VERSION ""

NS_ :

BS_:
BU_: AerodynamicControl AuxiliaryHeater1 AuxiliaryHeater2 AuxiliaryValveControl AxleDrive1 AxleDrive2 AxleSteering BodyController BrakesDriveAxle1 BrakesDriveAxle2 BrakesSteerAxle BrakesSystemController CabController1 CabController2 CabDisplay1 ChassisController1 ChassisController2 ClimateControl1 ClimateControl2 ClutchUnit CommunicationUnitCellular CommunicationUnitRadio CommunicationUnitSatellite CruiseControl ElectricalChargingSystem ElectricalSystem EnduranceBrakingSystem Engine1 Engine2 EngineValveControl ExhaustEmissionController FanDriveController FileServer FuelSystem HeadwayController HitchControl HydraulicPumpController IgnitionController1 IgnitionController2 InformationSystem1 InstrumentCluster LightingOperatorControl ManagementComputer Node_0 Node_1 Node_10 Node_11 Node_12 Node_129 Node_13 Node_130 Node_133 Node_14 Node_15 Node_16 Node_17 Node_18 Node_19 Node_2 Node_20 Node_21 Node_22 Node_23 Node_24 Node_248 Node_249 Node_25 Node_250 Node_251 Node_26 Node_27 Node_28 Node_29 Node_3 Node_30 Node_31 Node_32 Node_33 Node_34 Node_35 Node_36 Node_37 Node_38 Node_39 Node_4 Node_40 Node_41 Node_42 Node_43 Node_44 Node_45 Node_46 Node_47 Node_48 Node_49 Node_5 Node_50 Node_51 Node_52 Node_53 Node_54 Node_55 Node_56 Node_57 Node_58 Node_59 Node_6 Node_60 Node_61 Node_62 Node_63 Node_64 Node_65 Node_66 Node_67 Node_68 Node_69 Node_7 Node_70 Node_71 Node_72 Node_73 Node_74 Node_75 Node_76 Node_77 Node_78 Node_79 Node_8 Node_80 Node_9 OffBoardDiagnosticTool1 OffBoardDiagnosticTool2 OffVehicleGateway OilSensor OnBoardDataLogger OnBoardDiagnosticUnit ParkingBrakeController PneumaticSystemController PowerTakeOff PowerTakeOffFront PropulsionBatteryCharger RampControl RearAxleSteeringController RetarderDriveline RetarderEngine RetarderExhaustEngine1 RetarderExhaustEngine2 SeatControl2 SeatController1 ShiftConsolePrimary ShiftConsoleSecondary StarterSystem SteeringColumnUnit SteeringController SuspensionDriveAxle1 SuspensionDriveAxle2 SuspensionSteerAxle SuspensionSystemController1 SuspensionSystemController2 TirePressureController TractorTrailerBridge1 Transmission1 Transmission2 TransmissionDisplay1 TransmissionDisplay2 TripRecorder Turbocharger VehicleDynamicStability VehicleNavigation VehicleSecurity VirtualTerminal WaterPumpController
BO_ 2147483648 VECTOR__INDEPENDENT_SIG_MSG: 0 Vector__XXX
   SG_ TrailerWeight : 0|16@1+ (2,0) [0|128510] "kg" Vector__XXX
   SG_ ReferenceTirePressSetting : 0|8@1+ (8,0) [0|2000] "kPa" Vector__XXX
   SG_ ReferenceTirePress : 0|8@1+ (8,0) [0|2000] "kPa" Vector__XXX
   SG_ TirePressThresholdDetection : 0|3@1+ (1,0) [0|7] "" Vector__XXX
   SG_ TireAirLeakageRate : 0|16@1+ (0.1,0) [0|6425.5] "Pa/s" Vector__XXX
   SG_ CTIWheelEndElectricalFault : 0|2@1+ (1,0) [0|3] "" Vector__XXX
   SG_ CTITireStatus : 0|2@1+ (1,0) [0|3] "" Vector__XXX
   SG_ CTIWheelSensorStatus : 0|2@1+ (1,0) [0|3] "" Vector__XXX
   SG_ TireTemp : 0|16@1+ (0.03125,-273) [-273|1734.97] "deg C" Vector__XXX
   SG_ TirePress : 0|8@1+ (4,0) [0|1000] "kPa" Vector__XXX

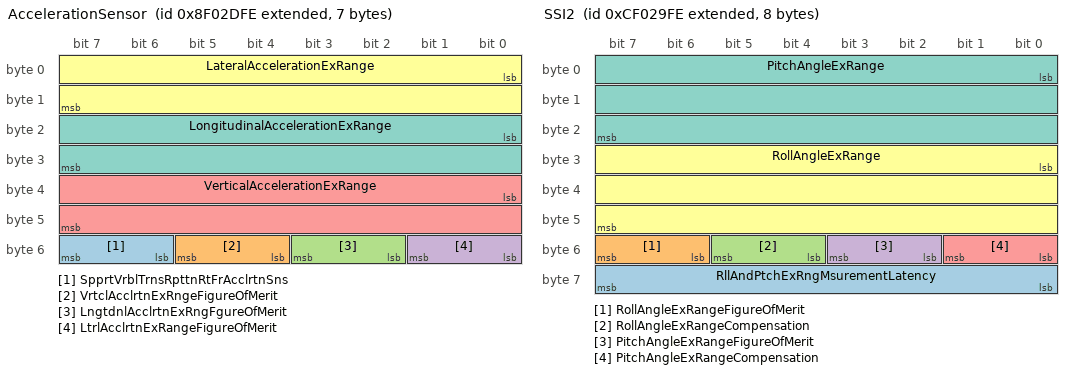
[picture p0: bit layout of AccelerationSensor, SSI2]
BO_ 2297441790 AccelerationSensor: 7 Vector__XXX
   SG_ SpprtVrblTrnsRpttnRtFrAcclrtnSns : 54|2@1+ (1,0) [0|3] "" Vector__XXX
   SG_ VrtclAcclrtnExRngeFigureOfMerit : 52|2@1+ (1,0) [0|3] "" Vector__XXX
   SG_ LngtdnlAcclrtnExRngFgureOfMerit : 50|2@1+ (1,0) [0|3] "" Vector__XXX
   SG_ LtrlAcclrtnExRangeFigureOfMerit : 48|2@1+ (1,0) [0|3] "" Vector__XXX
   SG_ VerticalAccelerationExRange : 32|16@1+ (0.01,-320) [-320|322.55] "m/s/s" Vector__XXX
   SG_ LateralAccelerationExRange : 0|16@1+ (0.01,-320) [-320|322.55] "m/s/s" Vector__XXX
   SG_ LongitudinalAccelerationExRange : 16|16@1+ (0.01,-320) [-320|322.55] "m/s/s" Vector__XXX

BO_ 2566712062 VEP4: 8 Vector__XXX
   SG_ HybrdBatteryPackRemainingCharge : 0|16@1+ (0.0025,0) [0|160.637] "%" Vector__XXX

BO_ 2364549630 SSI2: 8 Vector__XXX
   SG_ RllAndPtchExRngMsurementLatency : 56|8@1+ (0.5,0) [0|125] "ms" Vector__XXX
   SG_ RollAngleExRangeFigureOfMerit : 54|2@1+ (1,0) [0|3] "" Vector__XXX
   SG_ RollAngleExRangeCompensation : 52|2@1+ (1,0) [0|3] "" Vector__XXX
   SG_ PitchAngleExRangeFigureOfMerit : 50|2@1+ (1,0) [0|3] "" Vector__XXX
   SG_ PitchAngleExRangeCompensation : 48|2@1+ (1,0) [0|3] "" Vector__XXX
   SG_ RollAngleExRange : 24|24@1+ (3.05176e-05,-250) [-250|251] "deg" Vector__XXX
   SG_ PitchAngleExRange : 0|24@1+ (3.05176e-05,-250) [-250|251] "deg" Vector__XXX

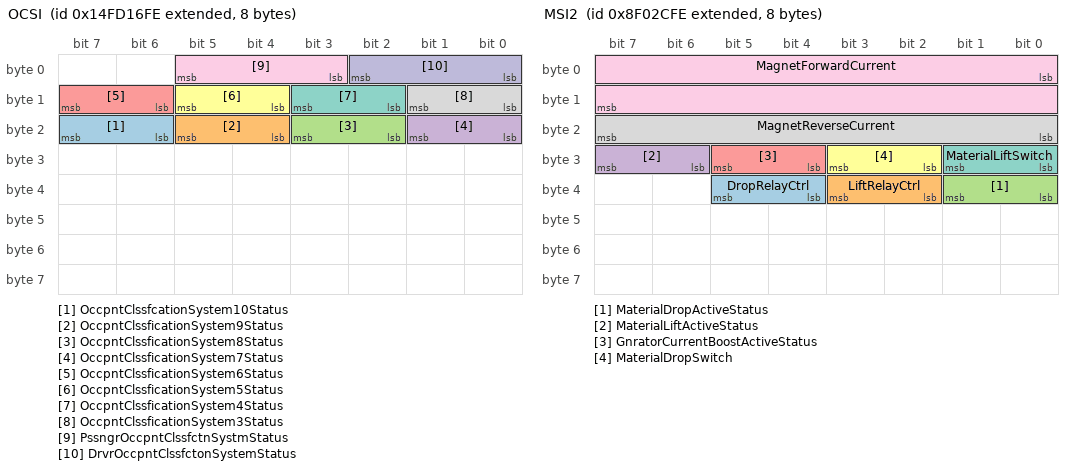
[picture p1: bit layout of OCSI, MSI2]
BO_ 2499614462 OCSI: 8 Vector__XXX
   SG_ OccpntClssfcationSystem10Status : 22|2@1+ (1,0) [0|3] "" Vector__XXX
   SG_ OccpntClssficationSystem9Status : 20|2@1+ (1,0) [0|3] "" Vector__XXX
   SG_ OccpntClssficationSystem8Status : 18|2@1+ (1,0) [0|3] "" Vector__XXX
   SG_ OccpntClssficationSystem7Status : 16|2@1+ (1,0) [0|3] "" Vector__XXX
   SG_ OccpntClssficationSystem6Status : 14|2@1+ (1,0) [0|3] "" Vector__XXX
   SG_ OccpntClssficationSystem5Status : 12|2@1+ (1,0) [0|3] "" Vector__XXX
   SG_ OccpntClssficationSystem4Status : 10|2@1+ (1,0) [0|3] "" Vector__XXX
   SG_ OccpntClssficationSystem3Status : 8|2@1+ (1,0) [0|3] "" Vector__XXX
   SG_ PssngrOccpntClssfctnSystmStatus : 3|3@1+ (1,0) [0|7] "" Vector__XXX
   SG_ DrvrOccpntClssfctonSystemStatus : 0|3@1+ (1,0) [0|7] "" Vector__XXX

BO_ 2560098046 NCS: 8 Vector__XXX
   SG_ CabNoiseCtrlTuningStatus : 2|4@1+ (1,0) [0|15] "" Vector__XXX
   SG_ CabNoiseCtrlStatus : 0|2@1+ (1,0) [0|3] "" Vector__XXX

BO_ 2560163582 NC1: 8 Vector__XXX
   SG_ CabNoiseCtrlTuningState : 2|3@1+ (1,0) [0|7] "" Vector__XXX
   SG_ CabNoiseCtrlState : 0|2@1+ (1,0) [0|3] "" Vector__XXX

BO_ 2297441534 MSI2: 8 Vector__XXX
   SG_ DropRelayCtrl : 36|2@1+ (1,0) [0|3] "" Vector__XXX
   SG_ LiftRelayCtrl : 34|2@1+ (1,0) [0|3] "" Vector__XXX
   SG_ MaterialDropActiveStatus : 32|2@1+ (1,0) [0|3] "" Vector__XXX
   SG_ MaterialLiftActiveStatus : 30|2@1+ (1,0) [0|3] "" Vector__XXX
   SG_ GnratorCurrentBoostActiveStatus : 28|2@1+ (1,0) [0|3] "" Vector__XXX
   SG_ MaterialDropSwitch : 26|2@1+ (1,0) [0|3] "" Vector__XXX
   SG_ MaterialLiftSwitch : 24|2@1+ (1,0) [0|3] "" Vector__XXX
   SG_ MagnetReverseCurrent : 16|8@1+ (1,0) [0|250] "A" Vector__XXX
   SG_ MagnetForwardCurrent : 0|16@1+ (1,0) [0|64255] "Amps" Vector__XXX

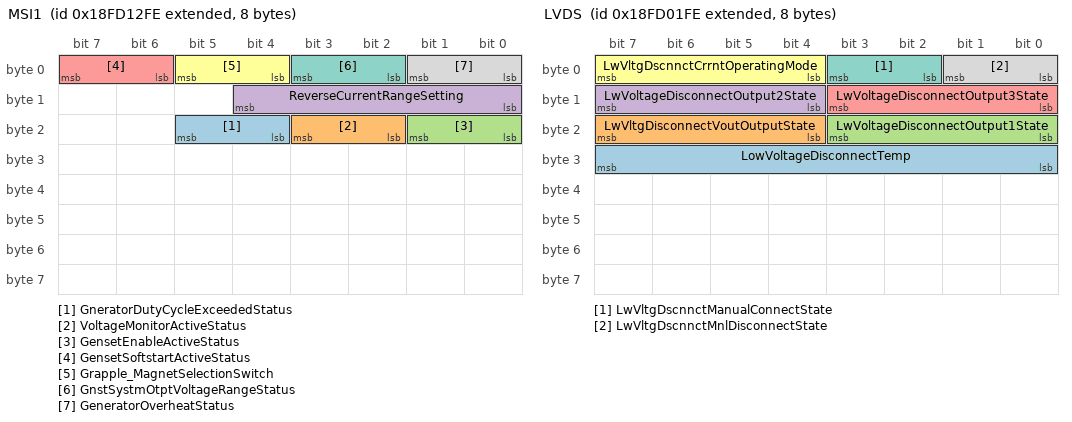
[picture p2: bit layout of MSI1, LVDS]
BO_ 2566722302 MSI1: 8 Vector__XXX
   SG_ GneratorDutyCycleExceededStatus : 20|2@1+ (1,0) [0|3] "" Vector__XXX
   SG_ VoltageMonitorActiveStatus : 18|2@1+ (1,0) [0|3] "" Vector__XXX
   SG_ GensetEnableActiveStatus : 16|2@1+ (1,0) [0|3] "" Vector__XXX
   SG_ ReverseCurrentRangeSetting : 8|5@1+ (1,0) [0|31] "" Vector__XXX
   SG_ GensetSoftstartActiveStatus : 6|2@1+ (1,0) [0|3] "" Vector__XXX
   SG_ Grapple_MagnetSelectionSwitch : 4|2@1+ (1,0) [0|3] "" Vector__XXX
   SG_ GnstSystmOtptVoltageRangeStatus : 2|2@1+ (1,0) [0|3] "" Vector__XXX
   SG_ GeneratorOverheatStatus : 0|2@1+ (1,0) [0|3] "" Vector__XXX

BO_ 2566722558 MSCI: 8 Vector__XXX
   SG_ MagnetRatedPower : 8|16@1+ (0.5,0) [0|32127.5] "kW" Vector__XXX
   SG_ MagnetBoostTime : 0|8@1+ (0.25,0) [0|62.5] "s" Vector__XXX

BO_ 2560032510 LVDSOM: 8 Vector__XXX
   SG_ LwVltgDscnnctDsredOperatingMode : 0|4@1+ (1,0) [0|15] "" Vector__XXX

BO_ 2566717950 LVDS: 8 Vector__XXX
   SG_ LowVoltageDisconnectTemp : 24|8@1+ (1,-40) [-40|210] "deg C" Vector__XXX
   SG_ LwVltgDisconnectVoutOutputState : 20|4@1+ (1,0) [0|15] "" Vector__XXX
   SG_ LwVoltageDisconnectOutput1State : 16|4@1+ (1,0) [0|15] "" Vector__XXX
   SG_ LwVoltageDisconnectOutput2State : 12|4@1+ (1,0) [0|15] "" Vector__XXX
   SG_ LwVoltageDisconnectOutput3State : 8|4@1+ (1,0) [0|15] "" Vector__XXX
   SG_ LwVltgDscnnctCrrntOperatingMode : 4|4@1+ (1,0) [0|15] "" Vector__XXX
   SG_ LwVltgDscnnctManualConnectState : 2|2@1+ (1,0) [0|3] "" Vector__XXX
   SG_ LwVltgDscnnctMnlDisconnectState : 0|2@1+ (1,0) [0|3] "" Vector__XXX

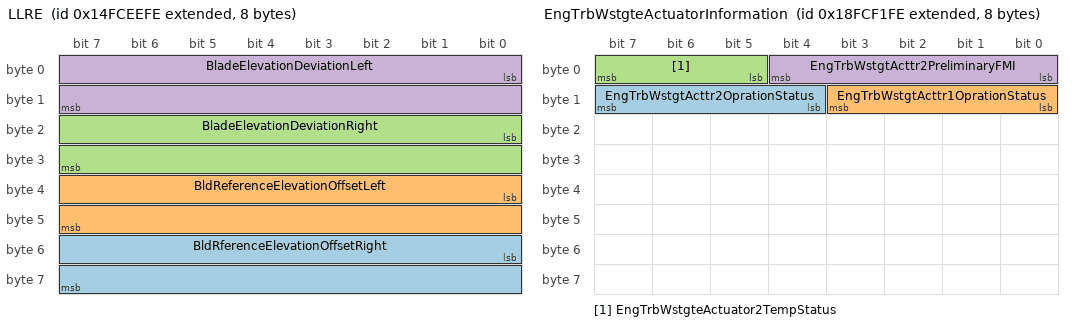
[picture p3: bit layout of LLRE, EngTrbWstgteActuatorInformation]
BO_ 2499604222 LLRE: 8 Vector__XXX
   SG_ BldRferenceElevationOffsetRight : 48|16@1+ (1,-32000) [-32000|32255] "mm" Vector__XXX
   SG_ BldReferenceElevationOffsetLeft : 32|16@1+ (1,-32000) [-32000|32255] "mm" Vector__XXX
   SG_ BladeElevationDeviationRight : 16|16@1+ (1,-32000) [-32000|32255] "mm" Vector__XXX
   SG_ BladeElevationDeviationLeft : 0|16@1+ (1,-32000) [-32000|32255] "mm" Vector__XXX

BO_ 2358902526 JLCM: 8 Vector__XXX
   SG_ Joystick3Lamp10Cmd : 58|2@1+ (1,0) [0|3] "" Vector__XXX
   SG_ Joystick3Lamp9Cmd : 56|2@1+ (1,0) [0|3] "" Vector__XXX
   SG_ Joystick3Lamp8Cmd : 54|2@1+ (1,0) [0|3] "" Vector__XXX
   SG_ Joystick3Lamp7Cmd : 52|2@1+ (1,0) [0|3] "" Vector__XXX
   SG_ Joystick3Lamp6Cmd : 50|2@1+ (1,0) [0|3] "" Vector__XXX
   SG_ Joystick3Lamp5Cmd : 48|2@1+ (1,0) [0|3] "" Vector__XXX
   SG_ Joystick3Lamp4Cmd : 46|2@1+ (1,0) [0|3] "" Vector__XXX
   SG_ Joystick3Lamp3Cmd : 44|2@1+ (1,0) [0|3] "" Vector__XXX
   SG_ Joystick3Lamp2Cmd : 42|2@1+ (1,0) [0|3] "" Vector__XXX
   SG_ Joystick3Lamp1Cmd : 40|2@1+ (1,0) [0|3] "" Vector__XXX
   SG_ Joystick2Lamp10Cmd : 38|2@1+ (1,0) [0|3] "" Vector__XXX
   SG_ Joystick2Lamp9Cmd : 36|2@1+ (1,0) [0|3] "" Vector__XXX
   SG_ Joystick2Lamp8Cmd : 34|2@1+ (1,0) [0|3] "" Vector__XXX
   SG_ Joystick2Lamp7Cmd : 32|2@1+ (1,0) [0|3] "" Vector__XXX
   SG_ Joystick2Lamp6Cmd : 30|2@1+ (1,0) [0|3] "" Vector__XXX
   SG_ Joystick2Lamp5Cmd : 28|2@1+ (1,0) [0|3] "" Vector__XXX
   SG_ Joystick2Lamp4Cmd : 26|2@1+ (1,0) [0|3] "" Vector__XXX
   SG_ Joystick2Lamp3Cmd : 24|2@1+ (1,0) [0|3] "" Vector__XXX
   SG_ Joystick2Lamp2Cmd : 22|2@1+ (1,0) [0|3] "" Vector__XXX
   SG_ Joystick2Lamp1Cmd : 20|2@1+ (1,0) [0|3] "" Vector__XXX
   SG_ Joystick1Lamp10Cmd : 18|2@1+ (1,0) [0|3] "" Vector__XXX
   SG_ Joystick1Lamp9Cmd : 16|2@1+ (1,0) [0|3] "" Vector__XXX
   SG_ Joystick1Lamp8Cmd : 14|2@1+ (1,0) [0|3] "" Vector__XXX
   SG_ Joystick1Lamp7Cmd : 12|2@1+ (1,0) [0|3] "" Vector__XXX
   SG_ Joystick1Lamp6Cmd : 10|2@1+ (1,0) [0|3] "" Vector__XXX
   SG_ Joystick1Lamp5Cmd : 8|2@1+ (1,0) [0|3] "" Vector__XXX
   SG_ Joystick1Lamp4Cmd : 6|2@1+ (1,0) [0|3] "" Vector__XXX
   SG_ Joystick1Lamp3Cmd : 4|2@1+ (1,0) [0|3] "" Vector__XXX
   SG_ Joystick1Lamp2Cmd : 2|2@1+ (1,0) [0|3] "" Vector__XXX
   SG_ Joystick1Lamp1Cmd : 0|2@1+ (1,0) [0|3] "" Vector__XXX

BO_ 2566711550 IVAC: 8 Vector__XXX
   SG_ IntkVlvActtnSystmOlPrss2SlndCtrl : 2|2@1+ (1,0) [0|3] "" Vector__XXX
   SG_ IntkVlvActtnSystmOlPrss1SlndCtrl : 0|2@1+ (1,0) [0|3] "" Vector__XXX

BO_ 2633832958 ILI: 200 Vector__XXX
   SG_ SpecialIgnitorLoop90Resistance : 1584|16@1+ (0.1,0) [0|6425.5] "ohm" Vector__XXX
   SG_ SpecialIgnitorLoop89Resistance : 1568|16@1+ (0.1,0) [0|6425.5] "ohm" Vector__XXX
   SG_ SpecialIgnitorLoop88Resistance : 1552|16@1+ (0.1,0) [0|6425.5] "ohm" Vector__XXX
   SG_ SpecialIgnitorLoop87Resistance : 1536|16@1+ (0.1,0) [0|6425.5] "ohm" Vector__XXX
   SG_ SpecialIgnitorLoop86Resistance : 1520|16@1+ (0.1,0) [0|6425.5] "ohm" Vector__XXX
   SG_ SpecialIgnitorLoop85Resistance : 1504|16@1+ (0.1,0) [0|6425.5] "ohm" Vector__XXX
   SG_ SpecialIgnitorLoop84Resistance : 1488|16@1+ (0.1,0) [0|6425.5] "ohm" Vector__XXX
   SG_ SpecialIgnitorLoop83Resistance : 1472|16@1+ (0.1,0) [0|6425.5] "ohm" Vector__XXX
   SG_ SpecialIgnitorLoop82Resistance : 1456|16@1+ (0.1,0) [0|6425.5] "ohm" Vector__XXX
   SG_ SpecialIgnitorLoop81Resistance : 1440|16@1+ (0.1,0) [0|6425.5] "ohm" Vector__XXX
   SG_ SpecialIgnitorLoop80Resistance : 1424|16@1+ (0.1,0) [0|6425.5] "ohm" Vector__XXX
   SG_ SpecialIgnitorLoop79Resistance : 1408|16@1+ (0.1,0) [0|6425.5] "ohm" Vector__XXX
   SG_ SpecialIgnitorLoop78Resistance : 1392|16@1+ (0.1,0) [0|6425.5] "ohm" Vector__XXX
   SG_ SpecialIgnitorLoop77Resistance : 1376|16@1+ (0.1,0) [0|6425.5] "ohm" Vector__XXX
   SG_ SpecialIgnitorLoop76Resistance : 1360|16@1+ (0.1,0) [0|6425.5] "ohm" Vector__XXX
   SG_ SpecialIgnitorLoop75Resistance : 1344|16@1+ (0.1,0) [0|6425.5] "ohm" Vector__XXX
   SG_ SpecialIgnitorLoop74Resistance : 1328|16@1+ (0.1,0) [0|6425.5] "ohm" Vector__XXX
   SG_ SpecialIgnitorLoop73Resistance : 1312|16@1+ (0.1,0) [0|6425.5] "ohm" Vector__XXX
   SG_ SpecialIgnitorLoop72Resistance : 1296|16@1+ (0.1,0) [0|6425.5] "ohm" Vector__XXX
   SG_ SpecialIgnitorLoop71Resistance : 1280|16@1+ (0.1,0) [0|6425.5] "ohm" Vector__XXX
   SG_ SpecialIgnitorLoop70Resistance : 1264|16@1+ (0.1,0) [0|6425.5] "ohm" Vector__XXX
   SG_ SpecialIgnitorLoop69Resistance : 1248|16@1+ (0.1,0) [0|6425.5] "ohm" Vector__XXX
   SG_ SpecialIgnitorLoop68Resistance : 1232|16@1+ (0.1,0) [0|6425.5] "ohm" Vector__XXX
   SG_ SpecialIgnitorLoop67Resistance : 1216|16@1+ (0.1,0) [0|6425.5] "ohm" Vector__XXX
   SG_ SpecialIgnitorLoop66Resistance : 1200|16@1+ (0.1,0) [0|6425.5] "ohm" Vector__XXX
   SG_ SpecialIgnitorLoop65Resistance : 1184|16@1+ (0.1,0) [0|6425.5] "ohm" Vector__XXX
   SG_ SpecialIgnitorLoop64Resistance : 1168|16@1+ (0.1,0) [0|6425.5] "ohm" Vector__XXX
   SG_ SpecialIgnitorLoop63Resistance : 1152|16@1+ (0.1,0) [0|6425.5] "ohm" Vector__XXX
   SG_ SpecialIgnitorLoop61Resistance : 1120|16@1+ (0.1,0) [0|6425.5] "ohm" Vector__XXX
   SG_ SpecialIgnitorLoop60Resistance : 1104|16@1+ (0.1,0) [0|6425.5] "ohm" Vector__XXX
   SG_ SpecialIgnitorLoop59Resistance : 1088|16@1+ (0.1,0) [0|6425.5] "ohm" Vector__XXX
   SG_ SpecialIgnitorLoop58Resistance : 1072|16@1+ (0.1,0) [0|6425.5] "ohm" Vector__XXX
   SG_ SpecialIgnitorLoop57Resistance : 1056|16@1+ (0.1,0) [0|6425.5] "ohm" Vector__XXX
   SG_ SpecialIgnitorLoop56Resistance : 1040|16@1+ (0.1,0) [0|6425.5] "ohm" Vector__XXX
   SG_ SpecialIgnitorLoop55Resistance : 1024|16@1+ (0.1,0) [0|6425.5] "ohm" Vector__XXX
   SG_ SpecialIgnitorLoop54Resistance : 1008|16@1+ (0.1,0) [0|6425.5] "ohm" Vector__XXX
   SG_ SpecialIgnitorLoop53Resistance : 992|16@1+ (0.1,0) [0|6425.5] "ohm" Vector__XXX
   SG_ SpecialIgnitorLoop52Resistance : 976|16@1+ (0.1,0) [0|6425.5] "ohm" Vector__XXX
   SG_ SpecialIgnitorLoop51Resistance : 960|16@1+ (0.1,0) [0|6425.5] "ohm" Vector__XXX
   SG_ SpecialIgnitorLoop50Resistance : 944|16@1+ (0.1,0) [0|6425.5] "ohm" Vector__XXX
   SG_ SpecialIgnitorLoop49Resistance : 928|16@1+ (0.1,0) [0|6425.5] "ohm" Vector__XXX
   SG_ SpecialIgnitorLoop48Resistance : 912|16@1+ (0.1,0) [0|6425.5] "ohm" Vector__XXX
   SG_ SpecialIgnitorLoop47Resistance : 896|16@1+ (0.1,0) [0|6425.5] "ohm" Vector__XXX
   SG_ SpecialIgnitorLoop46Resistance : 880|16@1+ (0.1,0) [0|6425.5] "ohm" Vector__XXX
   SG_ SpecialIgnitorLoop45Resistance : 864|16@1+ (0.1,0) [0|6425.5] "ohm" Vector__XXX
   SG_ SpecialIgnitorLoop44Resistance : 848|16@1+ (0.1,0) [0|6425.5] "ohm" Vector__XXX
   SG_ SpecialIgnitorLoop43Resistance : 832|16@1+ (0.1,0) [0|6425.5] "ohm" Vector__XXX
   SG_ SpecialIgnitorLoop42Resistance : 816|16@1+ (0.1,0) [0|6425.5] "ohm" Vector__XXX
   SG_ SpecialIgnitorLoop41Resistance : 800|16@1+ (0.1,0) [0|6425.5] "ohm" Vector__XXX
   SG_ SpecialIgnitorLoop40Resistance : 784|16@1+ (0.1,0) [0|6425.5] "ohm" Vector__XXX
   SG_ SpecialIgnitorLoop39Resistance : 768|16@1+ (0.1,0) [0|6425.5] "ohm" Vector__XXX
   SG_ SpecialIgnitorLoop38Resistance : 752|16@1+ (0.1,0) [0|6425.5] "ohm" Vector__XXX
   SG_ SpecialIgnitorLoop37Resistance : 736|16@1+ (0.1,0) [0|6425.5] "ohm" Vector__XXX
   SG_ SpecialIgnitorLoop36Resistance : 720|16@1+ (0.1,0) [0|6425.5] "ohm" Vector__XXX
   SG_ SpecialIgnitorLoop35Resistance : 704|16@1+ (0.1,0) [0|6425.5] "ohm" Vector__XXX
   SG_ SpecialIgnitorLoop34Resistance : 688|16@1+ (0.1,0) [0|6425.5] "ohm" Vector__XXX
   SG_ SpecialIgnitorLoop33Resistance : 672|16@1+ (0.1,0) [0|6425.5] "ohm" Vector__XXX
   SG_ SpecialIgnitorLoop32Resistance : 656|16@1+ (0.1,0) [0|6425.5] "ohm" Vector__XXX
   SG_ SpecialIgnitorLoop31Resistance : 640|16@1+ (0.1,0) [0|6425.5] "ohm" Vector__XXX
   SG_ SpecialIgnitorLoop30Resistance : 624|16@1+ (0.1,0) [0|6425.5] "ohm" Vector__XXX
   SG_ SpecialIgnitorLoop29Resistance : 608|16@1+ (0.1,0) [0|6425.5] "ohm" Vector__XXX
   SG_ SpecialIgnitorLoop28Resistance : 592|16@1+ (0.1,0) [0|6425.5] "ohm" Vector__XXX
   SG_ SpecialIgnitorLoop27Resistance : 576|16@1+ (0.1,0) [0|6425.5] "ohm" Vector__XXX
   SG_ SpecialIgnitorLoop26Resistance : 560|16@1+ (0.1,0) [0|6425.5] "ohm" Vector__XXX
   SG_ SpecialIgnitorLoop25Resistance : 544|16@1+ (0.1,0) [0|6425.5] "ohm" Vector__XXX
   SG_ SpecialIgnitorLoop24Resistance : 528|16@1+ (0.1,0) [0|6425.5] "ohm" Vector__XXX
   SG_ SpecialIgnitorLoop23Resistance : 512|16@1+ (0.1,0) [0|6425.5] "ohm" Vector__XXX
   SG_ SpecialIgnitorLoop22Resistance : 496|16@1+ (0.1,0) [0|6425.5] "ohm" Vector__XXX
   SG_ SpecialIgnitorLoop21Resistance : 480|16@1+ (0.1,0) [0|6425.5] "ohm" Vector__XXX
   SG_ SpecialIgnitorLoop20Resistance : 464|16@1+ (0.1,0) [0|6425.5] "ohm" Vector__XXX
   SG_ SpecialIgnitorLoop19Resistance : 448|16@1+ (0.1,0) [0|6425.5] "ohm" Vector__XXX
   SG_ SpecialIgnitorLoop18Resistance : 432|16@1+ (0.1,0) [0|6425.5] "ohm" Vector__XXX
   SG_ SpecialIgnitorLoop17Resistance : 416|16@1+ (0.1,0) [0|6425.5] "ohm" Vector__XXX
   SG_ SpecialIgnitorLoop16Resistance : 400|16@1+ (0.1,0) [0|6425.5] "ohm" Vector__XXX
   SG_ SpecialIgnitorLoop15Resistance : 384|16@1+ (0.1,0) [0|6425.5] "ohm" Vector__XXX
   SG_ SpecialIgnitorLoop14Resistance : 368|16@1+ (0.1,0) [0|6425.5] "ohm" Vector__XXX
   SG_ SpecialIgnitorLoop13Resistance : 352|16@1+ (0.1,0) [0|6425.5] "ohm" Vector__XXX
   SG_ SpecialIgnitorLoop12Resistance : 336|16@1+ (0.1,0) [0|6425.5] "ohm" Vector__XXX
   SG_ SpecialIgnitorLoop11Resistance : 320|16@1+ (0.1,0) [0|6425.5] "ohm" Vector__XXX
   SG_ SpecialIgnitorLoop10Resistance : 304|16@1+ (0.1,0) [0|6425.5] "ohm" Vector__XXX
   SG_ SpecialIgnitorLoop9Resistance : 288|16@1+ (0.1,0) [0|6425.5] "ohm" Vector__XXX
   SG_ SpecialIgnitorLoop8Resistance : 272|16@1+ (0.1,0) [0|6425.5] "ohm" Vector__XXX
   SG_ SpecialIgnitorLoop7Resistance : 256|16@1+ (0.1,0) [0|6425.5] "ohm" Vector__XXX
   SG_ SpecialIgnitorLoop6Resistance : 240|16@1+ (0.1,0) [0|6425.5] "ohm" Vector__XXX
   SG_ SpecialIgnitorLoop5Resistance : 224|16@1+ (0.1,0) [0|6425.5] "ohm" Vector__XXX
   SG_ SpecialIgnitorLoop4Resistance : 208|16@1+ (0.1,0) [0|6425.5] "ohm" Vector__XXX
   SG_ SpecialIgnitorLoop3Resistance : 192|16@1+ (0.1,0) [0|6425.5] "ohm" Vector__XXX
   SG_ SpecialIgnitorLoop2Resistance : 176|16@1+ (0.1,0) [0|6425.5] "ohm" Vector__XXX
   SG_ SpecialIgnitorLoop1Resistance : 160|16@1+ (0.1,0) [0|6425.5] "ohm" Vector__XXX
   SG_ SdBgIgnitorLoop2RightResistance : 144|16@1+ (0.1,0) [0|6425.5] "ohm" Vector__XXX
   SG_ SdBgIgnitorLoop1RightResistance : 128|16@1+ (0.1,0) [0|6425.5] "ohm" Vector__XXX
   SG_ SdBagIgnitorLoop2LeftResistance : 112|16@1+ (0.1,0) [0|6425.5] "ohm" Vector__XXX
   SG_ SdBagIgnitorLoop1LeftResistance : 96|16@1+ (0.1,0) [0|6425.5] "ohm" Vector__XXX
   SG_ PssngrBltTnsnrIgntrLpResistance : 80|16@1+ (0.1,0) [0|6425.5] "ohm" Vector__XXX
   SG_ DrvrBltTnsnrIgntrLoopResistance : 64|16@1+ (0.1,0) [0|6425.5] "ohm" Vector__XXX
   SG_ PssngrArbgIgntrLp2ndStgRsstance : 48|16@1+ (0.1,0) [0|6425.5] "ohm" Vector__XXX
   SG_ DrvrArbgIgntrLp2ndStgResistance : 32|16@1+ (0.1,0) [0|6425.5] "ohm" Vector__XXX
   SG_ PssngrArbgIgntrLp1stStgRsstance : 16|16@1+ (0.1,0) [0|6425.5] "ohm" Vector__XXX
   SG_ DrvrArbgIgntrLp1stStgResistance : 0|16@1+ (0.1,0) [0|6425.5] "ohm" Vector__XXX

BO_ 2566719998 HRLFC: 8 Vector__XXX
   SG_ HighResolutionEngTotalFuelUsed : 32|32@1+ (0.001,0) [0|4.21108e+06] "L" Vector__XXX
   SG_ HighResolutionEngTripFuel : 0|32@1+ (0.001,0) [0|4.21108e+06] "L" Vector__XXX

BO_ 2565877502 EngTrboWastegateActuatorCtrlCmd: 8 Vector__XXX
   SG_ EngTurboWastegateActuator2Cmd : 16|16@1+ (0.0025,0) [0|160.637] "%" Vector__XXX
   SG_ EngTurboWastegateActuator1Cmd : 0|16@1+ (0.0025,0) [0|160.637] "%" Vector__XXX

BO_ 2566713854 EngTrbWstgteActuatorInformation: 8 Vector__XXX
   SG_ EngTrbWstgtActtr2OprationStatus : 12|4@1+ (1,0) [0|15] "" Vector__XXX
   SG_ EngTrbWstgtActtr1OprationStatus : 8|4@1+ (1,0) [0|15] "" Vector__XXX
   SG_ EngTrbWstgteActuator2TempStatus : 5|3@1+ (1,0) [0|7] "" Vector__XXX
   SG_ EngTrbWstgtActtr2PreliminaryFMI : 0|5@1+ (1,0) [0|31] "" Vector__XXX

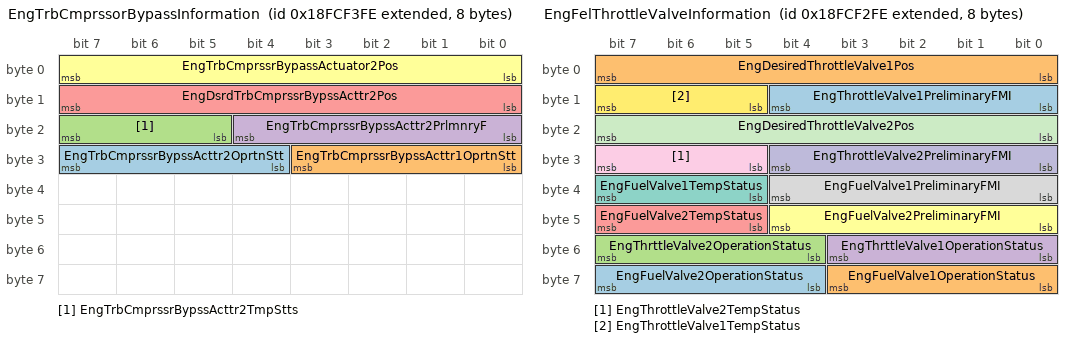
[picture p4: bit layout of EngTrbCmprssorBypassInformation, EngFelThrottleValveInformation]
BO_ 2566714366 EngTrbCmprssorBypassInformation: 8 Vector__XXX
   SG_ EngTrbCmprssrBypssActtr2OprtnStt : 28|4@1+ (1,0) [0|15] "" Vector__XXX
   SG_ EngTrbCmprssrBypssActtr1OprtnStt : 24|4@1+ (1,0) [0|15] "" Vector__XXX
   SG_ EngTrbCmprssrBypssActtr2TmpStts : 21|3@1+ (1,0) [0|7] "" Vector__XXX
   SG_ EngTrbCmprssrBypssActtr2PrlmnryF : 16|5@1+ (1,0) [0|31] "" Vector__XXX
   SG_ EngDsrdTrbCmprssrBypssActtr2Pos : 8|8@1+ (0.4,0) [0|100] "%" Vector__XXX
   SG_ EngTrbCmprssrBypassActuator2Pos : 0|8@1+ (0.4,0) [0|100] "%" Vector__XXX

BO_ 2566714110 EngFelThrottleValveInformation: 8 Vector__XXX
   SG_ EngFuelValve2OperationStatus : 60|4@1+ (1,0) [0|15] "" Vector__XXX
   SG_ EngFuelValve1OperationStatus : 56|4@1+ (1,0) [0|15] "" Vector__XXX
   SG_ EngThrttleValve2OperationStatus : 52|4@1+ (1,0) [0|15] "" Vector__XXX
   SG_ EngThrttleValve1OperationStatus : 48|4@1+ (1,0) [0|15] "" Vector__XXX
   SG_ EngFuelValve2TempStatus : 45|3@1+ (1,0) [0|7] "" Vector__XXX
   SG_ EngFuelValve2PreliminaryFMI : 40|5@1+ (1,0) [0|31] "" Vector__XXX
   SG_ EngFuelValve1TempStatus : 37|3@1+ (1,0) [0|7] "" Vector__XXX
   SG_ EngFuelValve1PreliminaryFMI : 32|5@1+ (1,0) [0|31] "" Vector__XXX
   SG_ EngThrottleValve2TempStatus : 29|3@1+ (1,0) [0|7] "" Vector__XXX
   SG_ EngThrottleValve2PreliminaryFMI : 24|5@1+ (1,0) [0|31] "" Vector__XXX
   SG_ EngDesiredThrottleValve2Pos : 16|8@1+ (0.4,0) [0|100] "%" Vector__XXX
   SG_ EngThrottleValve1TempStatus : 13|3@1+ (1,0) [0|7] "" Vector__XXX
   SG_ EngThrottleValve1PreliminaryFMI : 8|5@1+ (1,0) [0|31] "" Vector__XXX
   SG_ EngDesiredThrottleValve1Pos : 0|8@1+ (0.4,0) [0|100] "%" Vector__XXX

BO_ 2566717438 ET5: 8 Vector__XXX
   SG_ EngExhstGsRcrcltn2MxrIntakeTemp : 16|16@1+ (0.03125,-273) [-273|1734.97] "deg C" Vector__XXX
   SG_ EngExhaustGasRecirculation2Temp : 0|16@1+ (0.03125,-273) [-273|1734.97] "deg C" Vector__XXX

BO_ 2633828606 EOM: 8 Vector__XXX
   SG_ EngOilRelativeDielectricity : 32|16@1+ (0.00012207,0) [0|7.844] "" Vector__XXX
   SG_ EngOilDensity : 16|16@1+ (3.052e-05,0) [0|1.961] "g/cc" Vector__XXX
   SG_ EngOilViscosity : 0|16@1+ (0.015625,0) [0|1003.98] "Cp" Vector__XXX

BO_ 2499607550 EMAP: 8 Vector__XXX
   SG_ EngExhstMnfldBnk2FlwBlncVlvActtr : 16|16@1+ (0.0025,0) [0|160.637] "%" Vector__XXX
   SG_ EngExhstMnfldBnk1FlwBlncVlvActtr : 0|16@1+ (0.0025,0) [0|160.637] "%" Vector__XXX

BO_ 2633825534 EMAC: 8 Vector__XXX
   SG_ EngExhstMnfldBnk2FlwBlncVlv_0000 : 16|16@1+ (0.0025,0) [0|160.637] "%" Vector__XXX
   SG_ EngExhstMnfldBnk1FlwBlncVlv_0000 : 0|16@1+ (0.0025,0) [0|160.637] "%" Vector__XXX

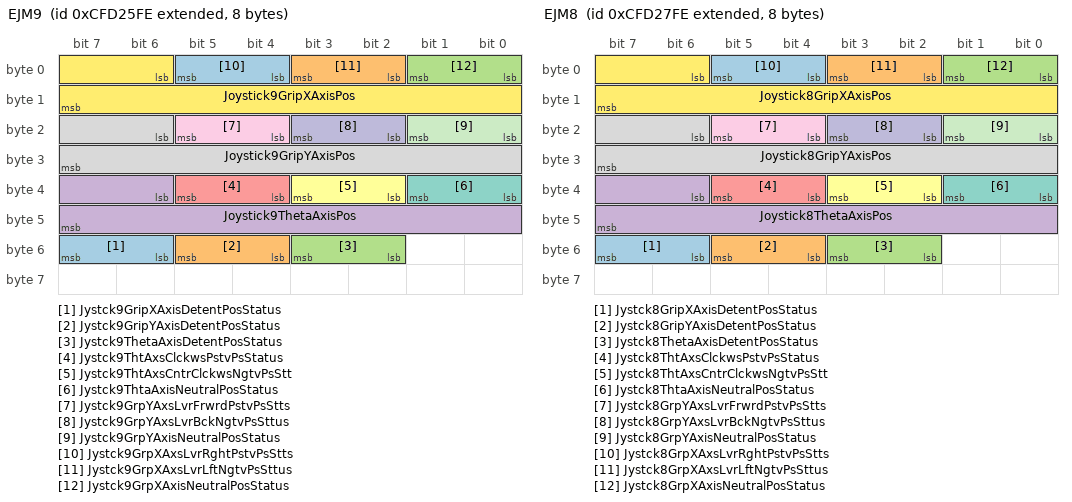
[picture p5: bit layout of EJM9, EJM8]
BO_ 2365400574 EJM9: 8 Vector__XXX
   SG_ Jystck9GripXAxisDetentPosStatus : 54|2@1+ (1,0) [0|3] "" Vector__XXX
   SG_ Jystck9GripYAxisDetentPosStatus : 52|2@1+ (1,0) [0|3] "" Vector__XXX
   SG_ Jystck9ThetaAxisDetentPosStatus : 50|2@1+ (1,0) [0|3] "" Vector__XXX
   SG_ Joystick9ThetaAxisPos : 38|10@1+ (0.1,0) [0|102] "%" Vector__XXX
   SG_ Jystck9ThtAxsClckwsPstvPsStatus : 36|2@1+ (1,0) [0|3] "" Vector__XXX
   SG_ Jystck9ThtAxsCntrClckwsNgtvPsStt : 34|2@1+ (1,0) [0|3] "" Vector__XXX
   SG_ Jystck9ThtaAxisNeutralPosStatus : 32|2@1+ (1,0) [0|3] "" Vector__XXX
   SG_ Joystick9GripYAxisPos : 22|10@1+ (0.1,0) [0|102] "%" Vector__XXX
   SG_ Jystck9GrpYAxsLvrFrwrdPstvPsStts : 20|2@1+ (1,0) [0|3] "" Vector__XXX
   SG_ Jystck9GrpYAxsLvrBckNgtvPsSttus : 18|2@1+ (1,0) [0|3] "" Vector__XXX
   SG_ Jystck9GrpYAxisNeutralPosStatus : 16|2@1+ (1,0) [0|3] "" Vector__XXX
   SG_ Joystick9GripXAxisPos : 6|10@1+ (0.1,0) [0|102] "%" Vector__XXX
   SG_ Jystck9GrpXAxsLvrRghtPstvPsStts : 4|2@1+ (1,0) [0|3] "" Vector__XXX
   SG_ Jystck9GrpXAxsLvrLftNgtvPsSttus : 2|2@1+ (1,0) [0|3] "" Vector__XXX
   SG_ Jystck9GrpXAxisNeutralPosStatus : 0|2@1+ (1,0) [0|3] "" Vector__XXX

BO_ 2365401086 EJM8: 8 Vector__XXX
   SG_ Jystck8GripXAxisDetentPosStatus : 54|2@1+ (1,0) [0|3] "" Vector__XXX
   SG_ Jystck8GripYAxisDetentPosStatus : 52|2@1+ (1,0) [0|3] "" Vector__XXX
   SG_ Jystck8ThetaAxisDetentPosStatus : 50|2@1+ (1,0) [0|3] "" Vector__XXX
   SG_ Joystick8ThetaAxisPos : 38|10@1+ (0.1,0) [0|102] "%" Vector__XXX
   SG_ Jystck8ThtAxsClckwsPstvPsStatus : 36|2@1+ (1,0) [0|3] "" Vector__XXX
   SG_ Jystck8ThtAxsCntrClckwsNgtvPsStt : 34|2@1+ (1,0) [0|3] "" Vector__XXX
   SG_ Jystck8ThtaAxisNeutralPosStatus : 32|2@1+ (1,0) [0|3] "" Vector__XXX
   SG_ Joystick8GripYAxisPos : 22|10@1+ (0.1,0) [0|102] "%" Vector__XXX
   SG_ Jystck8GrpYAxsLvrFrwrdPstvPsStts : 20|2@1+ (1,0) [0|3] "" Vector__XXX
   SG_ Jystck8GrpYAxsLvrBckNgtvPsSttus : 18|2@1+ (1,0) [0|3] "" Vector__XXX
   SG_ Jystck8GrpYAxisNeutralPosStatus : 16|2@1+ (1,0) [0|3] "" Vector__XXX
   SG_ Joystick8GripXAxisPos : 6|10@1+ (0.1,0) [0|102] "%" Vector__XXX
   SG_ Jystck8GrpXAxsLvrRghtPstvPsStts : 4|2@1+ (1,0) [0|3] "" Vector__XXX
   SG_ Jystck8GrpXAxsLvrLftNgtvPsSttus : 2|2@1+ (1,0) [0|3] "" Vector__XXX
   SG_ Jystck8GrpXAxisNeutralPosStatus : 0|2@1+ (1,0) [0|3] "" Vector__XXX

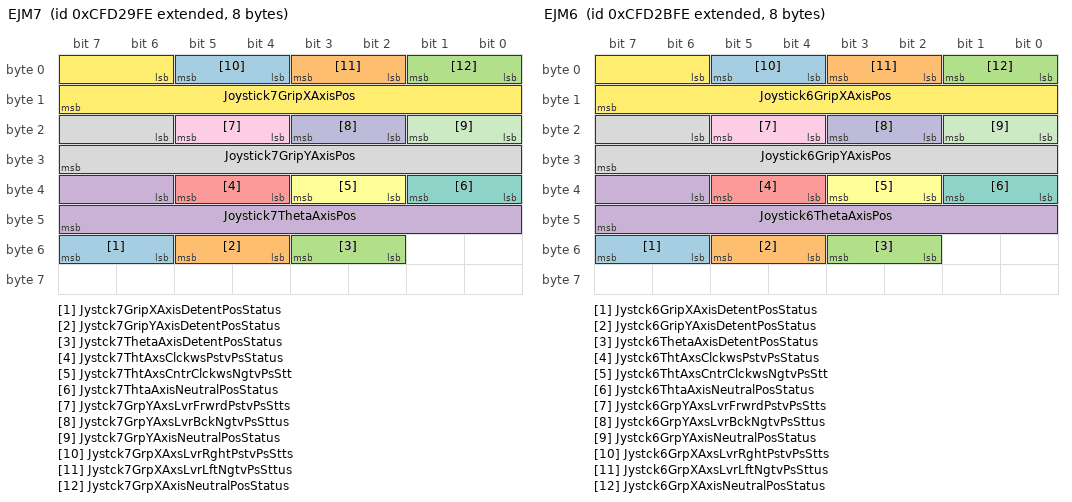
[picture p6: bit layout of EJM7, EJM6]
BO_ 2365401598 EJM7: 8 Vector__XXX
   SG_ Jystck7GripXAxisDetentPosStatus : 54|2@1+ (1,0) [0|3] "" Vector__XXX
   SG_ Jystck7GripYAxisDetentPosStatus : 52|2@1+ (1,0) [0|3] "" Vector__XXX
   SG_ Jystck7ThetaAxisDetentPosStatus : 50|2@1+ (1,0) [0|3] "" Vector__XXX
   SG_ Joystick7ThetaAxisPos : 38|10@1+ (0.1,0) [0|102] "%" Vector__XXX
   SG_ Jystck7ThtAxsClckwsPstvPsStatus : 36|2@1+ (1,0) [0|3] "" Vector__XXX
   SG_ Jystck7ThtAxsCntrClckwsNgtvPsStt : 34|2@1+ (1,0) [0|3] "" Vector__XXX
   SG_ Jystck7ThtaAxisNeutralPosStatus : 32|2@1+ (1,0) [0|3] "" Vector__XXX
   SG_ Joystick7GripYAxisPos : 22|10@1+ (0.1,0) [0|102] "%" Vector__XXX
   SG_ Jystck7GrpYAxsLvrFrwrdPstvPsStts : 20|2@1+ (1,0) [0|3] "" Vector__XXX
   SG_ Jystck7GrpYAxsLvrBckNgtvPsSttus : 18|2@1+ (1,0) [0|3] "" Vector__XXX
   SG_ Jystck7GrpYAxisNeutralPosStatus : 16|2@1+ (1,0) [0|3] "" Vector__XXX
   SG_ Joystick7GripXAxisPos : 6|10@1+ (0.1,0) [0|102] "%" Vector__XXX
   SG_ Jystck7GrpXAxsLvrRghtPstvPsStts : 4|2@1+ (1,0) [0|3] "" Vector__XXX
   SG_ Jystck7GrpXAxsLvrLftNgtvPsSttus : 2|2@1+ (1,0) [0|3] "" Vector__XXX
   SG_ Jystck7GrpXAxisNeutralPosStatus : 0|2@1+ (1,0) [0|3] "" Vector__XXX

BO_ 2365402110 EJM6: 8 Vector__XXX
   SG_ Jystck6GripXAxisDetentPosStatus : 54|2@1+ (1,0) [0|3] "" Vector__XXX
   SG_ Jystck6GripYAxisDetentPosStatus : 52|2@1+ (1,0) [0|3] "" Vector__XXX
   SG_ Jystck6ThetaAxisDetentPosStatus : 50|2@1+ (1,0) [0|3] "" Vector__XXX
   SG_ Joystick6ThetaAxisPos : 38|10@1+ (0.1,0) [0|102] "%" Vector__XXX
   SG_ Jystck6ThtAxsClckwsPstvPsStatus : 36|2@1+ (1,0) [0|3] "" Vector__XXX
   SG_ Jystck6ThtAxsCntrClckwsNgtvPsStt : 34|2@1+ (1,0) [0|3] "" Vector__XXX
   SG_ Jystck6ThtaAxisNeutralPosStatus : 32|2@1+ (1,0) [0|3] "" Vector__XXX
   SG_ Joystick6GripYAxisPos : 22|10@1+ (0.1,0) [0|102] "%" Vector__XXX
   SG_ Jystck6GrpYAxsLvrFrwrdPstvPsStts : 20|2@1+ (1,0) [0|3] "" Vector__XXX
   SG_ Jystck6GrpYAxsLvrBckNgtvPsSttus : 18|2@1+ (1,0) [0|3] "" Vector__XXX
   SG_ Jystck6GrpYAxisNeutralPosStatus : 16|2@1+ (1,0) [0|3] "" Vector__XXX
   SG_ Joystick6GripXAxisPos : 6|10@1+ (0.1,0) [0|102] "%" Vector__XXX
   SG_ Jystck6GrpXAxsLvrRghtPstvPsStts : 4|2@1+ (1,0) [0|3] "" Vector__XXX
   SG_ Jystck6GrpXAxsLvrLftNgtvPsSttus : 2|2@1+ (1,0) [0|3] "" Vector__XXX
   SG_ Jystck6GrpXAxisNeutralPosStatus : 0|2@1+ (1,0) [0|3] "" Vector__XXX

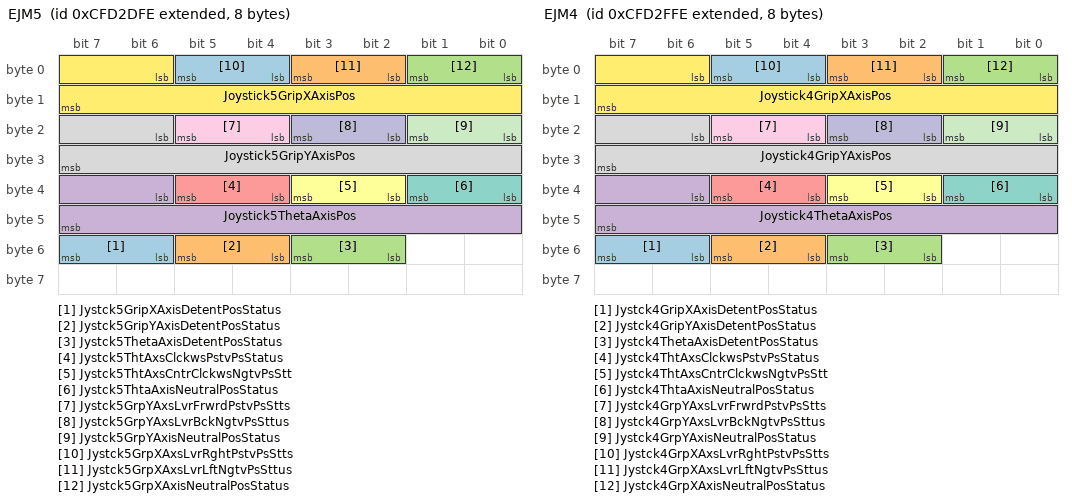
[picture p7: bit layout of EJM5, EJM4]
BO_ 2365402622 EJM5: 8 Vector__XXX
   SG_ Jystck5GripXAxisDetentPosStatus : 54|2@1+ (1,0) [0|3] "" Vector__XXX
   SG_ Jystck5GripYAxisDetentPosStatus : 52|2@1+ (1,0) [0|3] "" Vector__XXX
   SG_ Jystck5ThetaAxisDetentPosStatus : 50|2@1+ (1,0) [0|3] "" Vector__XXX
   SG_ Joystick5ThetaAxisPos : 38|10@1+ (0.1,0) [0|102] "%" Vector__XXX
   SG_ Jystck5ThtAxsClckwsPstvPsStatus : 36|2@1+ (1,0) [0|3] "" Vector__XXX
   SG_ Jystck5ThtAxsCntrClckwsNgtvPsStt : 34|2@1+ (1,0) [0|3] "" Vector__XXX
   SG_ Jystck5ThtaAxisNeutralPosStatus : 32|2@1+ (1,0) [0|3] "" Vector__XXX
   SG_ Joystick5GripYAxisPos : 22|10@1+ (0.1,0) [0|102] "%" Vector__XXX
   SG_ Jystck5GrpYAxsLvrFrwrdPstvPsStts : 20|2@1+ (1,0) [0|3] "" Vector__XXX
   SG_ Jystck5GrpYAxsLvrBckNgtvPsSttus : 18|2@1+ (1,0) [0|3] "" Vector__XXX
   SG_ Jystck5GrpYAxisNeutralPosStatus : 16|2@1+ (1,0) [0|3] "" Vector__XXX
   SG_ Joystick5GripXAxisPos : 6|10@1+ (0.1,0) [0|102] "%" Vector__XXX
   SG_ Jystck5GrpXAxsLvrRghtPstvPsStts : 4|2@1+ (1,0) [0|3] "" Vector__XXX
   SG_ Jystck5GrpXAxsLvrLftNgtvPsSttus : 2|2@1+ (1,0) [0|3] "" Vector__XXX
   SG_ Jystck5GrpXAxisNeutralPosStatus : 0|2@1+ (1,0) [0|3] "" Vector__XXX

BO_ 2365403134 EJM4: 8 Vector__XXX
   SG_ Jystck4GripXAxisDetentPosStatus : 54|2@1+ (1,0) [0|3] "" Vector__XXX
   SG_ Jystck4GripYAxisDetentPosStatus : 52|2@1+ (1,0) [0|3] "" Vector__XXX
   SG_ Jystck4ThetaAxisDetentPosStatus : 50|2@1+ (1,0) [0|3] "" Vector__XXX
   SG_ Joystick4ThetaAxisPos : 38|10@1+ (0.1,0) [0|102] "%" Vector__XXX
   SG_ Jystck4ThtAxsClckwsPstvPsStatus : 36|2@1+ (1,0) [0|3] "" Vector__XXX
   SG_ Jystck4ThtAxsCntrClckwsNgtvPsStt : 34|2@1+ (1,0) [0|3] "" Vector__XXX
   SG_ Jystck4ThtaAxisNeutralPosStatus : 32|2@1+ (1,0) [0|3] "" Vector__XXX
   SG_ Joystick4GripYAxisPos : 22|10@1+ (0.1,0) [0|102] "%" Vector__XXX
   SG_ Jystck4GrpYAxsLvrFrwrdPstvPsStts : 20|2@1+ (1,0) [0|3] "" Vector__XXX
   SG_ Jystck4GrpYAxsLvrBckNgtvPsSttus : 18|2@1+ (1,0) [0|3] "" Vector__XXX
   SG_ Jystck4GrpYAxisNeutralPosStatus : 16|2@1+ (1,0) [0|3] "" Vector__XXX
   SG_ Joystick4GripXAxisPos : 6|10@1+ (0.1,0) [0|102] "%" Vector__XXX
   SG_ Jystck4GrpXAxsLvrRghtPstvPsStts : 4|2@1+ (1,0) [0|3] "" Vector__XXX
   SG_ Jystck4GrpXAxsLvrLftNgtvPsSttus : 2|2@1+ (1,0) [0|3] "" Vector__XXX
   SG_ Jystck4GrpXAxisNeutralPosStatus : 0|2@1+ (1,0) [0|3] "" Vector__XXX

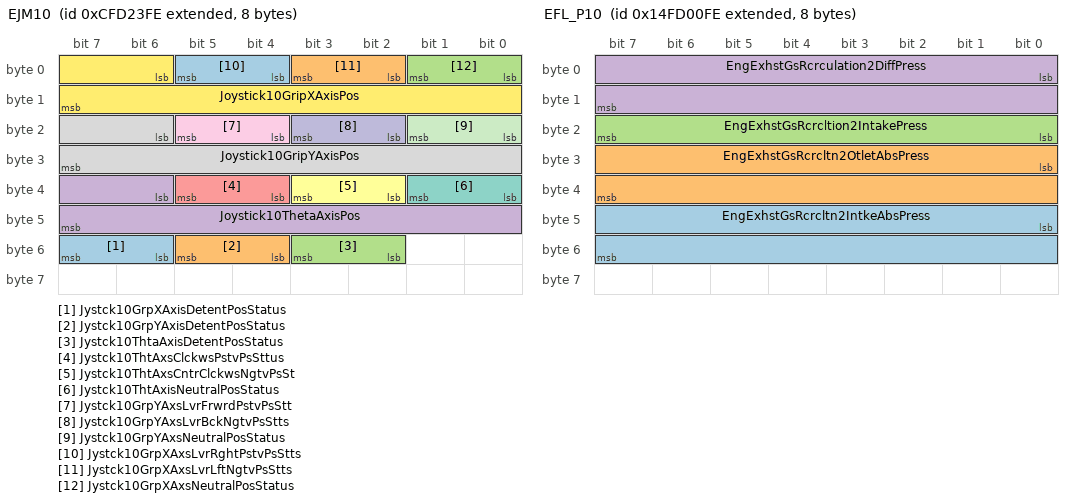
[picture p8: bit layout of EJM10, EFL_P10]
BO_ 2365400062 EJM10: 8 Vector__XXX
   SG_ Jystck10GrpXAxisDetentPosStatus : 54|2@1+ (1,0) [0|3] "" Vector__XXX
   SG_ Jystck10GrpYAxisDetentPosStatus : 52|2@1+ (1,0) [0|3] "" Vector__XXX
   SG_ Jystck10ThtaAxisDetentPosStatus : 50|2@1+ (1,0) [0|3] "" Vector__XXX
   SG_ Joystick10ThetaAxisPos : 38|10@1+ (0.1,0) [0|102] "%" Vector__XXX
   SG_ Jystck10ThtAxsClckwsPstvPsSttus : 36|2@1+ (1,0) [0|3] "" Vector__XXX
   SG_ Jystck10ThtAxsCntrClckwsNgtvPsSt : 34|2@1+ (1,0) [0|3] "" Vector__XXX
   SG_ Jystck10ThtAxisNeutralPosStatus : 32|2@1+ (1,0) [0|3] "" Vector__XXX
   SG_ Joystick10GripYAxisPos : 22|10@1+ (0.1,0) [0|102] "%" Vector__XXX
   SG_ Jystck10GrpYAxsLvrFrwrdPstvPsStt : 20|2@1+ (1,0) [0|3] "" Vector__XXX
   SG_ Jystck10GrpYAxsLvrBckNgtvPsStts : 18|2@1+ (1,0) [0|3] "" Vector__XXX
   SG_ Jystck10GrpYAxsNeutralPosStatus : 16|2@1+ (1,0) [0|3] "" Vector__XXX
   SG_ Joystick10GripXAxisPos : 6|10@1+ (0.1,0) [0|102] "%" Vector__XXX
   SG_ Jystck10GrpXAxsLvrRghtPstvPsStts : 4|2@1+ (1,0) [0|3] "" Vector__XXX
   SG_ Jystck10GrpXAxsLvrLftNgtvPsStts : 2|2@1+ (1,0) [0|3] "" Vector__XXX
   SG_ Jystck10GrpXAxsNeutralPosStatus : 0|2@1+ (1,0) [0|3] "" Vector__XXX

BO_ 2566713598 EFS2: 8 Vector__XXX
   SG_ EngFuelFilterIntakeAbsPress : 0|8@1+ (2,0) [0|500] "kPa" Vector__XXX

BO_ 2499604478 EFL_P11: 8 Vector__XXX
   SG_ EngExhstGsRcrcltn1IntkeAbsPress : 0|16@1+ (0.1,0) [0|6425.5] "kPa" Vector__XXX

BO_ 2499608830 EFL_P10: 8 Vector__XXX
   SG_ EngExhstGsRcrcltn2IntkeAbsPress : 40|16@1+ (0.1,0) [0|6425.5] "kPa" Vector__XXX
   SG_ EngExhstGsRcrcltn2OtletAbsPress : 24|16@1+ (0.1,0) [0|6425.5] "kPa" Vector__XXX
   SG_ EngExhstGsRcrcltion2IntakePress : 16|8@1+ (2,0) [0|500] "kPa" Vector__XXX
   SG_ EngExhstGsRcrculation2DiffPress : 0|16@1+ (0.0078125,-250) [-250|251.99] "kPa" Vector__XXX

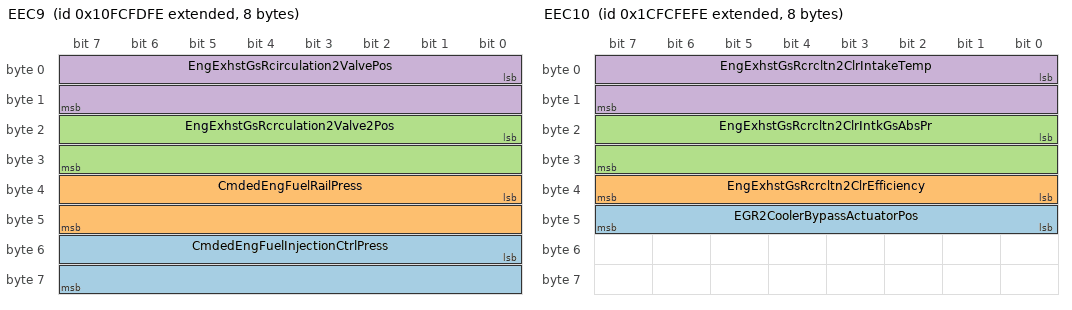
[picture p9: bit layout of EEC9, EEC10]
BO_ 2432499198 EEC9: 8 Vector__XXX
   SG_ CmdedEngFuelInjectionCtrlPress : 48|16@1+ (0.00390625,0) [0|251] "MPa" Vector__XXX
   SG_ CmdedEngFuelRailPress : 32|16@1+ (0.00390625,0) [0|251] "MPa" Vector__XXX
   SG_ EngExhstGsRcrculation2Valve2Pos : 16|16@1+ (0.0025,0) [0|160.637] "%" Vector__XXX
   SG_ EngExhstGsRcirculation2ValvePos : 0|16@1+ (0.0025,0) [0|160.637] "%" Vector__XXX

BO_ 2633825022 EEC11: 8 Vector__XXX
   SG_ EngExhstGsRcrclation2Valve2Ctrl : 16|16@1+ (0.0025,0) [0|160.637] "%" Vector__XXX
   SG_ EngExhstGsRcrculation2ValveCtrl : 0|16@1+ (0.0025,0) [0|160.637] "%" Vector__XXX

BO_ 2633826046 EEC10: 8 Vector__XXX
   SG_ EGR2CoolerBypassActuatorPos : 40|8@1+ (0.4,0) [0|100] "%" Vector__XXX
   SG_ EngExhstGsRcrcltn2ClrEfficiency : 32|8@1+ (0.4,0) [0|100] "%" Vector__XXX
   SG_ EngExhstGsRcrcltn2ClrIntkGsAbsPr : 16|16@1+ (0.5,0) [0|32127.5] "kPa" Vector__XXX
   SG_ EngExhstGsRcrcltn2ClrIntakeTemp : 0|16@1+ (0.03125,-273) [-273|1734.97] "deg C" Vector__XXX

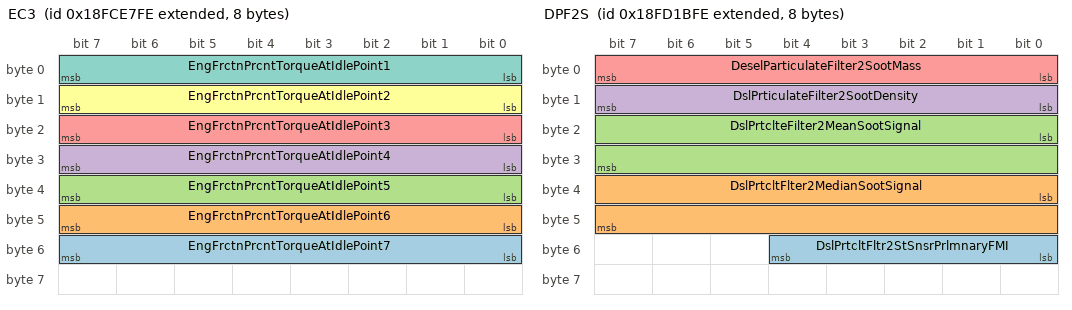
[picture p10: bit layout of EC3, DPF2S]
BO_ 2566711294 EC3: 8 Vector__XXX
   SG_ EngFrctnPrcntTorqueAtIdlePoint7 : 48|8@1+ (1,-125) [-125|125] "%" Vector__XXX
   SG_ EngFrctnPrcntTorqueAtIdlePoint6 : 40|8@1+ (1,-125) [-125|125] "%" Vector__XXX
   SG_ EngFrctnPrcntTorqueAtIdlePoint5 : 32|8@1+ (1,-125) [-125|125] "%" Vector__XXX
   SG_ EngFrctnPrcntTorqueAtIdlePoint4 : 24|8@1+ (1,-125) [-125|125] "%" Vector__XXX
   SG_ EngFrctnPrcntTorqueAtIdlePoint3 : 16|8@1+ (1,-125) [-125|125] "%" Vector__XXX
   SG_ EngFrctnPrcntTorqueAtIdlePoint2 : 8|8@1+ (1,-125) [-125|125] "%" Vector__XXX
   SG_ EngFrctnPrcntTorqueAtIdlePoint1 : 0|8@1+ (1,-125) [-125|125] "%" Vector__XXX

BO_ 2566749438 DPFC1: 8 Vector__XXX
   SG_ DslPrtcltFltrActvRgnrtnFrcdStts : 53|3@1+ (1,0) [0|7] "" Vector__XXX
   SG_ ExhaustSystemHighTempLampCmd : 50|3@1+ (1,0) [0|7] "" Vector__XXX
   SG_ DslPrtcltFltrAtmtcActvRgnrtnIntt : 48|2@1+ (1,0) [0|3] "" Vector__XXX
   SG_ DslPrtcltFltrActvRgnrtnInhbtdDTV : 46|2@1+ (1,0) [0|3] "" Vector__XXX
   SG_ DslPrtcltFltrActvRgnrtnInhbtdDTE : 44|2@1+ (1,0) [0|3] "" Vector__XXX
   SG_ DslPrtcltFltrActvRgnrtnInhbtdDTP : 42|2@1+ (1,0) [0|3] "" Vector__XXX
   SG_ DslPrtcltFltrActvRgnrtnInhbtdDTT : 40|2@1+ (1,0) [0|3] "" Vector__XXX
   SG_ DslPrtcltFltrActvRgnrtnInhbtdDTS : 38|2@1+ (1,0) [0|3] "" Vector__XXX
   SG_ DslPrtcltFltrActvRgnrtnInhb_0000 : 36|2@1+ (1,0) [0|3] "" Vector__XXX
   SG_ DslPrtcltFltrActvRgnrtnInhbtdDTL : 34|2@1+ (1,0) [0|3] "" Vector__XXX
   SG_ DslPrtcltFltrActvRgnrtnInhb_0001 : 32|2@1+ (1,0) [0|3] "" Vector__XXX
   SG_ DslPrtcltFltrActvRgnrtnInhb_0002 : 30|2@1+ (1,0) [0|3] "" Vector__XXX
   SG_ DslPrtcltFltrActvRgnrtnInhbtdDTO : 28|2@1+ (1,0) [0|3] "" Vector__XXX
   SG_ DslPrtcltFltrActvRgnrtnInhbtdDTA : 26|2@1+ (1,0) [0|3] "" Vector__XXX
   SG_ DslPrtcltFltrActvRgnrtnInhb_0003 : 24|2@1+ (1,0) [0|3] "" Vector__XXX
   SG_ DslPrtcltFltrActvRgnrtnInhb_0004 : 22|2@1+ (1,0) [0|3] "" Vector__XXX
   SG_ DslPrtcltFltrActvRgnrtnInhbtdDTC : 20|2@1+ (1,0) [0|3] "" Vector__XXX
   SG_ DslPrtcltFltrActvRgnrtnInhbtdDTI : 18|2@1+ (1,0) [0|3] "" Vector__XXX
   SG_ DslPrtcltFltrActvRgnrtnInhbtdStt : 16|2@1+ (1,0) [0|3] "" Vector__XXX
   SG_ DieselParticulateFilterStatus : 12|3@1+ (1,0) [0|7] "" Vector__XXX
   SG_ DslPrtcltFltrActvRgnrtionStatus : 10|2@1+ (1,0) [0|3] "" Vector__XXX
   SG_ DslPrtcltFltrPssvRgnrtionStatus : 8|2@1+ (1,0) [0|3] "" Vector__XXX
   SG_ DieselParticulateFilterLampCmd : 0|3@1+ (1,0) [0|7] "" Vector__XXX

BO_ 2566715646 DPF2S2: 8 Vector__XXX
   SG_ DslPrtclateFilter2SootSignalMin : 32|16@1+ (0.0025,0) [0|160.637] "%" Vector__XXX
   SG_ DslPrtclateFilter2SootSignalMax : 16|16@1+ (0.0025,0) [0|160.637] "%" Vector__XXX
   SG_ DslPrtcltFltr2StSgnlStndrdDvton : 0|16@1+ (0.0025,0) [0|160.637] "%" Vector__XXX

BO_ 2566724606 DPF2S: 8 Vector__XXX
   SG_ DslPrtcltFltr2StSnsrPrlmnaryFMI : 48|5@1+ (1,0) [0|31] "" Vector__XXX
   SG_ DslPrtcltFlter2MedianSootSignal : 32|16@1+ (0.0025,0) [0|160.637] "%" Vector__XXX
   SG_ DslPrtclteFilter2MeanSootSignal : 16|16@1+ (0.0025,0) [0|160.637] "%" Vector__XXX
   SG_ DslPrticulateFilter2SootDensity : 8|8@1+ (0.08,0) [0|20] "g/L" Vector__XXX
   SG_ DeselParticulateFilter2SootMass : 0|8@1+ (4,0) [0|1000] "g" Vector__XXX

BO_ 2566715902 DPF1S2: 8 Vector__XXX
   SG_ DslPrtclateFilter1SootSignalMin : 32|16@1+ (0.0025,0) [0|160.637] "%" Vector__XXX
   SG_ DslPrtclateFilter1SootSignalMax : 16|16@1+ (0.0025,0) [0|160.637] "%" Vector__XXX
   SG_ DslPrtcltFltr1StSgnlStndrdDvton : 0|16@1+ (0.0025,0) [0|160.637] "%" Vector__XXX

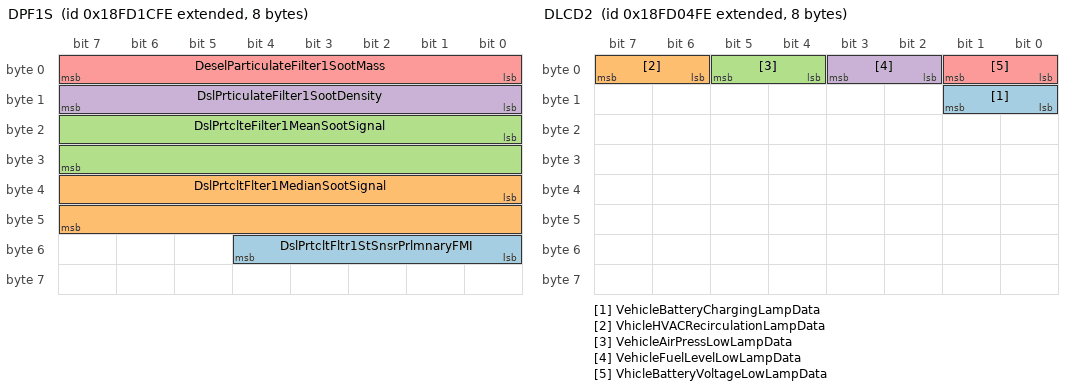
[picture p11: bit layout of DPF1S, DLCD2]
BO_ 2566724862 DPF1S: 8 Vector__XXX
   SG_ DslPrtcltFltr1StSnsrPrlmnaryFMI : 48|5@1+ (1,0) [0|31] "" Vector__XXX
   SG_ DslPrtcltFlter1MedianSootSignal : 32|16@1+ (0.0025,0) [0|160.637] "%" Vector__XXX
   SG_ DslPrtclteFilter1MeanSootSignal : 16|16@1+ (0.0025,0) [0|160.637] "%" Vector__XXX
   SG_ DslPrticulateFilter1SootDensity : 8|8@1+ (0.08,0) [0|20] "g/L" Vector__XXX
   SG_ DeselParticulateFilter1SootMass : 0|8@1+ (4,0) [0|1000] "g" Vector__XXX

BO_ 2566718718 DLCD2: 8 Vector__XXX
   SG_ VehicleBatteryChargingLampData : 8|2@1+ (1,0) [0|3] "" Vector__XXX
   SG_ VhicleHVACRecirculationLampData : 6|2@1+ (1,0) [0|3] "" Vector__XXX
   SG_ VehicleAirPressLowLampData : 4|2@1+ (1,0) [0|3] "" Vector__XXX
   SG_ VehicleFuelLevelLowLampData : 2|2@1+ (1,0) [0|3] "" Vector__XXX
   SG_ VhicleBatteryVoltageLowLampData : 0|2@1+ (1,0) [0|3] "" Vector__XXX

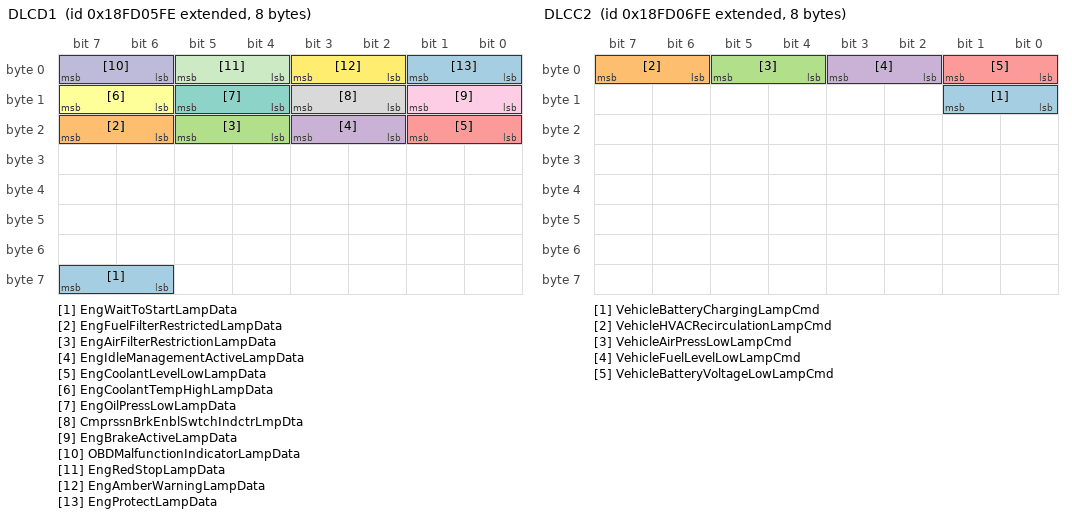
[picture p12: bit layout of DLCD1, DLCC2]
BO_ 2566718974 DLCD1: 8 Vector__XXX
   SG_ EngWaitToStartLampData : 62|2@1+ (1,0) [0|3] "" Vector__XXX
   SG_ EngFuelFilterRestrictedLampData : 22|2@1+ (1,0) [0|3] "" Vector__XXX
   SG_ EngAirFilterRestrictionLampData : 20|2@1+ (1,0) [0|3] "" Vector__XXX
   SG_ EngIdleManagementActiveLampData : 18|2@1+ (1,0) [0|3] "" Vector__XXX
   SG_ EngCoolantLevelLowLampData : 16|2@1+ (1,0) [0|3] "" Vector__XXX
   SG_ EngCoolantTempHighLampData : 14|2@1+ (1,0) [0|3] "" Vector__XXX
   SG_ EngOilPressLowLampData : 12|2@1+ (1,0) [0|3] "" Vector__XXX
   SG_ CmprssnBrkEnblSwtchIndctrLmpDta : 10|2@1+ (1,0) [0|3] "" Vector__XXX
   SG_ EngBrakeActiveLampData : 8|2@1+ (1,0) [0|3] "" Vector__XXX
   SG_ OBDMalfunctionIndicatorLampData : 6|2@1+ (1,0) [0|3] "" Vector__XXX
   SG_ EngRedStopLampData : 4|2@1+ (1,0) [0|3] "" Vector__XXX
   SG_ EngAmberWarningLampData : 2|2@1+ (1,0) [0|3] "" Vector__XXX
   SG_ EngProtectLampData : 0|2@1+ (1,0) [0|3] "" Vector__XXX

BO_ 2566719230 DLCC2: 8 Vector__XXX
   SG_ VehicleBatteryChargingLampCmd : 8|2@1+ (1,0) [0|3] "" Vector__XXX
   SG_ VehicleHVACRecirculationLampCmd : 6|2@1+ (1,0) [0|3] "" Vector__XXX
   SG_ VehicleAirPressLowLampCmd : 4|2@1+ (1,0) [0|3] "" Vector__XXX
   SG_ VehicleFuelLevelLowLampCmd : 2|2@1+ (1,0) [0|3] "" Vector__XXX
   SG_ VehicleBatteryVoltageLowLampCmd : 0|2@1+ (1,0) [0|3] "" Vector__XXX

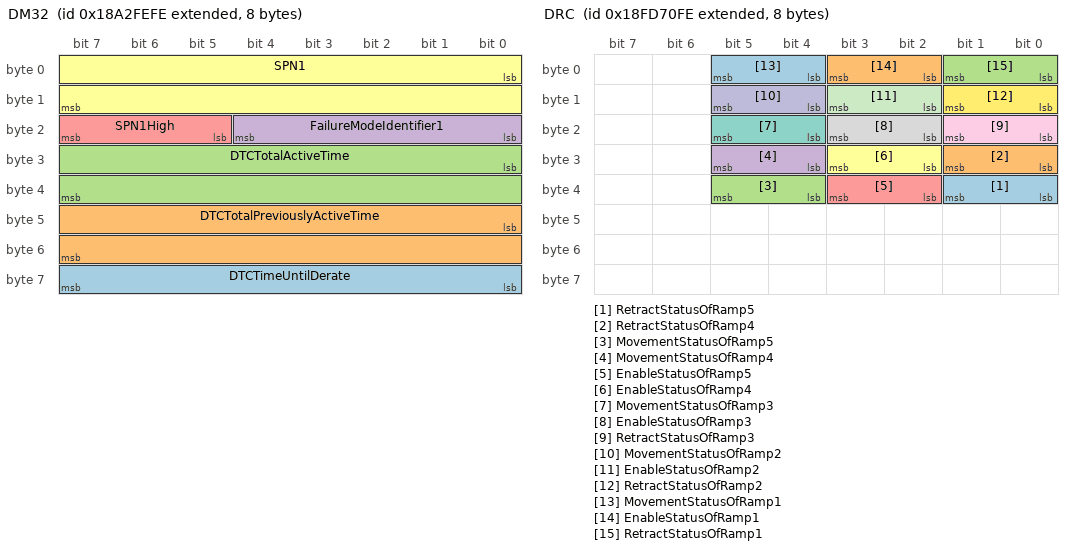
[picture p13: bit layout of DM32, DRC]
BO_ 2560818942 DM32: 8 Vector__XXX
   SG_ DTCTimeUntilDerate : 56|8@1+ (0.25,0) [0|62.5] "hr" Vector__XXX
   SG_ DTCTotalPreviouslyActiveTime : 40|16@1+ (0.2,0) [0|12851] "hr" Vector__XXX
   SG_ DTCTotalActiveTime : 24|16@1+ (0.2,0) [0|12851] "hr" Vector__XXX
   SG_ FailureModeIdentifier1 : 16|5@1+ (1,0) [0|0] "" Vector__XXX
   SG_ SPN1High : 21|3@1+ (1,0) [0|7] "" Vector__XXX
   SG_ SPN1 : 0|16@1+ (1,0) [0|65536] "" Vector__XXX

BO_ 2561212158 DISP1: 8 Vector__XXX
   SG_ TextDisplayIndex : 16|8@1+ (1,0) [0|250] "" Vector__XXX
   SG_ TextDisplayInstructions : 0|4@1+ (1,0) [0|15] "" Vector__XXX

BO_ 2566746366 DRC: 8 Vector__XXX
   SG_ RetractStatusOfRamp5 : 32|2@1+ (1,0) [0|3] "" Vector__XXX
   SG_ RetractStatusOfRamp4 : 24|2@1+ (1,0) [0|3] "" Vector__XXX
   SG_ MovementStatusOfRamp5 : 36|2@1+ (1,0) [0|3] "" Vector__XXX
   SG_ MovementStatusOfRamp4 : 28|2@1+ (1,0) [0|3] "" Vector__XXX
   SG_ EnableStatusOfRamp5 : 34|2@1+ (1,0) [0|3] "" Vector__XXX
   SG_ EnableStatusOfRamp4 : 26|2@1+ (1,0) [0|3] "" Vector__XXX
   SG_ MovementStatusOfRamp3 : 20|2@1+ (1,0) [0|3] "" Vector__XXX
   SG_ EnableStatusOfRamp3 : 18|2@1+ (1,0) [0|3] "" Vector__XXX
   SG_ RetractStatusOfRamp3 : 16|2@1+ (1,0) [0|3] "" Vector__XXX
   SG_ MovementStatusOfRamp2 : 12|2@1+ (1,0) [0|3] "" Vector__XXX
   SG_ EnableStatusOfRamp2 : 10|2@1+ (1,0) [0|3] "" Vector__XXX
   SG_ RetractStatusOfRamp2 : 8|2@1+ (1,0) [0|3] "" Vector__XXX
   SG_ MovementStatusOfRamp1 : 4|2@1+ (1,0) [0|3] "" Vector__XXX
   SG_ EnableStatusOfRamp1 : 2|2@1+ (1,0) [0|3] "" Vector__XXX
   SG_ RetractStatusOfRamp1 : 0|2@1+ (1,0) [0|3] "" Vector__XXX

BO_ 2566750206 EC2: 8 Vector__XXX
   SG_ MaxCrankAttemptsPerStartAttempt : 0|8@1+ (1,0) [0|250] "" Vector__XXX

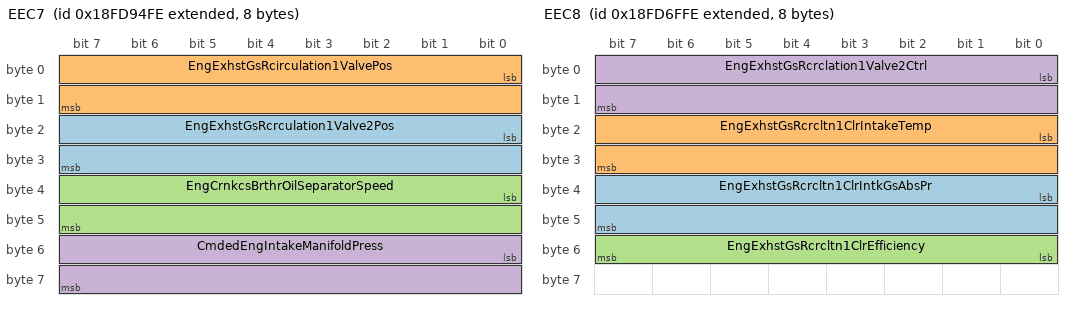
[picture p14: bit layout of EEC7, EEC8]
BO_ 2566755582 EEC7: 8 Vector__XXX
   SG_ EngExhstGsRcrculation1Valve2Pos : 16|16@1+ (0.0025,0) [0|160.637] "%" Vector__XXX
   SG_ EngExhstGsRcirculation1ValvePos : 0|16@1+ (0.0025,0) [0|160.637] "%" Vector__XXX
   SG_ EngCrnkcsBrthrOilSeparatorSpeed : 32|16@1+ (1,0) [0|64255] "rpm" Vector__XXX
   SG_ CmdedEngIntakeManifoldPress : 48|16@1+ (0.125,0) [0|8031.88] "kPa" Vector__XXX

BO_ 2566746110 EEC8: 8 Vector__XXX
   SG_ EngExhstGsRcrcltn1ClrIntkGsAbsPr : 32|16@1+ (0.5,0) [0|32127.5] "kPa" Vector__XXX
   SG_ EngExhstGsRcrcltn1ClrIntakeTemp : 16|16@1+ (0.03125,-273) [-273|1734.97] "deg C" Vector__XXX
   SG_ EngExhstGsRcrcltn1ClrEfficiency : 48|8@1+ (0.4,0) [0|100] "%" Vector__XXX
   SG_ EngExhstGsRcrclation1Valve2Ctrl : 0|16@1+ (0.0025,0) [0|160.637] "%" Vector__XXX

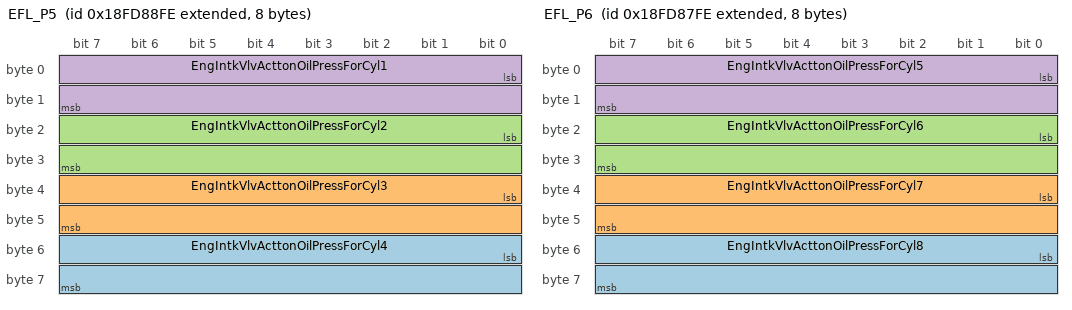
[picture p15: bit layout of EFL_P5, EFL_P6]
BO_ 2566752510 EFL_P5: 8 Vector__XXX
   SG_ EngIntkVlvActtonOilPressForCyl4 : 48|16@1+ (0.1,0) [0|6425.5] "kPa" Vector__XXX
   SG_ EngIntkVlvActtonOilPressForCyl3 : 32|16@1+ (0.1,0) [0|6425.5] "kPa" Vector__XXX
   SG_ EngIntkVlvActtonOilPressForCyl2 : 16|16@1+ (0.1,0) [0|6425.5] "kPa" Vector__XXX
   SG_ EngIntkVlvActtonOilPressForCyl1 : 0|16@1+ (0.1,0) [0|6425.5] "kPa" Vector__XXX

BO_ 2566752254 EFL_P6: 8 Vector__XXX
   SG_ EngIntkVlvActtonOilPressForCyl8 : 48|16@1+ (0.1,0) [0|6425.5] "kPa" Vector__XXX
   SG_ EngIntkVlvActtonOilPressForCyl7 : 32|16@1+ (0.1,0) [0|6425.5] "kPa" Vector__XXX
   SG_ EngIntkVlvActtonOilPressForCyl6 : 16|16@1+ (0.1,0) [0|6425.5] "kPa" Vector__XXX
   SG_ EngIntkVlvActtonOilPressForCyl5 : 0|16@1+ (0.1,0) [0|6425.5] "kPa" Vector__XXX

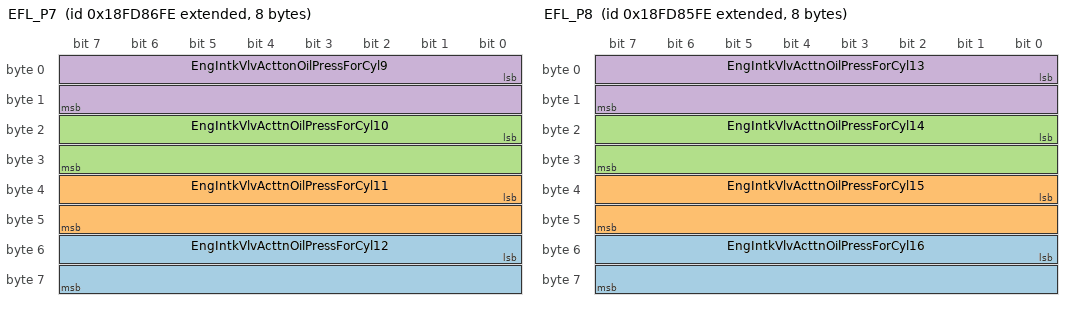
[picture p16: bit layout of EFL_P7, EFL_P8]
BO_ 2566751998 EFL_P7: 8 Vector__XXX
   SG_ EngIntkVlvActtnOilPressForCyl12 : 48|16@1+ (0.1,0) [0|6425.5] "kPa" Vector__XXX
   SG_ EngIntkVlvActtnOilPressForCyl11 : 32|16@1+ (0.1,0) [0|6425.5] "kPa" Vector__XXX
   SG_ EngIntkVlvActtnOilPressForCyl10 : 16|16@1+ (0.1,0) [0|6425.5] "kPa" Vector__XXX
   SG_ EngIntkVlvActtonOilPressForCyl9 : 0|16@1+ (0.1,0) [0|6425.5] "kPa" Vector__XXX

BO_ 2566751742 EFL_P8: 8 Vector__XXX
   SG_ EngIntkVlvActtnOilPressForCyl16 : 48|16@1+ (0.1,0) [0|6425.5] "kPa" Vector__XXX
   SG_ EngIntkVlvActtnOilPressForCyl15 : 32|16@1+ (0.1,0) [0|6425.5] "kPa" Vector__XXX
   SG_ EngIntkVlvActtnOilPressForCyl14 : 16|16@1+ (0.1,0) [0|6425.5] "kPa" Vector__XXX
   SG_ EngIntkVlvActtnOilPressForCyl13 : 0|16@1+ (0.1,0) [0|6425.5] "kPa" Vector__XXX

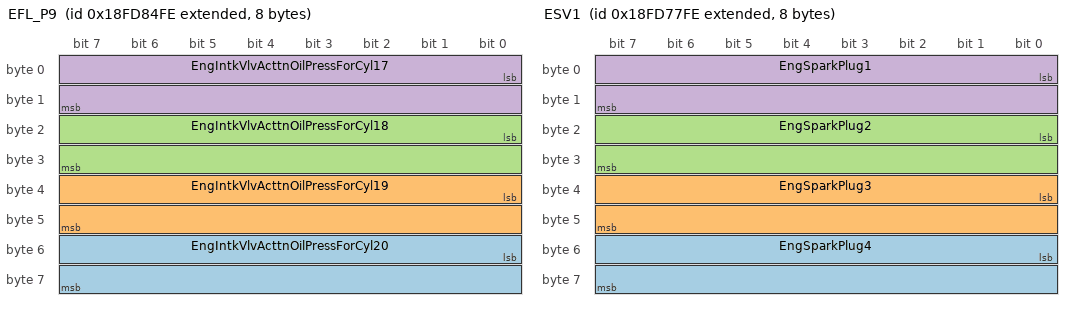
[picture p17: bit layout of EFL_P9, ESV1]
BO_ 2566751486 EFL_P9: 8 Vector__XXX
   SG_ EngIntkVlvActtnOilPressForCyl20 : 48|16@1+ (0.1,0) [0|6425.5] "kPa" Vector__XXX
   SG_ EngIntkVlvActtnOilPressForCyl19 : 32|16@1+ (0.1,0) [0|6425.5] "kPa" Vector__XXX
   SG_ EngIntkVlvActtnOilPressForCyl18 : 16|16@1+ (0.1,0) [0|6425.5] "kPa" Vector__XXX
   SG_ EngIntkVlvActtnOilPressForCyl17 : 0|16@1+ (0.1,0) [0|6425.5] "kPa" Vector__XXX

BO_ 2499641854 EGRBV: 8 Vector__XXX
   SG_ EGR1CoolerBypassActuatorPostion : 0|8@1+ (0.4,0) [0|100] "%" Vector__XXX

BO_ 2566748158 ESV1: 8 Vector__XXX
   SG_ EngSparkPlug4 : 48|16@1+ (1,0) [0|64255] "Volts" Vector__XXX
   SG_ EngSparkPlug3 : 32|16@1+ (1,0) [0|64255] "Volts" Vector__XXX
   SG_ EngSparkPlug2 : 16|16@1+ (1,0) [0|64255] "Volts" Vector__XXX
   SG_ EngSparkPlug1 : 0|16@1+ (1,0) [0|64255] "Volts" Vector__XXX

BO_ 2566747902 ESV2: 8 Vector__XXX
   SG_ EngSparkPlug8 : 48|16@1+ (1,0) [0|64255] "Volts" Vector__XXX
   SG_ EngSparkPlug7 : 32|16@1+ (1,0) [0|64255] "Volts" Vector__XXX
   SG_ EngSparkPlug6 : 16|16@1+ (1,0) [0|64255] "Volts" Vector__XXX
   SG_ EngSparkPlug5 : 0|16@1+ (1,0) [0|64255] "Volts" Vector__XXX

BO_ 2566747646 ESV3: 8 Vector__XXX
   SG_ EngSparkPlug12 : 48|16@1+ (1,0) [0|64255] "Volts" Vector__XXX
   SG_ EngSparkPlug11 : 32|16@1+ (1,0) [0|64255] "Volts" Vector__XXX
   SG_ EngSparkPlug10 : 16|16@1+ (1,0) [0|64255] "Volts" Vector__XXX
   SG_ EngSparkPlug9 : 0|16@1+ (1,0) [0|64255] "Volts" Vector__XXX

BO_ 2566747390 ESV4: 8 Vector__XXX
   SG_ EngSparkPlug16 : 48|16@1+ (1,0) [0|64255] "Volts" Vector__XXX
   SG_ EngSparkPlug15 : 32|16@1+ (1,0) [0|64255] "Volts" Vector__XXX
   SG_ EngSparkPlug14 : 16|16@1+ (1,0) [0|64255] "Volts" Vector__XXX
   SG_ EngSparkPlug13 : 0|16@1+ (1,0) [0|64255] "Volts" Vector__XXX

BO_ 2566747134 ESV5: 8 Vector__XXX
   SG_ EngSparkPlug20 : 48|16@1+ (1,0) [0|64255] "Volts" Vector__XXX
   SG_ EngSparkPlug19 : 32|16@1+ (1,0) [0|64255] "Volts" Vector__XXX
   SG_ EngSparkPlug18 : 16|16@1+ (1,0) [0|64255] "Volts" Vector__XXX
   SG_ EngSparkPlug17 : 0|16@1+ (1,0) [0|64255] "Volts" Vector__XXX

BO_ 2566746878 ESV6: 8 Vector__XXX
   SG_ EngSparkPlug24 : 48|16@1+ (1,0) [0|64255] "Volts" Vector__XXX
   SG_ EngSparkPlug23 : 32|16@1+ (1,0) [0|64255] "Volts" Vector__XXX
   SG_ EngSparkPlug22 : 16|16@1+ (1,0) [0|64255] "Volts" Vector__XXX
   SG_ EngSparkPlug21 : 0|16@1+ (1,0) [0|64255] "Volts" Vector__XXX

BO_ 2561277694 FLIC: 8 Vector__XXX
   SG_ LaneDepartureWarningEnableCmd : 0|2@1+ (1,0) [0|3] "" Vector__XXX

BO_ 2633861886 J2012: 8 Vector__XXX
   SG_ J2012DTCOccurrenceCount : 49|7@1+ (1,0) [0|127] "" Vector__XXX
   SG_ J2012DTCStatus : 48|1@1+ (1,0) [0|1] "" Vector__XXX
   SG_ NumberOfJ2012DTCs : 0|8@1+ (1,0) [0|250] "" Vector__XXX

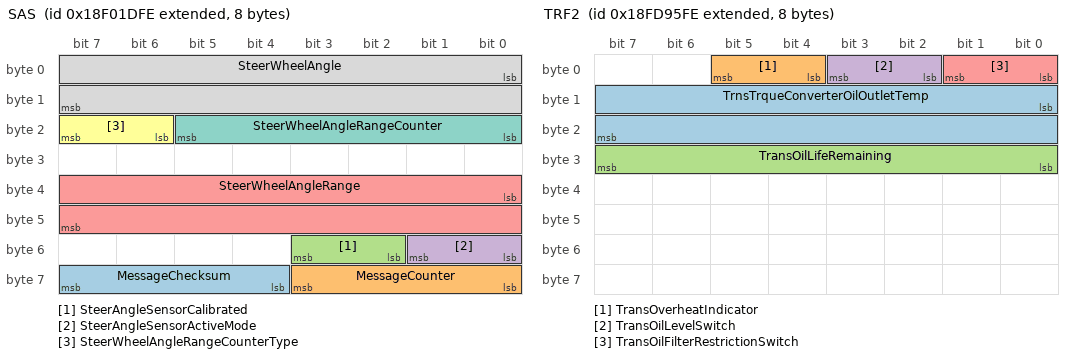
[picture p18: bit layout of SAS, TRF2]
BO_ 2565873150 SAS: 8 Vector__XXX
   SG_ MessageChecksum : 60|4@1+ (1,0) [0|15] "" Vector__XXX
   SG_ MessageCounter : 56|4@1+ (1,0) [0|15] "" Vector__XXX
   SG_ SteerAngleSensorCalibrated : 50|2@1+ (1,0) [0|3] "" Vector__XXX
   SG_ SteerAngleSensorActiveMode : 48|2@1+ (1,0) [0|3] "" Vector__XXX
   SG_ SteerWheelAngleRange : 32|16@1+ (0.000976563,-31.374) [-31.374|31.374] "rad" Vector__XXX
   SG_ SteerWheelAngleRangeCounterType : 22|2@1+ (1,0) [0|3] "" Vector__XXX
   SG_ SteerWheelAngleRangeCounter : 16|6@1+ (1,-32) [-32|29] "ranges" Vector__XXX
   SG_ SteerWheelAngle : 0|16@1+ (0.000976563,-31.374) [-31.374|31.374] "rad" Vector__XXX

BO_ 2566745854 SCR1: 8 Vector__XXX
   SG_ Aftrtrtmnt1SCRCtlystCnvrsnEffcnc : 32|8@1+ (0.4,0) [0|100] "%" Vector__XXX
   SG_ Aftrtrtmnt1SCRCmddCtlystRgntCnsm : 16|16@1+ (0.05,0) [0|3212.75] "L/h" Vector__XXX
   SG_ Aftrtrtmnt1SCRAvrgCtlystRgntCnsm : 0|16@1+ (0.05,0) [0|3212.75] "L/h" Vector__XXX
   SG_ Aftrtrtmnt1DslExhstFldTnkLwLvlIn : 40|16@1+ (1,0) [0|64255] "km" Vector__XXX

BO_ 2566751230 TCI: 8 Vector__XXX
   SG_ TransferCaseStatus : 0|3@1+ (1,0) [0|7] "" Vector__XXX

BO_ 2566755838 TRF2: 8 Vector__XXX
   SG_ TrnsTrqueConverterOilOutletTemp : 8|16@1+ (0.03125,-273) [-273|1734.97] "deg C" Vector__XXX
   SG_ TransOverheatIndicator : 4|2@1+ (1,0) [0|3] "" Vector__XXX
   SG_ TransOilLifeRemaining : 24|8@1+ (0.4,0) [0|100] "%" Vector__XXX
   SG_ TransOilLevelSwitch : 2|2@1+ (1,0) [0|3] "" Vector__XXX
   SG_ TransOilFilterRestrictionSwitch : 0|2@1+ (1,0) [0|3] "" Vector__XXX

BO_ 2566752766 VDS2: 8 Vector__XXX
   SG_ VehicleRoll : 0|16@1+ (0.0078125,-200) [-200|301.99] "deg" Vector__XXX

BO_ 2633938942 LF: 10 Vector__XXX
   SG_ TotalEngCruiseTime : 48|32@1+ (0.05,0) [0|2.10554e+08] "hr" Vector__XXX
   SG_ TotalDriveAverageLoadFactor : 40|8@1+ (0.4,0) [0|100] "%" Vector__XXX
   SG_ TripDriveAverageLoadFactor : 32|8@1+ (0.4,0) [0|100] "%" Vector__XXX
   SG_ TripAverageEngSpeed : 16|16@1+ (0.125,0) [0|8031.88] "rpm" Vector__XXX
   SG_ TripMaxEngSpeed : 0|16@1+ (0.125,0) [0|8031.88] "rpm" Vector__XXX

BO_ 2566799614 LD: 8 Vector__XXX
   SG_ ImplementRearWorkLight : 62|2@1+ (1,0) [0|3] "" Vector__XXX
   SG_ ImplementLeftForwardWorkLight : 60|2@1+ (1,0) [0|3] "" Vector__XXX
   SG_ ImplementRightForwardWorkLight : 58|2@1+ (1,0) [0|3] "" Vector__XXX
   SG_ ImplementLeftFacingWorkLight : 54|2@1+ (1,0) [0|3] "" Vector__XXX
   SG_ ImplementRightFacingWorkLight : 52|2@1+ (1,0) [0|3] "" Vector__XXX
   SG_ ImplementOEMOption1Light : 50|2@1+ (1,0) [0|3] "" Vector__XXX
   SG_ ImplementOEMOption2Light : 48|2@1+ (1,0) [0|3] "" Vector__XXX
   SG_ TrctrFrontHighMountedWorkLights : 46|2@1+ (1,0) [0|3] "" Vector__XXX
   SG_ TrctorFrontLowMountedWorkLights : 44|2@1+ (1,0) [0|3] "" Vector__XXX
   SG_ TrctorSideHighMountedWorkLights : 42|2@1+ (1,0) [0|3] "" Vector__XXX
   SG_ TractorSideLowMountedWorkLights : 40|2@1+ (1,0) [0|3] "" Vector__XXX
   SG_ TrctorRearHighMountedWorkLights : 38|2@1+ (1,0) [0|3] "" Vector__XXX
   SG_ TractorRearLowMountedWorkLights : 36|2@1+ (1,0) [0|3] "" Vector__XXX
   SG_ TrctrUndersideMountedWorkLights : 34|2@1+ (1,0) [0|3] "" Vector__XXX
   SG_ RearFogLights : 32|2@1+ (1,0) [0|3] "" Vector__XXX
   SG_ TractorMarkerLight : 30|2@1+ (1,0) [0|3] "" Vector__XXX
   SG_ ImplementMarkerLight : 28|2@1+ (1,0) [0|3] "" Vector__XXX
   SG_ TractorClearanceLight : 26|2@1+ (1,0) [0|3] "" Vector__XXX
   SG_ ImplementClearanceLight : 24|2@1+ (1,0) [0|3] "" Vector__XXX
   SG_ LeftStopLight : 22|2@1+ (1,0) [0|3] "" Vector__XXX
   SG_ RightStopLight : 20|2@1+ (1,0) [0|3] "" Vector__XXX
   SG_ CenterStopLight : 18|2@1+ (1,0) [0|3] "" Vector__XXX
   SG_ BackUpLightAndAlarmHorn : 16|2@1+ (1,0) [0|3] "" Vector__XXX
   SG_ LeftTurnSignalLights : 14|2@1+ (1,0) [0|3] "" Vector__XXX
   SG_ RightTurnSignalLights : 12|2@1+ (1,0) [0|3] "" Vector__XXX
   SG_ RotatingBeaconLight : 10|2@1+ (1,0) [0|3] "" Vector__XXX
   SG_ TractorFrontFogLights : 8|2@1+ (1,0) [0|3] "" Vector__XXX
   SG_ HighBeamHeadLightData : 6|2@1+ (1,0) [0|3] "" Vector__XXX
   SG_ LowBeamHeadLightData : 4|2@1+ (1,0) [0|3] "" Vector__XXX
   SG_ AltBeamHeadLightData : 2|2@1+ (1,0) [0|3] "" Vector__XXX
   SG_ RunningLight : 0|2@1+ (1,0) [0|3] "" Vector__XXX

BO_ 2365473278 LC: 8 Vector__XXX
   SG_ ImplementRearWorkLightCmd : 62|2@1+ (1,0) [0|3] "" Vector__XXX
   SG_ ImplmentLeftForwardWorkLightCmd : 60|2@1+ (1,0) [0|3] "" Vector__XXX
   SG_ ImplmntRightForwardWorkLightCmd : 58|2@1+ (1,0) [0|3] "" Vector__XXX
   SG_ LightingDataRqCmd : 56|2@1+ (1,0) [0|3] "" Vector__XXX
   SG_ ImplementLeftFacingWorkLightCmd : 54|2@1+ (1,0) [0|3] "" Vector__XXX
   SG_ ImplmentRightFacingWorkLightCmd : 52|2@1+ (1,0) [0|3] "" Vector__XXX
   SG_ ImplementOEMOption1LightCmd : 50|2@1+ (1,0) [0|3] "" Vector__XXX
   SG_ ImplementOEMOption2LightCmd : 48|2@1+ (1,0) [0|3] "" Vector__XXX
   SG_ TrctrFrntHghMuntedWorkLightsCmd : 46|2@1+ (1,0) [0|3] "" Vector__XXX
   SG_ TrctrFrntLwMountedWorkLightsCmd : 44|2@1+ (1,0) [0|3] "" Vector__XXX
   SG_ TrctrSdHighMountedWorkLightsCmd : 42|2@1+ (1,0) [0|3] "" Vector__XXX
   SG_ TrctrSdeLowMountedWorkLightsCmd : 40|2@1+ (1,0) [0|3] "" Vector__XXX
   SG_ TrctrRrHighMountedWorkLightsCmd : 38|2@1+ (1,0) [0|3] "" Vector__XXX
   SG_ TrctrRarLowMountedWorkLightsCmd : 36|2@1+ (1,0) [0|3] "" Vector__XXX
   SG_ TrctrUndrsdMountedWorkLightsCmd : 34|2@1+ (1,0) [0|3] "" Vector__XXX
   SG_ RearFogLightCmd : 32|2@1+ (1,0) [0|3] "" Vector__XXX
   SG_ TractorMarkerLightCmd : 30|2@1+ (1,0) [0|3] "" Vector__XXX
   SG_ ImplementMarkerLightCmd : 28|2@1+ (1,0) [0|3] "" Vector__XXX
   SG_ TractorClearanceLightCmd : 26|2@1+ (1,0) [0|3] "" Vector__XXX
   SG_ ImplementClearanceLightCmd : 24|2@1+ (1,0) [0|3] "" Vector__XXX
   SG_ LeftStopLightCmd : 22|2@1+ (1,0) [0|3] "" Vector__XXX
   SG_ RightStopLightCmd : 20|2@1+ (1,0) [0|3] "" Vector__XXX
   SG_ CenterStopLightCmd : 18|2@1+ (1,0) [0|3] "" Vector__XXX
   SG_ BackUpLightAndAlarmHornCmd : 16|2@1+ (1,0) [0|3] "" Vector__XXX
   SG_ LeftTurnSignalLightsCmd : 14|2@1+ (1,0) [0|3] "" Vector__XXX
   SG_ RightTurnSignalLightsCmd : 12|2@1+ (1,0) [0|3] "" Vector__XXX
   SG_ RotatingBeaconLightCmd : 10|2@1+ (1,0) [0|3] "" Vector__XXX
   SG_ TractorFrontFogLightsCmd : 8|2@1+ (1,0) [0|3] "" Vector__XXX
   SG_ HighBeamHeadLightCmd : 6|2@1+ (1,0) [0|3] "" Vector__XXX
   SG_ LowBeamHeadLightCmd : 4|2@1+ (1,0) [0|3] "" Vector__XXX
   SG_ AltBeamHeadLightCmd : 2|2@1+ (1,0) [0|3] "" Vector__XXX
   SG_ RunningLightCmd : 0|2@1+ (1,0) [0|3] "" Vector__XXX

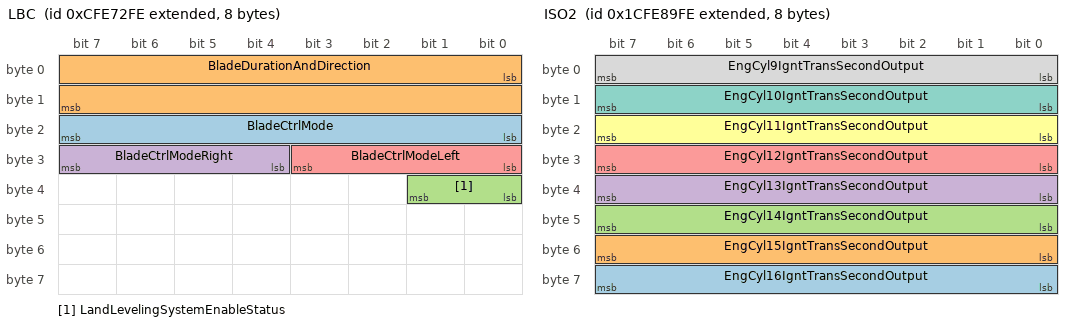
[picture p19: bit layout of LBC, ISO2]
BO_ 2365485822 LBC: 8 Vector__XXX
   SG_ BladeCtrlMode : 16|8@1+ (1,0) [0|255] "" Vector__XXX
   SG_ BladeDurationAndDirection : 0|16@1+ (0.1,-3276.8) [-3276.8|3148.7] "sec" Vector__XXX
   SG_ LandLevelingSystemEnableStatus : 32|2@1+ (1,0) [0|3] "" Vector__XXX
   SG_ BladeCtrlModeRight : 28|4@1+ (1,0) [0|15] "" Vector__XXX
   SG_ BladeCtrlModeLeft : 24|4@1+ (1,0) [0|15] "" Vector__XXX

BO_ 2633926654 IT6: 8 Vector__XXX
   SG_ EngActualIgntTiming : 48|16@1+ (0.0078125,-200) [-200|301.99] "deg" Vector__XXX
   SG_ EngDesiredIgntTiming3 : 32|16@1+ (0.0078125,-200) [-200|301.99] "deg" Vector__XXX
   SG_ EngDesiredIgntTiming2 : 16|16@1+ (0.0078125,-200) [-200|301.99] "deg" Vector__XXX
   SG_ EngDesiredIgntTiming1 : 0|16@1+ (0.0078125,-200) [-200|301.99] "deg" Vector__XXX

BO_ 2633926398 IT5: 8 Vector__XXX
   SG_ EngCyl20IgntTiming : 48|16@1+ (0.0078125,-200) [-200|301.99] "deg" Vector__XXX
   SG_ EngCyl19IgntTiming : 32|16@1+ (0.0078125,-200) [-200|301.99] "deg" Vector__XXX
   SG_ EngCyl18IgntTiming : 16|16@1+ (0.0078125,-200) [-200|301.99] "deg" Vector__XXX
   SG_ EngCyl17IgntTiming : 0|16@1+ (0.0078125,-200) [-200|301.99] "deg" Vector__XXX

BO_ 2633926142 IT4: 8 Vector__XXX
   SG_ EngCyl16IgntTiming : 48|16@1+ (0.0078125,-200) [-200|301.99] "deg" Vector__XXX
   SG_ EngCyl15IgntTiming : 32|16@1+ (0.0078125,-200) [-200|301.99] "deg" Vector__XXX
   SG_ EngCyl14IgntTiming : 16|16@1+ (0.0078125,-200) [-200|301.99] "deg" Vector__XXX
   SG_ EngCyl13IgntTiming : 0|16@1+ (0.0078125,-200) [-200|301.99] "deg" Vector__XXX

BO_ 2633925886 IT3: 8 Vector__XXX
   SG_ EngCyl12IgntTiming : 48|16@1+ (0.0078125,-200) [-200|301.99] "deg" Vector__XXX
   SG_ EngCyl11IgntTiming : 32|16@1+ (0.0078125,-200) [-200|301.99] "deg" Vector__XXX
   SG_ EngCyl10IgntTiming : 16|16@1+ (0.0078125,-200) [-200|301.99] "deg" Vector__XXX
   SG_ EngCyl9IgntTiming : 0|16@1+ (0.0078125,-200) [-200|301.99] "deg" Vector__XXX

BO_ 2633925630 IT2: 8 Vector__XXX
   SG_ EngCyl8IgntTiming : 48|16@1+ (0.0078125,-200) [-200|301.99] "deg" Vector__XXX
   SG_ EngCyl7IgntTiming : 32|16@1+ (0.0078125,-200) [-200|301.99] "deg" Vector__XXX
   SG_ EngCyl6IgntTiming : 16|16@1+ (0.0078125,-200) [-200|301.99] "deg" Vector__XXX
   SG_ EngCyl5IgntTiming : 0|16@1+ (0.0078125,-200) [-200|301.99] "deg" Vector__XXX

BO_ 2633925374 IT1: 8 Vector__XXX
   SG_ EngCyl4IgntTiming : 48|16@1+ (0.0078125,-200) [-200|301.99] "deg" Vector__XXX
   SG_ EngCyl3IgntTiming : 32|16@1+ (0.0078125,-200) [-200|301.99] "deg" Vector__XXX
   SG_ EngCyl2IgntTiming : 16|16@1+ (0.0078125,-200) [-200|301.99] "deg" Vector__XXX
   SG_ EngCyl1IgntTiming : 0|16@1+ (0.0078125,-200) [-200|301.99] "deg" Vector__XXX

BO_ 2633927422 ISO3: 8 Vector__XXX
   SG_ EngCyl20IgntTransSecondOutput : 24|8@1+ (1,-125) [-125|125] "%" Vector__XXX
   SG_ EngCyl19IgntTransSecondOutput : 16|8@1+ (1,-125) [-125|125] "%" Vector__XXX
   SG_ EngCyl18IgntTransSecondOutput : 8|8@1+ (1,-125) [-125|125] "%" Vector__XXX
   SG_ EngCyl17IgntTransSecondOutput : 0|8@1+ (1,-125) [-125|125] "%" Vector__XXX

BO_ 2633927166 ISO2: 8 Vector__XXX
   SG_ EngCyl16IgntTransSecondOutput : 56|8@1+ (1,-125) [-125|125] "%" Vector__XXX
   SG_ EngCyl15IgntTransSecondOutput : 48|8@1+ (1,-125) [-125|125] "%" Vector__XXX
   SG_ EngCyl14IgntTransSecondOutput : 40|8@1+ (1,-125) [-125|125] "%" Vector__XXX
   SG_ EngCyl13IgntTransSecondOutput : 32|8@1+ (1,-125) [-125|125] "%" Vector__XXX
   SG_ EngCyl12IgntTransSecondOutput : 24|8@1+ (1,-125) [-125|125] "%" Vector__XXX
   SG_ EngCyl11IgntTransSecondOutput : 16|8@1+ (1,-125) [-125|125] "%" Vector__XXX
   SG_ EngCyl10IgntTransSecondOutput : 8|8@1+ (1,-125) [-125|125] "%" Vector__XXX
   SG_ EngCyl9IgntTransSecondOutput : 0|8@1+ (1,-125) [-125|125] "%" Vector__XXX

CM_ BO_ 2147483648 "This is a message for not used signals, created by Vector CANdb++ DBC OLE DB Provider.";
CM_ SG_ 2147483648 TrailerWeight "Total mass of freight-carrying vehicle designed to be pulled by truck, including the weight of the contents.";
CM_ SG_ 2147483648 ReferenceTirePressSetting "Reference value of the tire pressure setting as basis for the tire pressure monitoring";
CM_ SG_ 2147483648 ReferenceTirePress "Reference value of the tire pressure as basis for the tire pressure monitoring";
CM_ SG_ 2147483648 TirePressThresholdDetection "Signal indicating the pressure level of the tire.";
CM_ SG_ 2147483648 TireAirLeakageRate "The pressure loss rate of a tire.";
CM_ SG_ 2147483648 CTIWheelEndElectricalFault "Indicates the status of electrical fault on CTI wheel interface.";
CM_ SG_ 2147483648 CTITireStatus "Indicates the status of the tire.";
CM_ SG_ 2147483648 CTIWheelSensorStatus "Indicates whether the wheel is being monitored by the CTI controller.";
CM_ SG_ 2147483648 TireTemp "Temperature at the surface of the tire sidewall.";
CM_ SG_ 2147483648 TirePress "Pressure at which air is contained in cavity formed by tire and rim.";
CM_ SG_ 2297441790 SpprtVrblTrnsRpttnRtFrAcclrtnSns "Indicates which acceleration transmission rate are supported by the ECU in addition to the required 10 ms transmission";
CM_ SG_ 2297441790 VrtclAcclrtnExRngeFigureOfMerit "Figure of merit for vertical acceleration measurement.";
CM_ SG_ 2297441790 LngtdnlAcclrtnExRngFgureOfMerit "Figure of merit for longitudinal acceleration measurement.";
CM_ SG_ 2297441790 LtrlAcclrtnExRangeFigureOfMerit "Figure of merit for lateral acceleration measurement.";
CM_ SG_ 2297441790 VerticalAccelerationExRange "Indicates vertical acceleration of the vehicle and the effect of gravity.";
CM_ SG_ 2297441790 LateralAccelerationExRange "Indicates lateral acceleration of the vehicle.";
CM_ SG_ 2297441790 LongitudinalAccelerationExRange "Indicates longitudinal acceleration of the vehicle.";
CM_ BO_ 2566712062 "Vehicle Electrical Power #4";
CM_ SG_ 2566712062 HybrdBatteryPackRemainingCharge "Indicates the hybrid battery pack remaining charge.";
CM_ BO_ 2364549630 "Slope Sensor Information 2";
CM_ SG_ 2364549630 RllAndPtchExRngMsurementLatency "Time between start of sensor processing and CAN transmission";
CM_ SG_ 2364549630 RollAngleExRangeFigureOfMerit "Figure of merit for roll angle measurement.";
CM_ SG_ 2364549630 RollAngleExRangeCompensation "Compensated mode for the roll measurement.";
CM_ SG_ 2364549630 PitchAngleExRangeFigureOfMerit "Figure of merit for pitch angle measurement.";
CM_ SG_ 2364549630 PitchAngleExRangeCompensation "Compensated mode for the pitch measurement.";
CM_ SG_ 2364549630 RollAngleExRange "The angle between the vehicle y-axis and the ground plane.";
CM_ SG_ 2364549630 PitchAngleExRange "The angle between the vehicle x-axis and the ground plane.";
CM_ BO_ 2499614462 "Occupant Classification System Information";
CM_ SG_ 2499614462 OccpntClssfcationSystem10Status "State of Occupant Classification System for seat position 10.";
CM_ SG_ 2499614462 OccpntClssficationSystem9Status "State of Occupant Classification System for seat position 9.";
CM_ SG_ 2499614462 OccpntClssficationSystem8Status "State of Occupant Classification System for seat position 8.";
CM_ SG_ 2499614462 OccpntClssficationSystem7Status "State of Occupant Classification System for seat position 7.";
CM_ SG_ 2499614462 OccpntClssficationSystem6Status "State of Occupant Classification System for seat position 6.";
CM_ SG_ 2499614462 OccpntClssficationSystem5Status "State of Occupant Classification System for seat position 5.";
CM_ SG_ 2499614462 OccpntClssficationSystem4Status "State of Occupant Classification System for seat position 4.";
CM_ SG_ 2499614462 OccpntClssficationSystem3Status "State of Occupant Classification System for seat position 3.";
CM_ SG_ 2499614462 PssngrOccpntClssfctnSystmStatus "State of Occupant Classification System for passenger.";
CM_ SG_ 2499614462 DrvrOccpntClssfctonSystemStatus "State of Occupant Classification System for driver.";
CM_ BO_ 2560098046 "Noise Control Status";
CM_ SG_ 2560098046 CabNoiseCtrlTuningStatus "This parameter returns the current status of tuning function of the Cab Noise Control system.";
CM_ SG_ 2560098046 CabNoiseCtrlStatus "This parameter returns the current status of the Cab Noise Control system.";
CM_ BO_ 2560163582 "Noise Control 1";
CM_ SG_ 2560163582 CabNoiseCtrlTuningState "Command values for the Tuning State of the Cab Noise Control System.";
CM_ SG_ 2560163582 CabNoiseCtrlState "Command signal to change the state of the Cab Noise Control System to on-line or off-line";
CM_ BO_ 2297441534 "Magnet Status Information 2";
CM_ SG_ 2297441534 DropRelayCtrl "Command signal used to Engage and Disengage the Drop Relay controlling a Steady-State Magnet.";
CM_ SG_ 2297441534 LiftRelayCtrl "Command signal used to Engage and Disengage the Lift Relay controlling a Steady-State Magnet.";
CM_ SG_ 2297441534 MaterialDropActiveStatus "The status of Material Drop Relay.";
CM_ SG_ 2297441534 MaterialLiftActiveStatus "The status of Material Lift Relay.";
CM_ SG_ 2297441534 GnratorCurrentBoostActiveStatus "Status of generator current boost relay that can boost the generator output current for picking-up material operations.";
CM_ SG_ 2297441534 MaterialDropSwitch "This is a switch that can be used to enable the drop functionality of the Material Handler machine.";
CM_ SG_ 2297441534 MaterialLiftSwitch "This is a switch that can be used to enable the lift functionality of the Material Handler machine.";
CM_ SG_ 2297441534 MagnetReverseCurrent "A reverse current being supplied to the electric magnet to reduce the forward current generated magnet field as quick as";
CM_ SG_ 2297441534 MagnetForwardCurrent "The forward current being supplied by the generator to the electric magnet to create a magnet field to lift material.";
CM_ BO_ 2566722302 "Magnet Status Information 1";
CM_ SG_ 2566722302 GneratorDutyCycleExceededStatus "The status of the duty cycle of the generator usage, indicating if the generator has been on for too much time within a";
CM_ SG_ 2566722302 VoltageMonitorActiveStatus "Status of Voltage Monitor Relay.";
CM_ SG_ 2566722302 GensetEnableActiveStatus "Status of the Genset Enable Relay that enables or disables the Genset.";
CM_ SG_ 2566722302 ReverseCurrentRangeSetting "The operator setting for the Reverse Current.";
CM_ SG_ 2566722302 GensetSoftstartActiveStatus "The Genset Softstart Active Status refers to the status of the genset softstart relay.";
CM_ SG_ 2566722302 Grapple_MagnetSelectionSwitch "This is a switch that can be used to select either the Grapple or Magnet function of the material handler machine.";
CM_ SG_ 2566722302 GnstSystmOtptVoltageRangeStatus "Status of generator voltage in or out of desired operating range.";
CM_ SG_ 2566722302 GeneratorOverheatStatus "The Status of Generator being Overheated.";
CM_ BO_ 2566722558 "Magnet System Configuration Information";
CM_ SG_ 2566722558 MagnetRatedPower "The rated power that the magnet can accept during material holding operations.";
CM_ SG_ 2566722558 MagnetBoostTime "The duration of time after the activation of the magnet circuit that a relatively high current is sent to the magnet for";
CM_ BO_ 2560032510 "Low Voltage Disconnect Set Operating Mode";
CM_ SG_ 2560032510 LwVltgDscnnctDsredOperatingMode "Desired Operating Mode of the LVD.";
CM_ BO_ 2566717950 "Low Voltage Disconnect Status";
CM_ SG_ 2566717950 LowVoltageDisconnectTemp "Internal temperature of the LVD.";
CM_ SG_ 2566717950 LwVltgDisconnectVoutOutputState "State of the Vout Output from the LVD.";
CM_ SG_ 2566717950 LwVoltageDisconnectOutput1State "State of the Output #1 from the LVD.";
CM_ SG_ 2566717950 LwVoltageDisconnectOutput2State "State of the Output #2 from the LVD.";
CM_ SG_ 2566717950 LwVoltageDisconnectOutput3State "State of the Output #3 from the LVD.";
CM_ SG_ 2566717950 LwVltgDscnnctCrrntOperatingMode "Current operating mode of the LVD.";
CM_ SG_ 2566717950 LwVltgDscnnctManualConnectState "State of the Manual Connect hardwired input to the LVD.";
CM_ SG_ 2566717950 LwVltgDscnnctMnlDisconnectState "State of the Manual Disconnect hardwired input to the LVD.";
CM_ BO_ 2499604222 "Land Leveling System Reference Elevation Data";
CM_ SG_ 2499604222 BldRferenceElevationOffsetRight "Indicates the blade's right elevation offset with respect to the reference elevation.";
CM_ SG_ 2499604222 BldReferenceElevationOffsetLeft "Indicates the blade's left elevation offset with respect to the reference elevation.";
CM_ SG_ 2499604222 BladeElevationDeviationRight "Indicate the blade's right elevation deviation with respect to the reference elevation.";
CM_ SG_ 2499604222 BladeElevationDeviationLeft "Indicate the blade's left elevation deviation with respect to the reference elevation.";
CM_ BO_ 2358902526 "Joystick Lamp Command Message";
CM_ SG_ 2358902526 Joystick3Lamp10Cmd "Tells joystick 3 to switch on/off/blinking lamp 10.";
CM_ SG_ 2358902526 Joystick3Lamp9Cmd "Tells joystick 3 to switch on/off/blinking lamp 9.";
CM_ SG_ 2358902526 Joystick3Lamp8Cmd "Tells joystick 3 to switch on/off/blinking lamp 8.";
CM_ SG_ 2358902526 Joystick3Lamp7Cmd "Tells joystick 3 to switch on/off/blinking lamp 7.";
CM_ SG_ 2358902526 Joystick3Lamp6Cmd "Tells joystick 3 to switch on/off/blinking lamp 6.";
CM_ SG_ 2358902526 Joystick3Lamp5Cmd "Tells joystick 3 to switch on/off/blinking lamp 5.";
CM_ SG_ 2358902526 Joystick3Lamp4Cmd "Tells joystick 3 to switch on/off/blinking lamp 4.";
CM_ SG_ 2358902526 Joystick3Lamp3Cmd "Tells joystick 3 to switch on/off/blinking lamp 3.";
CM_ SG_ 2358902526 Joystick3Lamp2Cmd "Tells joystick 3 to switch on/off/blinking lamp 2.";
CM_ SG_ 2358902526 Joystick3Lamp1Cmd "Tells joystick 3 to switch on/off/blinking lamp 1.";
CM_ SG_ 2358902526 Joystick2Lamp10Cmd "Tells joystick 2 to switch on/off/blinking lamp 10.";
CM_ SG_ 2358902526 Joystick2Lamp9Cmd "Tells joystick 2 to switch on/off/blinking lamp 9.";
CM_ SG_ 2358902526 Joystick2Lamp8Cmd "Tells joystick 2 to switch on/off/blinking lamp 8.";
CM_ SG_ 2358902526 Joystick2Lamp7Cmd "Tells joystick 2 to switch on/off/blinking lamp 7.";
CM_ SG_ 2358902526 Joystick2Lamp6Cmd "Tells joystick 2 to switch on/off/blinking lamp 6.";
CM_ SG_ 2358902526 Joystick2Lamp5Cmd "Tells joystick 2 to switch on/off/blinking lamp 5.";
CM_ SG_ 2358902526 Joystick2Lamp4Cmd "Tells joystick 2 to switch on/off/blinking lamp 4.";
CM_ SG_ 2358902526 Joystick2Lamp3Cmd "Tells joystick 2 to switch on/off/blinking lamp 3.";
CM_ SG_ 2358902526 Joystick2Lamp2Cmd "Tells joystick 2 to switch on/off/blinking lamp 2.";
CM_ SG_ 2358902526 Joystick2Lamp1Cmd "Tells joystick 2 to switch on/off/blinking lamp 1.";
CM_ SG_ 2358902526 Joystick1Lamp10Cmd "Tells joystick 1 to switch on/off/blinking lamp 10.";
CM_ SG_ 2358902526 Joystick1Lamp9Cmd "Tells joystick 1 to switch on/off/blinking lamp 9.";
CM_ SG_ 2358902526 Joystick1Lamp8Cmd "Tells joystick 1 to switch on/off/blinking lamp 8.";
CM_ SG_ 2358902526 Joystick1Lamp7Cmd "Tells joystick 1 to switch on/off/blinking lamp 7.";
CM_ SG_ 2358902526 Joystick1Lamp6Cmd "Tells joystick 1 to switch on/off/blinking lamp 6.";
CM_ SG_ 2358902526 Joystick1Lamp5Cmd "Tells joystick 1 to switch on/off/blinking lamp 5.";
CM_ SG_ 2358902526 Joystick1Lamp4Cmd "Tells joystick 1 to switch on/off/blinking lamp 4.";
CM_ SG_ 2358902526 Joystick1Lamp3Cmd "Tells joystick 1 to switch on/off/blinking lamp 3.";
CM_ SG_ 2358902526 Joystick1Lamp2Cmd "Tells joystick 1 to switch on/off/blinking lamp 2.";
CM_ SG_ 2358902526 Joystick1Lamp1Cmd "Tells joystick 1 to switch on/off/blinking lamp 1.";
CM_ BO_ 2566711550 "Intake Valve Actuation Control";
CM_ SG_ 2566711550 IntkVlvActtnSystmOlPrss2SlndCtrl "Indicates the current command to the solenoid that controls the intake valve actuation system oil pressure 2 valve.";
CM_ SG_ 2566711550 IntkVlvActtnSystmOlPrss1SlndCtrl "Indicates the current command to the solenoid that controls the intake valve actuation system oil pressure 1 valve.";
CM_ BO_ 2633832958 "Ignitor Loop Information";
CM_ SG_ 2633832958 SpecialIgnitorLoop90Resistance "Resistance of Special Ignitor Loop 90.";
CM_ SG_ 2633832958 SpecialIgnitorLoop89Resistance "Resistance of Special Ignitor Loop 89.";
CM_ SG_ 2633832958 SpecialIgnitorLoop88Resistance "Resistance of Special Ignitor Loop 88.";
CM_ SG_ 2633832958 SpecialIgnitorLoop87Resistance "Resistance of Special Ignitor Loop 87.";
CM_ SG_ 2633832958 SpecialIgnitorLoop86Resistance "Resistance of Special Ignitor Loop 86.";
CM_ SG_ 2633832958 SpecialIgnitorLoop85Resistance "Resistance of Special Ignitor Loop 85.";
CM_ SG_ 2633832958 SpecialIgnitorLoop84Resistance "Resistance of Special Ignitor Loop 84.";
CM_ SG_ 2633832958 SpecialIgnitorLoop83Resistance "Resistance of Special Ignitor Loop 83.";
CM_ SG_ 2633832958 SpecialIgnitorLoop82Resistance "Resistance of Special Ignitor Loop 82.";
CM_ SG_ 2633832958 SpecialIgnitorLoop81Resistance "Resistance of Special Ignitor Loop 81.";
CM_ SG_ 2633832958 SpecialIgnitorLoop80Resistance "Resistance of Special Ignitor Loop 80.";
CM_ SG_ 2633832958 SpecialIgnitorLoop79Resistance "Resistance of Special Ignitor Loop 79.";
CM_ SG_ 2633832958 SpecialIgnitorLoop78Resistance "Resistance of Special Ignitor Loop 78.";
CM_ SG_ 2633832958 SpecialIgnitorLoop77Resistance "Resistance of Special Ignitor Loop 77.";
CM_ SG_ 2633832958 SpecialIgnitorLoop76Resistance "Resistance of Special Ignitor Loop 76.";
CM_ SG_ 2633832958 SpecialIgnitorLoop75Resistance "Resistance of Special Ignitor Loop 75.";
CM_ SG_ 2633832958 SpecialIgnitorLoop74Resistance "Resistance of Special Ignitor Loop 74.";
CM_ SG_ 2633832958 SpecialIgnitorLoop73Resistance "Resistance of Special Ignitor Loop 73.";
CM_ SG_ 2633832958 SpecialIgnitorLoop72Resistance "Resistance of Special Ignitor Loop 72.";
CM_ SG_ 2633832958 SpecialIgnitorLoop71Resistance "Resistance of Special Ignitor Loop 71.";
CM_ SG_ 2633832958 SpecialIgnitorLoop70Resistance "Resistance of Special Ignitor Loop 70.";
CM_ SG_ 2633832958 SpecialIgnitorLoop69Resistance "Resistance of Special Ignitor Loop 69.";
CM_ SG_ 2633832958 SpecialIgnitorLoop68Resistance "Resistance of Special Ignitor Loop 68.";
CM_ SG_ 2633832958 SpecialIgnitorLoop67Resistance "Resistance of Special Ignitor Loop 67.";
CM_ SG_ 2633832958 SpecialIgnitorLoop66Resistance "Resistance of Special Ignitor Loop 66.";
CM_ SG_ 2633832958 SpecialIgnitorLoop65Resistance "Resistance of Special Ignitor Loop 65.";
CM_ SG_ 2633832958 SpecialIgnitorLoop64Resistance "Resistance of Special Ignitor Loop 64.";
CM_ SG_ 2633832958 SpecialIgnitorLoop63Resistance "Resistance of Special Ignitor Loop 63.";
CM_ SG_ 2633832958 SpecialIgnitorLoop61Resistance "Resistance of Special Ignitor Loop 61.";
CM_ SG_ 2633832958 SpecialIgnitorLoop60Resistance "Resistance of Special Ignitor Loop 60.";
CM_ SG_ 2633832958 SpecialIgnitorLoop59Resistance "Resistance of Special Ignitor Loop 59.";
CM_ SG_ 2633832958 SpecialIgnitorLoop58Resistance "Resistance of Special Ignitor Loop 58.";
CM_ SG_ 2633832958 SpecialIgnitorLoop57Resistance "Resistance of Special Ignitor Loop 57.";
CM_ SG_ 2633832958 SpecialIgnitorLoop56Resistance "Resistance of Special Ignitor Loop 56.";
CM_ SG_ 2633832958 SpecialIgnitorLoop55Resistance "Resistance of Special Ignitor Loop 55.";
CM_ SG_ 2633832958 SpecialIgnitorLoop54Resistance "Resistance of Special Ignitor Loop 54.";
CM_ SG_ 2633832958 SpecialIgnitorLoop53Resistance "Resistance of Special Ignitor Loop 53.";
CM_ SG_ 2633832958 SpecialIgnitorLoop52Resistance "Resistance of Special Ignitor Loop 52.";
CM_ SG_ 2633832958 SpecialIgnitorLoop51Resistance "Resistance of Special Ignitor Loop 51.";
CM_ SG_ 2633832958 SpecialIgnitorLoop50Resistance "Resistance of Special Ignitor Loop 50.";
CM_ SG_ 2633832958 SpecialIgnitorLoop49Resistance "Resistance of Special Ignitor Loop 49.";
CM_ SG_ 2633832958 SpecialIgnitorLoop48Resistance "Resistance of Special Ignitor Loop 48.";
CM_ SG_ 2633832958 SpecialIgnitorLoop47Resistance "Resistance of Special Ignitor Loop 47.";
CM_ SG_ 2633832958 SpecialIgnitorLoop46Resistance "Resistance of Special Ignitor Loop 46.";
CM_ SG_ 2633832958 SpecialIgnitorLoop45Resistance "Resistance of Special Ignitor Loop 45.";
CM_ SG_ 2633832958 SpecialIgnitorLoop44Resistance "Resistance of Special Ignitor Loop 44.";
CM_ SG_ 2633832958 SpecialIgnitorLoop43Resistance "Resistance of Special Ignitor Loop 43.";
CM_ SG_ 2633832958 SpecialIgnitorLoop42Resistance "Resistance of Special Ignitor Loop 42.";
CM_ SG_ 2633832958 SpecialIgnitorLoop41Resistance "Resistance of Special Ignitor Loop 41.";
CM_ SG_ 2633832958 SpecialIgnitorLoop40Resistance "Resistance of Special Ignitor Loop 40.";
CM_ SG_ 2633832958 SpecialIgnitorLoop39Resistance "Resistance of Special Ignitor Loop 39.";
CM_ SG_ 2633832958 SpecialIgnitorLoop38Resistance "Resistance of Special Ignitor Loop 38.";
CM_ SG_ 2633832958 SpecialIgnitorLoop37Resistance "Resistance of Special Ignitor Loop 37.";
CM_ SG_ 2633832958 SpecialIgnitorLoop36Resistance "Resistance of Special Ignitor Loop 36.";
CM_ SG_ 2633832958 SpecialIgnitorLoop35Resistance "Resistance of Special Ignitor Loop 35.";
CM_ SG_ 2633832958 SpecialIgnitorLoop34Resistance "Resistance of Special Ignitor Loop 34.";
CM_ SG_ 2633832958 SpecialIgnitorLoop33Resistance "Resistance of Special Ignitor Loop 33.";
CM_ SG_ 2633832958 SpecialIgnitorLoop32Resistance "Resistance of Special Ignitor Loop 32.";
CM_ SG_ 2633832958 SpecialIgnitorLoop31Resistance "Resistance of Special Ignitor Loop 31.";
CM_ SG_ 2633832958 SpecialIgnitorLoop30Resistance "Resistance of Special Ignitor Loop 30.";
CM_ SG_ 2633832958 SpecialIgnitorLoop29Resistance "Resistance of Special Ignitor Loop 29.";
CM_ SG_ 2633832958 SpecialIgnitorLoop28Resistance "Resistance of Special Ignitor Loop 28.";
CM_ SG_ 2633832958 SpecialIgnitorLoop27Resistance "Resistance of Special Ignitor Loop 27.";
CM_ SG_ 2633832958 SpecialIgnitorLoop26Resistance "Resistance of Special Ignitor Loop 26.";
CM_ SG_ 2633832958 SpecialIgnitorLoop25Resistance "Resistance of Special Ignitor Loop 25.";
CM_ SG_ 2633832958 SpecialIgnitorLoop24Resistance "Resistance of Special Ignitor Loop 24.";
CM_ SG_ 2633832958 SpecialIgnitorLoop23Resistance "Resistance of Special Ignitor Loop 23.";
CM_ SG_ 2633832958 SpecialIgnitorLoop22Resistance "Resistance of Special Ignitor Loop 22.";
CM_ SG_ 2633832958 SpecialIgnitorLoop21Resistance "Resistance of Special Ignitor Loop 21.";
CM_ SG_ 2633832958 SpecialIgnitorLoop20Resistance "Resistance of Special Ignitor Loop 20.";
CM_ SG_ 2633832958 SpecialIgnitorLoop19Resistance "Resistance of Special Ignitor Loop 19.";
CM_ SG_ 2633832958 SpecialIgnitorLoop18Resistance "Resistance of Special Ignitor Loop 18.";
CM_ SG_ 2633832958 SpecialIgnitorLoop17Resistance "Resistance of Special Ignitor Loop 17.";
CM_ SG_ 2633832958 SpecialIgnitorLoop16Resistance "Resistance of Special Ignitor Loop 16.";
CM_ SG_ 2633832958 SpecialIgnitorLoop15Resistance "Resistance of Special Ignitor Loop 15.";
CM_ SG_ 2633832958 SpecialIgnitorLoop14Resistance "Resistance of Special Ignitor Loop 14.";
CM_ SG_ 2633832958 SpecialIgnitorLoop13Resistance "Resistance of Special Ignitor Loop 13.";
CM_ SG_ 2633832958 SpecialIgnitorLoop12Resistance "Resistance of Special Ignitor Loop 12.";
CM_ SG_ 2633832958 SpecialIgnitorLoop11Resistance "Resistance of Special Ignitor Loop 11.";
CM_ SG_ 2633832958 SpecialIgnitorLoop10Resistance "Resistance of Special Ignitor Loop 10.";
CM_ SG_ 2633832958 SpecialIgnitorLoop9Resistance "Resistance of Special Ignitor Loop 9.";
CM_ SG_ 2633832958 SpecialIgnitorLoop8Resistance "Resistance of Special Ignitor Loop 8.";
CM_ SG_ 2633832958 SpecialIgnitorLoop7Resistance "Resistance of Special Ignitor Loop 7.";
CM_ SG_ 2633832958 SpecialIgnitorLoop6Resistance "Resistance of Special Ignitor Loop 6.";
CM_ SG_ 2633832958 SpecialIgnitorLoop5Resistance "Resistance of Special Ignitor Loop 5.";
CM_ SG_ 2633832958 SpecialIgnitorLoop4Resistance "Resistance of Special Ignitor Loop 4.";
CM_ SG_ 2633832958 SpecialIgnitorLoop3Resistance "Resistance of Special Ignitor Loop 3.";
CM_ SG_ 2633832958 SpecialIgnitorLoop2Resistance "Resistance of Special Ignitor Loop 2.";
CM_ SG_ 2633832958 SpecialIgnitorLoop1Resistance "Resistance of Special Ignitor Loop 1.";
CM_ SG_ 2633832958 SdBgIgnitorLoop2RightResistance "Resistance of Side Bag Ignitor Loop 2 - Right.";
CM_ SG_ 2633832958 SdBgIgnitorLoop1RightResistance "Resistance of Side Bag Ignitor Loop 1 - Right.";
CM_ SG_ 2633832958 SdBagIgnitorLoop2LeftResistance "Resistance of Side Bag Ignitor Loop 2 - Left.";
CM_ SG_ 2633832958 SdBagIgnitorLoop1LeftResistance "Resistance of Side Bag Ignitor Loop 1 - Left.";
CM_ SG_ 2633832958 PssngrBltTnsnrIgntrLpResistance "Resistance of Passenger Belt Tensioner Ignitor Loop 1st Stage.";
CM_ SG_ 2633832958 DrvrBltTnsnrIgntrLoopResistance "Resistance of Driver Belt Tensioner Ignitor Loop 1st Stage.";
CM_ SG_ 2633832958 PssngrArbgIgntrLp2ndStgRsstance "Resistance of Passenger Airbag Ignitor Loop 2nd Stage.";
CM_ SG_ 2633832958 DrvrArbgIgntrLp2ndStgResistance "Resistance of Driver Airbag Ignitor Loop 2nd Stage.";
CM_ SG_ 2633832958 PssngrArbgIgntrLp1stStgRsstance "Resistance of Passenger Airbag Ignitor Loop 1st Stage.";
CM_ SG_ 2633832958 DrvrArbgIgntrLp1stStgResistance "Resistance of Driver Airbag Ignitor Loop 1st Stage.";
CM_ BO_ 2566719998 "High Resolution Fuel Consumption (Liquid)";
CM_ SG_ 2566719998 HighResolutionEngTotalFuelUsed "Accumulated amount of fuel used during vehicle operation.";
CM_ SG_ 2566719998 HighResolutionEngTripFuel "Fuel consumed during all or part of a journey.";
CM_ BO_ 2565877502 "Engine Turbocharger Wastegate Actuator Control Command";
CM_ SG_ 2565877502 EngTurboWastegateActuator2Cmd "The command to a Turbocharger Wastegate actuator 2, normalized to percent, where 0% nominally represents fully";
CM_ SG_ 2565877502 EngTurboWastegateActuator1Cmd "The ccommand to a Turbocharger Wastegate actuator 1, normalized to percent, where 0% nominally represents fully";
CM_ BO_ 2566713854 "Engine Turbocharger Wastegate Actuator Information";
CM_ SG_ 2566713854 EngTrbWstgtActtr2OprationStatus "Used to identify the status of Engine Turbocharger Wastegate Actuator 2";
CM_ SG_ 2566713854 EngTrbWstgtActtr1OprationStatus "Used to identify the status of Engine Turbocharger Wastegate Actuator 1";
CM_ SG_ 2566713854 EngTrbWstgteActuator2TempStatus "Used to identify the status of the Engine Turbocharger Wastegate Actuator 2 drive circuitry temperature.";
CM_ SG_ 2566713854 EngTrbWstgtActtr2PreliminaryFMI "Used to identify the applicable J1939-73 FMI detected in the Engine Turbocharger Wastegate Actuator 2 by the";
CM_ BO_ 2566714366 "Engine Turbocharger Compressor Bypass Information";
CM_ SG_ 2566714366 EngTrbCmprssrBypssActtr2OprtnStt "Used to identify the status of Engine Turbocharger Compressor Bypass Actuator 2";
CM_ SG_ 2566714366 EngTrbCmprssrBypssActtr1OprtnStt "Used to identify the status of Engine Turbocharger Compressor Bypass Actuator 1";
CM_ SG_ 2566714366 EngTrbCmprssrBypssActtr2TmpStts "Used to identify the status of the Engine Turbocharger Compresssor Bypass Actuator 2 drive circuitry temperature.";
CM_ SG_ 2566714366 EngTrbCmprssrBypssActtr2PrlmnryF "Used to identify the applicable J1939-73 FMI detected in the Engine Turbocharger Compressor Bypass Actuator 1 by the";
CM_ SG_ 2566714366 EngDsrdTrbCmprssrBypssActtr2Pos "The desired position of the Engine Turbocharger Compressor Bypass actuator 2 by the engine ECM, where 0%";
CM_ SG_ 2566714366 EngTrbCmprssrBypassActuator2Pos "Measures the position of the turbocharger compressor bypass actuator 2, where 0% represents bypass fully closed and";
CM_ BO_ 2566714110 "Engine Fuel/Throttle Valve Information";
CM_ SG_ 2566714110 EngFuelValve2OperationStatus "Used to identify the status of Engine Fuel Valve 2";
CM_ SG_ 2566714110 EngFuelValve1OperationStatus "Used to identify the status of Engine Fuel Valve 1";
CM_ SG_ 2566714110 EngThrttleValve2OperationStatus "Used to identify the status of Engine Throttle Valve 2";
CM_ SG_ 2566714110 EngThrttleValve1OperationStatus "Used to identify the status of Engine Throttle Valve 1";
CM_ SG_ 2566714110 EngFuelValve2TempStatus "Used to identify the status of the Engine Fuel valve 2 drive circuitry temperature.";
CM_ SG_ 2566714110 EngFuelValve2PreliminaryFMI "Used to identify the applicable J1939-73 FMI detected in the Engine Fuel Valve 2 by the manufacturers software.";
CM_ SG_ 2566714110 EngFuelValve1TempStatus "Used to identify the status of the Engine Fuel valve 1 drive circuitry temperature.";
CM_ SG_ 2566714110 EngFuelValve1PreliminaryFMI "Used to identify the applicable J1939-73 FMI detected in the Engine Fuel Valve 1 by the manufacturers software.";
CM_ SG_ 2566714110 EngThrottleValve2TempStatus "Used to identify the status of the Engine Throttle Valve 2 drive circuitry temperature.";
CM_ SG_ 2566714110 EngThrottleValve2PreliminaryFMI "Used to identify the applicable J1939-73 FMI detected in the Engine Throttle Valve 2 by the manufacturers software.";
CM_ SG_ 2566714110 EngDesiredThrottleValve2Pos "The desired position of the Throttle valve 2 that is regulating the fluid, usually air/fuel mixture to the engine as";
CM_ SG_ 2566714110 EngThrottleValve1TempStatus "Used to identify the status of the Engine Throttle Valve 1 drive circuitry temperature.";
CM_ SG_ 2566714110 EngThrottleValve1PreliminaryFMI "Used to identify the appplicable J1939-73 FMI detected in the Engine Throttle Valve 1 by the manufacturers software.";
CM_ SG_ 2566714110 EngDesiredThrottleValve1Pos "The desired position of the Throttle valve 1 that is regulating the fluid, usually air/fuel mixture to the engine as";
CM_ BO_ 2566717438 "Engine Temperature 5";
CM_ SG_ 2566717438 EngExhstGsRcrcltn2MxrIntakeTemp "The temperature of the EGR gas entering the intake of EGR2 system mixer.";
CM_ SG_ 2566717438 EngExhaustGasRecirculation2Temp "Temperature of Recirculated Exhaust Gas of EGR2";
CM_ BO_ 2633828606 "Engine oil message";
CM_ SG_ 2633828606 EngOilRelativeDielectricity "Engine oil relative dielectricity used to describe the engine oil quality.";
CM_ SG_ 2633828606 EngOilDensity "Density of the engine oil";
CM_ SG_ 2633828606 EngOilViscosity "Dynamic viscosity of the engine oil";
CM_ BO_ 2499607550 "Engine Manifold Actuator Position";
CM_ SG_ 2499607550 EngExhstMnfldBnk2FlwBlncVlvActtr "Actual percentage of maximum Engine Manifold Bank 2 Balance valve opening.";
CM_ SG_ 2499607550 EngExhstMnfldBnk1FlwBlncVlvActtr "Actual percentage of maximum Engine Exhaust Manifold Bank 1 Balance valve opening.";
CM_ BO_ 2633825534 "Engine Manifold Actuator Control";
CM_ SG_ 2633825534 EngExhstMnfldBnk2FlwBlncVlv_0000 "Commanded percentage of maximum Engine Ehaust Manifold Bank 2 Balance valve opening.";
CM_ SG_ 2633825534 EngExhstMnfldBnk1FlwBlncVlv_0000 "Commanded percentage of maximum Engine Exhaust Manifold Bank 1 Balance valve opening.";
CM_ BO_ 2365400574 "Extended Joystick Message 9";
CM_ SG_ 2365400574 Jystck9GripXAxisDetentPosStatus "Reports when the current joystick grip position is in the detent position for that axis of travel.";
CM_ SG_ 2365400574 Jystck9GripYAxisDetentPosStatus "Reports when the current joystick grip position is in the detent position for that axis of travel.";
CM_ SG_ 2365400574 Jystck9ThetaAxisDetentPosStatus "Reports when the current joystick position is in the detent position for that axis of travel.";
CM_ SG_ 2365400574 Joystick9ThetaAxisPos "The position of the joystick in the relative motion of travel from the neutral position.";
CM_ SG_ 2365400574 Jystck9ThtAxsClckwsPstvPsStatus "Reports when the current joystick position is on the positive travel side (forward, right, clockwise, up) relative to the";
CM_ SG_ 2365400574 Jystck9ThtAxsCntrClckwsNgtvPsStt "Reports when the current joystick position is on the negative travel side (back, left, counterclockwise, down) relative to the";
CM_ SG_ 2365400574 Jystck9ThtaAxisNeutralPosStatus "Reports when the current joystick position is in the neutral position for that axis of travel.";
CM_ SG_ 2365400574 Joystick9GripYAxisPos "The position of the joystick grip in the relative motion of travel from the neutral position.";
CM_ SG_ 2365400574 Jystck9GrpYAxsLvrFrwrdPstvPsStts "Reports when the current joystick grip position is on the positive travel side (forward, right, clockwise, up) relative to the";
CM_ SG_ 2365400574 Jystck9GrpYAxsLvrBckNgtvPsSttus "Reports when the current joystick grip position is on the negative travel side (back, left, counterclockwise, down) relative";
CM_ SG_ 2365400574 Jystck9GrpYAxisNeutralPosStatus "Reports when the current joystick grip position is in the neutral position for that axis of travel.";
CM_ SG_ 2365400574 Joystick9GripXAxisPos "The position of the joystick grip in the relative motion of travel from the neutral position.";
CM_ SG_ 2365400574 Jystck9GrpXAxsLvrRghtPstvPsStts "Reports when the current joystick grip position is on the positive travel side (forward, right, clockwise, up) relative to the";
CM_ SG_ 2365400574 Jystck9GrpXAxsLvrLftNgtvPsSttus "Reports when the current joystick grip position is on the negative travel side (back, left, counterclockwise, down) relative";
CM_ SG_ 2365400574 Jystck9GrpXAxisNeutralPosStatus "Reports when the current joystick grip position is in the neutral position for that axis of travel.";
CM_ BO_ 2365401086 "Extended Joystick Message 8";
CM_ SG_ 2365401086 Jystck8GripXAxisDetentPosStatus "Reports when the current joystick grip position is in the detent position for that axis of travel.";
CM_ SG_ 2365401086 Jystck8GripYAxisDetentPosStatus "Reports when the current joystick grip position is in the detent position for that axis of travel.";
CM_ SG_ 2365401086 Jystck8ThetaAxisDetentPosStatus "Reports when the current joystick position is in the detent position for that axis of travel.";
CM_ SG_ 2365401086 Joystick8ThetaAxisPos "The position of the joystick in the relative motion of travel from the neutral position.";
CM_ SG_ 2365401086 Jystck8ThtAxsClckwsPstvPsStatus "Reports when the current joystick position is on the positive travel side (forward, right, clockwise, up) relative to the";
CM_ SG_ 2365401086 Jystck8ThtAxsCntrClckwsNgtvPsStt "Reports when the current joystick position is on the negative travel side (back, left, counterclockwise, down) relative to the";
CM_ SG_ 2365401086 Jystck8ThtaAxisNeutralPosStatus "Reports when the current joystick position is in the neutral position for that axis of travel.";
CM_ SG_ 2365401086 Joystick8GripYAxisPos "The position of the joystick grip in the relative motion of travel from the neutral position.";
CM_ SG_ 2365401086 Jystck8GrpYAxsLvrFrwrdPstvPsStts "Reports when the current joystick grip position is on the positive travel side (forward, right, clockwise, up) relative to the";
CM_ SG_ 2365401086 Jystck8GrpYAxsLvrBckNgtvPsSttus "Reports when the current joystick grip position is on the negative travel side (back, left, counterclockwise, down) relative";
CM_ SG_ 2365401086 Jystck8GrpYAxisNeutralPosStatus "Reports when the current joystick grip position is in the neutral position for that axis of travel.";
CM_ SG_ 2365401086 Joystick8GripXAxisPos "The position of the joystick grip in the relative motion of travel from the neutral position.";
CM_ SG_ 2365401086 Jystck8GrpXAxsLvrRghtPstvPsStts "Reports when the current joystick grip position is on the positive travel side (forward, right, clockwise, up) relative to the";
CM_ SG_ 2365401086 Jystck8GrpXAxsLvrLftNgtvPsSttus "Reports when the current joystick grip position is on the negative travel side (back, left, counterclockwise, down) relative";
CM_ SG_ 2365401086 Jystck8GrpXAxisNeutralPosStatus "Reports when the current joystick grip position is in the neutral position for that axis of travel.";
CM_ BO_ 2365401598 "Extended Joystick Message 7";
CM_ SG_ 2365401598 Jystck7GripXAxisDetentPosStatus "Reports when the current joystick grip position is in the detent position for that axis of travel.";
CM_ SG_ 2365401598 Jystck7GripYAxisDetentPosStatus "Reports when the current joystick grip position is in the detent position for that axis of travel.";
CM_ SG_ 2365401598 Jystck7ThetaAxisDetentPosStatus "Reports when the current joystick position is in the detent position for that axis of travel.";
CM_ SG_ 2365401598 Joystick7ThetaAxisPos "The position of the joystick in the relative motion of travel from the neutral position.";
CM_ SG_ 2365401598 Jystck7ThtAxsClckwsPstvPsStatus "Reports when the current joystick position is on the positive travel side (forward, right, clockwise, up) relative to the";
CM_ SG_ 2365401598 Jystck7ThtAxsCntrClckwsNgtvPsStt "Reports when the current joystick position is on the negative travel side (back, left, counterclockwise, down) relative to the";
CM_ SG_ 2365401598 Jystck7ThtaAxisNeutralPosStatus "Reports when the current joystick position is in the neutral position for that axis of travel.";
CM_ SG_ 2365401598 Joystick7GripYAxisPos "The position of the joystick grip in the relative motion of travel from the neutral position.";
CM_ SG_ 2365401598 Jystck7GrpYAxsLvrFrwrdPstvPsStts "Reports when the current joystick grip position is on the positive travel side (forward, right, clockwise, up) relative to the";
CM_ SG_ 2365401598 Jystck7GrpYAxsLvrBckNgtvPsSttus "Reports when the current joystick grip position is on the negative travel side (back, left, counterclockwise, down) relative";
CM_ SG_ 2365401598 Jystck7GrpYAxisNeutralPosStatus "Reports when the current joystick grip position is in the neutral position for that axis of travel.";
CM_ SG_ 2365401598 Joystick7GripXAxisPos "The position of the joystick grip in the relative motion of travel from the neutral position.";
CM_ SG_ 2365401598 Jystck7GrpXAxsLvrRghtPstvPsStts "Reports when the current joystick grip position is on the positive travel side (forward, right, clockwise, up) relative to the";
CM_ SG_ 2365401598 Jystck7GrpXAxsLvrLftNgtvPsSttus "Reports when the current joystick grip position is on the negative travel side (back, left, counterclockwise, down) relative";
CM_ SG_ 2365401598 Jystck7GrpXAxisNeutralPosStatus "Reports when the current joystick grip position is in the neutral position for that axis of travel.";
CM_ BO_ 2365402110 "Extended Joystick Message 6";
CM_ SG_ 2365402110 Jystck6GripXAxisDetentPosStatus "Reports when the current joystick grip position is in the detent position for that axis of travel.";
CM_ SG_ 2365402110 Jystck6GripYAxisDetentPosStatus "Reports when the current joystick grip position is in the detent position for that axis of travel.";
CM_ SG_ 2365402110 Jystck6ThetaAxisDetentPosStatus "Reports when the current joystick position is in the detent position for that axis of travel.";
CM_ SG_ 2365402110 Joystick6ThetaAxisPos "The position of the joystick in the relative motion of travel from the neutral position.";
CM_ SG_ 2365402110 Jystck6ThtAxsClckwsPstvPsStatus "Reports when the current joystick position is on the positive travel side (forward, right, clockwise, up) relative to the";
CM_ SG_ 2365402110 Jystck6ThtAxsCntrClckwsNgtvPsStt "Reports when the current joystick position is on the negative travel side (back, left, counterclockwise, down) relative to the";
CM_ SG_ 2365402110 Jystck6ThtaAxisNeutralPosStatus "Reports when the current joystick position is in the neutral position for that axis of travel.";
CM_ SG_ 2365402110 Joystick6GripYAxisPos "The position of the joystick grip in the relative motion of travel from the neutral position.";
CM_ SG_ 2365402110 Jystck6GrpYAxsLvrFrwrdPstvPsStts "Reports when the current joystick grip position is on the positive travel side (forward, right, clockwise, up) relative to the";
CM_ SG_ 2365402110 Jystck6GrpYAxsLvrBckNgtvPsSttus "Reports when the current joystick grip position is on the negative travel side (back, left, counterclockwise, down) relative";
CM_ SG_ 2365402110 Jystck6GrpYAxisNeutralPosStatus "Reports when the current joystick grip position is in the neutral position for that axis of travel.";
CM_ SG_ 2365402110 Joystick6GripXAxisPos "The position of the joystick grip in the relative motion of travel from the neutral position.";
CM_ SG_ 2365402110 Jystck6GrpXAxsLvrRghtPstvPsStts "Reports when the current joystick grip position is on the positive travel side (forward, right, clockwise, up) relative to the";
CM_ SG_ 2365402110 Jystck6GrpXAxsLvrLftNgtvPsSttus "Reports when the current joystick grip position is on the negative travel side (back, left, counterclockwise, down) relative";
CM_ SG_ 2365402110 Jystck6GrpXAxisNeutralPosStatus "Reports when the current joystick grip position is in the neutral position for that axis of travel.";
CM_ BO_ 2365402622 "Extended Joystick Message 5";
CM_ SG_ 2365402622 Jystck5GripXAxisDetentPosStatus "Reports when the current joystick grip position is in the detent position for that axis of travel.";
CM_ SG_ 2365402622 Jystck5GripYAxisDetentPosStatus "Reports when the current joystick grip position is in the detent position for that axis of travel.";
CM_ SG_ 2365402622 Jystck5ThetaAxisDetentPosStatus "Reports when the current joystick position is in the detent position for that axis of travel.";
CM_ SG_ 2365402622 Joystick5ThetaAxisPos "The position of the joystick in the relative motion of travel from the neutral position.";
CM_ SG_ 2365402622 Jystck5ThtAxsClckwsPstvPsStatus "Reports when the current joystick position is on the positive travel side (forward, right, clockwise, up) relative to the";
CM_ SG_ 2365402622 Jystck5ThtAxsCntrClckwsNgtvPsStt "Reports when the current joystick position is on the negative travel side (back, left, counterclockwise, down) relative to the";
CM_ SG_ 2365402622 Jystck5ThtaAxisNeutralPosStatus "Reports when the current joystick position is in the neutral position for that axis of travel.";
CM_ SG_ 2365402622 Joystick5GripYAxisPos "The position of the joystick grip in the relative motion of travel from the neutral position.";
CM_ SG_ 2365402622 Jystck5GrpYAxsLvrFrwrdPstvPsStts "Reports when the current joystick grip position is on the positive travel side (forward, right, clockwise, up) relative to the";
CM_ SG_ 2365402622 Jystck5GrpYAxsLvrBckNgtvPsSttus "Reports when the current joystick grip position is on the negative travel side (back, left, counterclockwise, down) relative";
CM_ SG_ 2365402622 Jystck5GrpYAxisNeutralPosStatus "Reports when the current joystick grip position is in the neutral position for that axis of travel.";
CM_ SG_ 2365402622 Joystick5GripXAxisPos "The position of the joystick grip in the relative motion of travel from the neutral position.";
CM_ SG_ 2365402622 Jystck5GrpXAxsLvrRghtPstvPsStts "Reports when the current joystick grip position is on the positive travel side (forward, right, clockwise, up) relative to the";
CM_ SG_ 2365402622 Jystck5GrpXAxsLvrLftNgtvPsSttus "Reports when the current joystick grip position is on the negative travel side (back, left, counterclockwise, down) relative";
CM_ SG_ 2365402622 Jystck5GrpXAxisNeutralPosStatus "Reports when the current joystick grip position is in the neutral position for that axis of travel.";
CM_ BO_ 2365403134 "Extended Joystick Message 4";
CM_ SG_ 2365403134 Jystck4GripXAxisDetentPosStatus "Reports when the current joystick grip position is in the detent position for that axis of travel.";
CM_ SG_ 2365403134 Jystck4GripYAxisDetentPosStatus "Reports when the current joystick grip position is in the detent position for that axis of travel.";
CM_ SG_ 2365403134 Jystck4ThetaAxisDetentPosStatus "Reports when the current joystick position is in the detent position for that axis of travel.";
CM_ SG_ 2365403134 Joystick4ThetaAxisPos "The position of the joystick in the relative motion of travel from the neutral position.";
CM_ SG_ 2365403134 Jystck4ThtAxsClckwsPstvPsStatus "Reports when the current joystick position is on the positive travel side (forward, right, clockwise, up) relative to the";
CM_ SG_ 2365403134 Jystck4ThtAxsCntrClckwsNgtvPsStt "Reports when the current joystick position is on the negative travel side (back, left, counterclockwise, down) relative to the";
CM_ SG_ 2365403134 Jystck4ThtaAxisNeutralPosStatus "Reports when the current joystick position is in the neutral position for that axis of travel.";
CM_ SG_ 2365403134 Joystick4GripYAxisPos "The position of the joystick grip in the relative motion of travel from the neutral position.";
CM_ SG_ 2365403134 Jystck4GrpYAxsLvrFrwrdPstvPsStts "Reports when the current joystick grip position is on the positive travel side (forward, right, clockwise, up) relative to the";
CM_ SG_ 2365403134 Jystck4GrpYAxsLvrBckNgtvPsSttus "Reports when the current joystick grip position is on the negative travel side (back, left, counterclockwise, down) relative";
CM_ SG_ 2365403134 Jystck4GrpYAxisNeutralPosStatus "Reports when the current joystick grip position is in the neutral position for that axis of travel.";
CM_ SG_ 2365403134 Joystick4GripXAxisPos "The position of the joystick grip in the relative motion of travel from the neutral position.";
CM_ SG_ 2365403134 Jystck4GrpXAxsLvrRghtPstvPsStts "Reports when the current joystick grip position is on the positive travel side (forward, right, clockwise, up) relative to the";
CM_ SG_ 2365403134 Jystck4GrpXAxsLvrLftNgtvPsSttus "Reports when the current joystick grip position is on the negative travel side (back, left, counterclockwise, down) relative";
CM_ SG_ 2365403134 Jystck4GrpXAxisNeutralPosStatus "Reports when the current joystick grip position is in the neutral position for that axis of travel.";
CM_ BO_ 2365400062 "Extended Joystick Message 10";
CM_ SG_ 2365400062 Jystck10GrpXAxisDetentPosStatus "Reports when the current joystick grip position is in the detent position for that axis of travel.";
CM_ SG_ 2365400062 Jystck10GrpYAxisDetentPosStatus "Reports when the current joystick grip position is in the detent position for that axis of travel.";
CM_ SG_ 2365400062 Jystck10ThtaAxisDetentPosStatus "Reports when the current joystick position is in the detent position for that axis of travel.";
CM_ SG_ 2365400062 Joystick10ThetaAxisPos "The position of the joystick in the relative motion of travel from the neutral position.";
CM_ SG_ 2365400062 Jystck10ThtAxsClckwsPstvPsSttus "Reports when the current joystick position is on the positive travel side (forward, right, clockwise, up) relative to the";
CM_ SG_ 2365400062 Jystck10ThtAxsCntrClckwsNgtvPsSt "Reports when the current joystick position is on the negative travel side (back, left, counterclockwise, down) relative to the";
CM_ SG_ 2365400062 Jystck10ThtAxisNeutralPosStatus "Reports when the current joystick position is in the neutral position for that axis of travel.";
CM_ SG_ 2365400062 Joystick10GripYAxisPos "The position of the joystick grip in the relative motion of travel from the neutral position.";
CM_ SG_ 2365400062 Jystck10GrpYAxsLvrFrwrdPstvPsStt "Reports when the current joystick grip position is on the positive travel side (forward, right, clockwise, up) relative to the";
CM_ SG_ 2365400062 Jystck10GrpYAxsLvrBckNgtvPsStts "Reports when the current joystick grip position is on the negative travel side (back, left, counterclockwise, down) relative";
CM_ SG_ 2365400062 Jystck10GrpYAxsNeutralPosStatus "Reports when the current joystick grip position is in the neutral position for that axis of travel.";
CM_ SG_ 2365400062 Joystick10GripXAxisPos "The position of the joystick grip in the relative motion of travel from the neutral position.";
CM_ SG_ 2365400062 Jystck10GrpXAxsLvrRghtPstvPsStts "Reports when the current joystick grip position is on the positive travel side (forward, right, clockwise, up) relative to the";
CM_ SG_ 2365400062 Jystck10GrpXAxsLvrLftNgtvPsStts "Reports when the current joystick grip position is on the negative travel side (back, left, counterclockwise, down) relative";
CM_ SG_ 2365400062 Jystck10GrpXAxsNeutralPosStatus "Reports when the current joystick grip position is in the neutral position for that axis of travel.";
CM_ BO_ 2566713598 "Engine Fuel/lube systems 2";
CM_ SG_ 2566713598 EngFuelFilterIntakeAbsPress "Absolute pressure of fuel at the intake of the fuel filter (suction side) located between the fuel tank and the fuel supply";
CM_ BO_ 2499604478 "Engine Fluid/Pressure 11";
CM_ SG_ 2499604478 EngExhstGsRcrcltn1IntkeAbsPress "EGR intake absolute pressure measured before the EGR 1 valve.";
CM_ BO_ 2499608830 "Engine Fluid/Pressure 10";
CM_ SG_ 2499608830 EngExhstGsRcrcltn2IntkeAbsPress "EGR intake absolute pressure measured before the EGR 2 valve.";
CM_ SG_ 2499608830 EngExhstGsRcrcltn2OtletAbsPress "Absolute Pressure immediately after the EGR2 valve";
CM_ SG_ 2499608830 EngExhstGsRcrcltion2IntakePress "EGR2 intake gauge pressure is measured after EGR2 cooler and before EGR2 valve";
CM_ SG_ 2499608830 EngExhstGsRcrculation2DiffPress "Differential Pressure across the Exhaust Gas Recirculation 2 (EGR2) system.";
CM_ BO_ 2432499198 "Electronic Engine Controller 9";
CM_ SG_ 2432499198 CmdedEngFuelInjectionCtrlPress "Provides the commanded set point value for the engine fuel injection control pressure.";
CM_ SG_ 2432499198 CmdedEngFuelRailPress "Provides the commanded set point value for the engine fuel rail pressure";
CM_ SG_ 2432499198 EngExhstGsRcrculation2Valve2Pos "The position of the second exhaust gas recirculation valve of EGR 2 expressed as a percentage of full travel.";
CM_ SG_ 2432499198 EngExhstGsRcirculation2ValvePos "Position of EGR2 valve expressed as a percentage of full travel.";
CM_ BO_ 2633825022 "Electronic Engine Controller 11";
CM_ SG_ 2633825022 EngExhstGsRcrclation2Valve2Ctrl "Desired percentage of maximum Exhaust Gas Recirculation 2 (EGR2) valve 2 opening.";
CM_ SG_ 2633825022 EngExhstGsRcrculation2ValveCtrl "Desired percentage of maximum Exhaust Gas Recirculation 2 (EGR2) valve opening.";
CM_ BO_ 2633826046 "Electronic Engine Controller 10";
CM_ SG_ 2633826046 EGR2CoolerBypassActuatorPos "EGR2 Cooler Bypass Actuator position, where 0% = Fully Closed (no gas flowing through the bypass), and 100% = Fully";
CM_ SG_ 2633826046 EngExhstGsRcrcltn2ClrEfficiency "Exhaust Gas Recirculation 2 cooler efficiency is an indication of the cooler's ability to reduce the temperature of the";
CM_ SG_ 2633826046 EngExhstGsRcrcltn2ClrIntkGsAbsPr "Exhaust Gas Recirculation 2 gas absolute pressure is measured at EGR2 cooler intake.";
CM_ SG_ 2633826046 EngExhstGsRcrcltn2ClrIntakeTemp "Exhaust Gas Recirculation 2 (EGR2) Temperature measured at EGR2 cooler intake.";
CM_ BO_ 2566711294 "Engine Configuration 3";
CM_ SG_ 2566711294 EngFrctnPrcntTorqueAtIdlePoint7 "The static portion of the friction torque at speed point 7 (SPN 533) of the engine torque map in the engine configuration";
CM_ SG_ 2566711294 EngFrctnPrcntTorqueAtIdlePoint6 "For engine configuration map modes 1 and 2, this is the static portion of the friction torque at speed point 6 (SPN 532) of";
CM_ SG_ 2566711294 EngFrctnPrcntTorqueAtIdlePoint5 "The static portion of the friction torque at speed point 5 (SPN 531) of the engine torque map in the engine configuration";
CM_ SG_ 2566711294 EngFrctnPrcntTorqueAtIdlePoint4 "The static portion of the friction torque at speed point 4 (SPN 530) of the engine torque map in the engine configuration";
CM_ SG_ 2566711294 EngFrctnPrcntTorqueAtIdlePoint3 "The static portion of the friction torque at speed point 3 (SPN 529) of the engine torque map in the engine configuration";
CM_ SG_ 2566711294 EngFrctnPrcntTorqueAtIdlePoint2 "The static portion of the friction torque at speed point 2 (SPN 528) of the engine torque map in the engine configuration";
CM_ SG_ 2566711294 EngFrctnPrcntTorqueAtIdlePoint1 "The static portion of the friction torque at speed point 1 (SPN 188) of the engine torque map in the engine configuration";
CM_ BO_ 2566749438 "Diesel Particulate Filter Control 1";
CM_ SG_ 2566749438 DslPrtcltFltrActvRgnrtnFrcdStts "Indicates the forced execution status of diesel particulate filter regeneration.";
CM_ SG_ 2566749438 ExhaustSystemHighTempLampCmd "Command to control the exhaust system high temperature lamp.";
CM_ SG_ 2566749438 DslPrtcltFltrAtmtcActvRgnrtnIntt "Indicates the configuration of diesel particulate filter active regeneration automatic initiation.";
CM_ SG_ 2566749438 DslPrtcltFltrActvRgnrtnInhbtdDTV "Speed";
CM_ SG_ 2566749438 DslPrtcltFltrActvRgnrtnInhbtdDTE "Indicates the state of diesel particulate filter active regeneration inhibition due to the engine not being warmed up.";
CM_ SG_ 2566749438 DslPrtcltFltrActvRgnrtnInhbtdDTP "Indicates the state of diesel particulate filter active regeneration inhibition due to a permanent system lockout.";
CM_ SG_ 2566749438 DslPrtcltFltrActvRgnrtnInhbtdDTT "Indicates the state of diesel particulate filter active regeneration inhibition due to a temporary system lockout.";
CM_ SG_ 2566749438 DslPrtcltFltrActvRgnrtnInhbtdDTS "Indicates the state of diesel particulate filter active regeneration inhibition due to a system timeout.";
CM_ SG_ 2566749438 DslPrtcltFltrActvRgnrtnInhb_0000 "Indicates the state of diesel particulate filter active regeneration inhibition due to a system fault being active.";
CM_ SG_ 2566749438 DslPrtcltFltrActvRgnrtnInhbtdDTL "Indicates the state of diesel particulate filter active regeneration inhibition due to the exhaust gas temperature being too";
CM_ SG_ 2566749438 DslPrtcltFltrActvRgnrtnInhb_0001 "Indicates the state of diesel particulate filter active regeneration inhibition due to the parking brake being not set.";
CM_ SG_ 2566749438 DslPrtcltFltrActvRgnrtnInhb_0002 "Speed";
CM_ SG_ 2566749438 DslPrtcltFltrActvRgnrtnInhbtdDTO "Indicates the state of diesel particulate filter active regeneration inhibition due to the transmission being out of neutral.";
CM_ SG_ 2566749438 DslPrtcltFltrActvRgnrtnInhbtdDTA "Indicates the state of diesel particulate filter active regeneration inhibition due to the accelerator pedal being off idle.";
CM_ SG_ 2566749438 DslPrtcltFltrActvRgnrtnInhb_0003 "Indicates the state of diesel particulate filter active regeneration inhibition due to the PTO being active.";
CM_ SG_ 2566749438 DslPrtcltFltrActvRgnrtnInhb_0004 "Indicates the state of diesel particulate filter active regeneration inhibition due to the service brake being active.";
CM_ SG_ 2566749438 DslPrtcltFltrActvRgnrtnInhbtdDTC "Indicates the state of diesel particulate filter active regeneration inhibition due to the clutch being disengaged.";
CM_ SG_ 2566749438 DslPrtcltFltrActvRgnrtnInhbtdDTI "Indicates the state of diesel particulate filter active regeneration inhibition due to the Diesel Particulate Filter Regeneration";
CM_ SG_ 2566749438 DslPrtcltFltrActvRgnrtnInhbtdStt "Indicates the state of diesel particulate filter active regeneration inhibition.";
CM_ SG_ 2566749438 DieselParticulateFilterStatus "Indicates the state of the diesel particulate filter regeneration need and urgency.";
CM_ SG_ 2566749438 DslPrtcltFltrActvRgnrtionStatus "Indicates the state of diesel particulate filter active regeneration.";
CM_ SG_ 2566749438 DslPrtcltFltrPssvRgnrtionStatus "Indicates the state of diesel particulate filter passive regeneration.";
CM_ SG_ 2566749438 DieselParticulateFilterLampCmd "Command to control the diesel particulate filter lamp.";
CM_ BO_ 2566715646 "Diesel Particulate Filter 2 Soot 2";
CM_ SG_ 2566715646 DslPrtclateFilter2SootSignalMin "Minimum output signal level of the current soot measurement from diesel particulate filter 2 soot sensor.";
CM_ SG_ 2566715646 DslPrtclateFilter2SootSignalMax "Maximum output signal level of the current soot measurement from diesel particulate filter 2 soot sensor.";
CM_ SG_ 2566715646 DslPrtcltFltr2StSgnlStndrdDvton "Standard deviation of the soot measurement from diesel particulate filter 2 soot sensor.";
CM_ BO_ 2566724606 "Diesel Particulate Filter 2 Soot";
CM_ SG_ 2566724606 DslPrtcltFltr2StSnsrPrlmnaryFMI "Used to identify the applicable J1939-73 FMI detected in the soot sensor signal by the manufacturer's sensor control";
CM_ SG_ 2566724606 DslPrtcltFlter2MedianSootSignal "Median output signal level from diesel particulate filter 2 soot sensor.";
CM_ SG_ 2566724606 DslPrtclteFilter2MeanSootSignal "Mean output signal level from diesel particulate filter 2 soot sensor.";
CM_ SG_ 2566724606 DslPrticulateFilter2SootDensity "Soot density in diesel particulate filter 2.";
CM_ SG_ 2566724606 DeselParticulateFilter2SootMass "Soot mass in diesel particulate filter 2.";
CM_ BO_ 2566715902 "Diesel Particulate Filter 1 Soot 2";
CM_ SG_ 2566715902 DslPrtclateFilter1SootSignalMin "Minimum output signal level of the current soot measurement from diesel particulate filter 1 soot sensor.";
CM_ SG_ 2566715902 DslPrtclateFilter1SootSignalMax "Maximum output signal level of the current soot measurement from diesel particulate filter 1 soot sensor.";
CM_ SG_ 2566715902 DslPrtcltFltr1StSgnlStndrdDvton "Standard deviation of the soot measurement from diesel particulate filter 1 soot sensor.";
CM_ BO_ 2566724862 "Diesel Particulate Filter 1 Soot";
CM_ SG_ 2566724862 DslPrtcltFltr1StSnsrPrlmnaryFMI "Used to identify the applicable J1939-73 FMI detected in the soot sensor signal by the manufacturer's sensor control";
CM_ SG_ 2566724862 DslPrtcltFlter1MedianSootSignal "Median output signal level from diesel particulate filter 1 soot sensor.";
CM_ SG_ 2566724862 DslPrtclteFilter1MeanSootSignal "Mean output signal level from diesel particulate filter 1 soot sensor.";
CM_ SG_ 2566724862 DslPrticulateFilter1SootDensity "Soot density in diesel particulate filter 1.";
CM_ SG_ 2566724862 DeselParticulateFilter1SootMass "Soot mass in diesel particulate filter 1.";
CM_ BO_ 2566718718 "Direct Lamp Control Data 2";
CM_ SG_ 2566718718 VehicleBatteryChargingLampData "This parameter provides measured data from the Vehicle Battery Charging Lamp.";
CM_ SG_ 2566718718 VhicleHVACRecirculationLampData "This parameter provides measured data from the Vehicle HVAC Recirculation Lamp.";
CM_ SG_ 2566718718 VehicleAirPressLowLampData "This parameter provides measured data from the Vehicle Air Pressure Low Lamp.";
CM_ SG_ 2566718718 VehicleFuelLevelLowLampData "This parameter provides measured data from theVehicle Fuel Level Low Lamp.";
CM_ SG_ 2566718718 VhicleBatteryVoltageLowLampData "This parameter provides measured data from the Vehicle Battery Voltage Low Lamp.";
CM_ BO_ 2566718974 "Direct Lamp Control Data 1";
CM_ SG_ 2566718974 EngWaitToStartLampData "This parameter provides measured data from the Engine Wait To Start Lamp.";
CM_ SG_ 2566718974 EngFuelFilterRestrictedLampData "Command signal directly controlling the Vehicle Fuel Filter Restricted Lamp.";
CM_ SG_ 2566718974 EngAirFilterRestrictionLampData "This parameter provides measured data from the Engine Air Filter Restriction Lamp.";
CM_ SG_ 2566718974 EngIdleManagementActiveLampData "This parameter provides measured data from the Engine Idle Management Active Lamp.";
CM_ SG_ 2566718974 EngCoolantLevelLowLampData "This parameter provides measured data from the Engine Coolant Level Low Lamp.";
CM_ SG_ 2566718974 EngCoolantTempHighLampData "This parameter provides measured data from the Engine Coolant Temperature High Lamp.";
CM_ SG_ 2566718974 EngOilPressLowLampData "This parameter provides measured data from the Engine Oil Pressure Low Lamp.";
CM_ SG_ 2566718974 CmprssnBrkEnblSwtchIndctrLmpDta "This parameter provides measured data from the Compression Brake Enable Switch Indicator Lamp.";
CM_ SG_ 2566718974 EngBrakeActiveLampData "This parameter provides measured data from the Engine Brake Active Lamp.";
CM_ SG_ 2566718974 OBDMalfunctionIndicatorLampData "This parameter provides measured data from the OBD Malfunction Indicator Lamp.";
CM_ SG_ 2566718974 EngRedStopLampData "This parameter provides measured data from the Engine Red Stop Lamp.";
CM_ SG_ 2566718974 EngAmberWarningLampData "This parameter provides measured data from the Engine Amber Warning Lamp.";
CM_ SG_ 2566718974 EngProtectLampData "This parameter provides measured data from the Engine Protect Lamp.";
CM_ BO_ 2566719230 "Direct Lamp Control Command 2";
CM_ SG_ 2566719230 VehicleBatteryChargingLampCmd "Command signal directly controlling the Vehicle Battery Charging Lamp.";
CM_ SG_ 2566719230 VehicleHVACRecirculationLampCmd "Command signal directly controlling the Vehicle HVAC Recirculation Lamp.";
CM_ SG_ 2566719230 VehicleAirPressLowLampCmd "Command signal directly controlling the Vehicle Air Pressure Low Lamp.";
CM_ SG_ 2566719230 VehicleFuelLevelLowLampCmd "Command signal directly controlling the Vehicle Fuel Level Low Lamp.";
CM_ SG_ 2566719230 VehicleBatteryVoltageLowLampCmd "Command signal directly controlling the Vehicle Battery Voltage Low Lamp.";
CM_ BO_ 2560818942 "DM32 provides the DTCs and associated timers";
CM_ SG_ 2560818942 DTCTimeUntilDerate "This timer provides the number of hours the malfunction has until the OBD required derate will occur";
CM_ SG_ 2560818942 DTCTotalPreviouslyActiveTime "This timer provides the number of hours the NOx malfunction has been confirmed and previously active";
CM_ SG_ 2560818942 DTCTotalActiveTime "This timer provides the total number of hours the DTC has been confirmed and active";
CM_ SG_ 2560818942 FailureModeIdentifier1 "The FMI defines the type of failure detected in the subsystem identified by an SPN.";
CM_ SG_ 2560818942 SPN1High "SPN #1 (Conversion Version 4)";
CM_ SG_ 2560818942 SPN1 "SPN #1 (Conversion Version 4)";
CM_ BO_ 2561212158 "Text Display";
CM_ SG_ 2561212158 TextDisplayInstructions "This parameter describes the status for the display how to show the information.";
CM_ BO_ 2566746366 "Door ramp control";
CM_ SG_ 2566746366 RetractStatusOfRamp5 "Retract status of ramp at doorway 5, counting from front to back on the vehicle.";
CM_ SG_ 2566746366 RetractStatusOfRamp4 "Retract status of ramp at doorway 4, counting from front to back on the vehicle.";
CM_ SG_ 2566746366 MovementStatusOfRamp5 "Movement status of ramp at doorway 5, counting from front to back on the vehicle.";
CM_ SG_ 2566746366 MovementStatusOfRamp4 "Movement status of ramp at doorway 4, counting from front to back on the vehicle.";
CM_ SG_ 2566746366 EnableStatusOfRamp5 "Enable status of ramp at doorway 5, counting from front to back on the vehicle.";
CM_ SG_ 2566746366 EnableStatusOfRamp4 "Enable status of ramp at doorway 4, counting from front to back on the vehicle.";
CM_ SG_ 2566746366 MovementStatusOfRamp3 "Movement status of ramp at doorway 3, counting from front to back on the vehicle.";
CM_ SG_ 2566746366 EnableStatusOfRamp3 "Enable status of ramp at doorway 3, counting from front to back on the vehicle.";
CM_ SG_ 2566746366 RetractStatusOfRamp3 "Retract status of ramp at doorway 3, counting from front to back on the vehicle.";
CM_ SG_ 2566746366 MovementStatusOfRamp2 "Movement status of ramp at doorway 2, counting from front to back on the vehicle.";
CM_ SG_ 2566746366 EnableStatusOfRamp2 "Enable status of ramp at doorway 2, counting from front to back on the vehicle.";
CM_ SG_ 2566746366 RetractStatusOfRamp2 "Retract status of ramp at doorway 2, counting from front to back on the vehicle.";
CM_ SG_ 2566746366 MovementStatusOfRamp1 "Movement status of ramp at doorway 1, counting from front to back on the vehicle.";
CM_ SG_ 2566746366 EnableStatusOfRamp1 "Enable status of ramp at doorway 1, counting from front to back on the vehicle.";
CM_ SG_ 2566746366 RetractStatusOfRamp1 "Retract status of ramp at doorway 1, counting from front to back on the vehicle.";
CM_ BO_ 2566750206 "Engine Configuration 2";
CM_ SG_ 2566750206 MaxCrankAttemptsPerStartAttempt "The number of cranking cycles that will be performed before ending the start attempt.";
CM_ BO_ 2566755582 "Electronic Engine Controller 7";
CM_ SG_ 2566755582 EngExhstGsRcrculation1Valve2Pos "The position of the second exhaust gas recirculation valve expressed as a percentage of full travel.";
CM_ SG_ 2566755582 EngExhstGsRcirculation1ValvePos "The position of the exhaust gas recirculation valve expressed as a percentage of full travel.";
CM_ SG_ 2566755582 EngCrnkcsBrthrOilSeparatorSpeed "The speed of a rotating (centrifugal) crankcase oil separator.";
CM_ SG_ 2566755582 CmdedEngIntakeManifoldPress "Provides the commanded set point value for the engine intake manifold pressure.";
CM_ BO_ 2566746110 "Electronic Engine Controller 8";
CM_ SG_ 2566746110 EngExhstGsRcrcltn1ClrIntkGsAbsPr "Exhaust Gas Recirculation gas absolute pressure is measured at the EGR cooler intake.";
CM_ SG_ 2566746110 EngExhstGsRcrcltn1ClrIntakeTemp "Exhaust Gas Recirculation (EGR) Temperature measured at the EGR cooler intake.";
CM_ SG_ 2566746110 EngExhstGsRcrcltn1ClrEfficiency "Exhaust Gas Recirculation cooler efficiency is an indication of the cooler's ability to reduce the temperature of the exhaust";
CM_ SG_ 2566746110 EngExhstGsRcrclation1Valve2Ctrl "Desired percentage of maximum Exhaust Gas Recirculation (EGR) valve opening for valve 2.";
CM_ BO_ 2566752510 "Engine Fluid Level/Pressure 5";
CM_ SG_ 2566752510 EngIntkVlvActtonOilPressForCyl4 "The gage pressure of the oil in the hydraulic accumulator that powers the engine intake valve for cylinder #4.";
CM_ SG_ 2566752510 EngIntkVlvActtonOilPressForCyl3 "The gage pressure of the oil in the hydraulic accumulator that powers the engine intake valve for cylinder #3.";
CM_ SG_ 2566752510 EngIntkVlvActtonOilPressForCyl2 "The gage pressure of the oil in the hydraulic accumulator that powers the engine intake valve for cylinder #2.";
CM_ SG_ 2566752510 EngIntkVlvActtonOilPressForCyl1 "The gage pressure of the oil in the hydraulic accumulator that powers the engine intake valve for cylinder #1.";
CM_ BO_ 2566752254 "Engine Fluid Level/Pressure 6";
CM_ SG_ 2566752254 EngIntkVlvActtonOilPressForCyl8 "The gage pressure of the oil in the hydraulic accumulator that powers the engine intake valve for cylinder #8.";
CM_ SG_ 2566752254 EngIntkVlvActtonOilPressForCyl7 "The gage pressure of the oil in the hydraulic accumulator that powers the engine intake valve for cylinder #7.";
CM_ SG_ 2566752254 EngIntkVlvActtonOilPressForCyl6 "The gage pressure of the oil in the hydraulic accumulator that powers the engine intake valve for cylinder #6.";
CM_ SG_ 2566752254 EngIntkVlvActtonOilPressForCyl5 "The gage pressure of the oil in the hydraulic accumulator that powers the engine intake valve for cylinder #5.";
CM_ BO_ 2566751998 "Engine Fluid Level/Pressure 7";
CM_ SG_ 2566751998 EngIntkVlvActtnOilPressForCyl12 "The gage pressure of the oil in the hydraulic accumulator that powers the engine intake valve for cylinder #12.";
CM_ SG_ 2566751998 EngIntkVlvActtnOilPressForCyl11 "The gage pressure of the oil in the hydraulic accumulator that powers the engine intake valve for cylinder #11.";
CM_ SG_ 2566751998 EngIntkVlvActtnOilPressForCyl10 "The gage pressure of the oil in the hydraulic accumulator that powers the engine intake valve for cylinder #10.";
CM_ SG_ 2566751998 EngIntkVlvActtonOilPressForCyl9 "The gage pressure of the oil in the hydraulic accumulator that powers the engine intake valve for cylinder #9.";
CM_ BO_ 2566751742 "Engine Fluid Level/Pressure 8";
CM_ SG_ 2566751742 EngIntkVlvActtnOilPressForCyl16 "The gage pressure of the oil in the hydraulic accumulator that powers the engine intake valve for cylinder #16.";
CM_ SG_ 2566751742 EngIntkVlvActtnOilPressForCyl15 "The gage pressure of the oil in the hydraulic accumulator that powers the engine intake valve for cylinder #15.";
CM_ SG_ 2566751742 EngIntkVlvActtnOilPressForCyl14 "The gage pressure of the oil in the hydraulic accumulator that powers the engine intake valve for cylinder #14.";
CM_ SG_ 2566751742 EngIntkVlvActtnOilPressForCyl13 "The gage pressure of the oil in the hydraulic accumulator that powers the engine intake valve for cylinder #13.";
CM_ BO_ 2566751486 "Engine Fluid Level/Pressure 9";
CM_ SG_ 2566751486 EngIntkVlvActtnOilPressForCyl20 "The gage pressure of the oil in the hydraulic accumulator that powers the engine intake valve for cylinder #20.";
CM_ SG_ 2566751486 EngIntkVlvActtnOilPressForCyl19 "The gage pressure of the oil in the hydraulic accumulator that powers the engine intake valve for cylinder #19.";
CM_ SG_ 2566751486 EngIntkVlvActtnOilPressForCyl18 "The gage pressure of the oil in the hydraulic accumulator that powers the engine intake valve for cylinder #18.";
CM_ SG_ 2566751486 EngIntkVlvActtnOilPressForCyl17 "The gage pressure of the oil in the hydraulic accumulator that powers the engine intake valve for cylinder #17.";
CM_ BO_ 2499641854 "EGR Cooler Bypass";
CM_ SG_ 2499641854 EGR1CoolerBypassActuatorPostion "The parameter gives the % open of the EGR Cooler Bypass Actuator, where 0% = Fully Closed (no gas flowing through";
CM_ BO_ 2566748158 "Engine Spark Voltage 1";
CM_ SG_ 2566748158 EngSparkPlug4 "The measured voltage of the spark event on Cylinder #4";
CM_ SG_ 2566748158 EngSparkPlug3 "The measured voltage of the spark event on Cylinder #3";
CM_ SG_ 2566748158 EngSparkPlug2 "The measured voltage of the spark event on Cylinder #2";
CM_ SG_ 2566748158 EngSparkPlug1 "The measured voltage of the spark event on Cylinder #1";
CM_ BO_ 2566747902 "Engine Spark Voltage 2";
CM_ SG_ 2566747902 EngSparkPlug8 "The measured voltage of the spark event on Cylinder #8";
CM_ SG_ 2566747902 EngSparkPlug7 "The measured voltage of the spark event on Cylinder #7";
CM_ SG_ 2566747902 EngSparkPlug6 "The measured voltage of the spark event on Cylinder #6";
CM_ SG_ 2566747902 EngSparkPlug5 "The measured voltage of the spark event on Cylinder #5";
CM_ BO_ 2566747646 "Engine Spark Voltage 3";
CM_ SG_ 2566747646 EngSparkPlug12 "The measured voltage of the spark event on Cylinder #12";
CM_ SG_ 2566747646 EngSparkPlug11 "The measured voltage of the spark event on Cylinder #11";
CM_ SG_ 2566747646 EngSparkPlug10 "The measured voltage of the spark event on Cylinder #10";
CM_ SG_ 2566747646 EngSparkPlug9 "The measured voltage of the spark event on Cylinder #9";
CM_ BO_ 2566747390 "Engine Spark Voltage 4";
CM_ SG_ 2566747390 EngSparkPlug16 "The measured voltage of the spark event on Cylinder #16";
CM_ SG_ 2566747390 EngSparkPlug15 "The measured voltage of the spark event on Cylinder #15";
CM_ SG_ 2566747390 EngSparkPlug14 "The measured voltage of the spark event on Cylinder #14";
CM_ SG_ 2566747390 EngSparkPlug13 "The measured voltage of the spark event on Cylinder #13";
CM_ BO_ 2566747134 "Engine Spark Voltage 5";
CM_ SG_ 2566747134 EngSparkPlug20 "The measured voltage of the spark event on Cylinder #20";
CM_ SG_ 2566747134 EngSparkPlug19 "The measured voltage of the spark event on Cylinder #19";
CM_ SG_ 2566747134 EngSparkPlug18 "The measured voltage of the spark event on Cylinder #18";
CM_ SG_ 2566747134 EngSparkPlug17 "The measured voltage of the spark event on Cylinder #17";
CM_ BO_ 2566746878 "Engine Spark Voltage 6";
CM_ SG_ 2566746878 EngSparkPlug24 "The measured voltage of the spark event on Cylinder #24";
CM_ SG_ 2566746878 EngSparkPlug23 "The measured voltage of the spark event on Cylinder #23";
CM_ SG_ 2566746878 EngSparkPlug22 "The measured voltage of the spark event on Cylinder #22";
CM_ SG_ 2566746878 EngSparkPlug21 "The measured voltage of the spark event on Cylinder #21";
CM_ BO_ 2561277694 "Forward Lane Image Command";
CM_ SG_ 2561277694 LaneDepartureWarningEnableCmd "Command to enable/disable Lane Departure Indication";
CM_ BO_ 2633861886 "SAE J2012 DTC Display";
CM_ SG_ 2633861886 J2012DTCOccurrenceCount "Number of occurrences of the respective SAE J2012 DTC being conveyed.";
CM_ SG_ 2633861886 J2012DTCStatus "Indicates if the respective SAE J2012 DTC is active or previously active.";
CM_ SG_ 2633861886 NumberOfJ2012DTCs "The number J2012 DTCs being conveyed in PGN 64906.";
CM_ BO_ 2565873150 "Steering Angle Sensor Information";
CM_ SG_ 2565873150 MessageChecksum "The message checksum is used to verify the signal path from the demanding device to the steering controller.";
CM_ SG_ 2565873150 MessageCounter "The message counter is to verify the signal path from the demanding device to the steering controller.";
CM_ SG_ 2565873150 SteerAngleSensorCalibrated "This signal indicates the calibration status of the steering angle sensor.";
CM_ SG_ 2565873150 SteerAngleSensorActiveMode "This signal indicates the operational mode of the steering angle sensor.";
CM_ SG_ 2565873150 SteerWheelAngleRange "The signal indicates the range of the steering wheel angle the sensor element is capable to measure.";
CM_ SG_ 2565873150 SteerWheelAngleRangeCounterType "The signal indicates whether the steering wheel angle sensor is capable of absolute measuring of the number of steering";
CM_ SG_ 2565873150 SteerWheelAngleRangeCounter "The signal indicates the number of steering wheel angle range overflows if the operating range of steering wheel is";
CM_ SG_ 2565873150 SteerWheelAngle "The main operator`s steering wheel angle (on the steering column, not the actual wheel angle).";
CM_ BO_ 2566745854 "Aftertreatment 1 SCR Service Information";
CM_ SG_ 2566745854 Aftrtrtmnt1SCRCtlystCnvrsnEffcnc "The SCR catalyst conversion efficiency percentage.";
CM_ SG_ 2566745854 Aftrtrtmnt1SCRCmddCtlystRgntCnsm "This parameter transmits the amount of reagent that the emissions control system has requested to be used, averaged";
CM_ SG_ 2566745854 Aftrtrtmnt1SCRAvrgCtlystRgntCnsm "Measured use of reagent by a Selective Catalytic Reduction system for exhaust emission control, averaged over the";
CM_ SG_ 2566745854 Aftrtrtmnt1DslExhstFldTnkLwLvlIn "The distance traveled while diesel exhaust fluid is low/empty or driver warning/inducement strategy is active.";
CM_ BO_ 2566751230 "Transfer Case Information";
CM_ SG_ 2566751230 TransferCaseStatus "This parameter describes the feedback from the transfer case controller .";
CM_ BO_ 2566755838 "Transmission Fluids 2";
CM_ SG_ 2566755838 TrnsTrqueConverterOilOutletTemp "Temperature of transmission torque converter outlet oil.";
CM_ SG_ 2566755838 TransOverheatIndicator "Signal from transmission indicating that its fluid temperature is above normal acceptable limits, and as a result,";
CM_ SG_ 2566755838 TransOilLifeRemaining "Signal which indicates the actual oil life remaining in percent.";
CM_ SG_ 2566755838 TransOilLevelSwitch "This switch indicates whether transmission oil level is full or empty.";
CM_ SG_ 2566755838 TransOilFilterRestrictionSwitch "This switch indicates whether the transmission oil filter is clogged.";
CM_ BO_ 2566752766 "Vehicle Direction/Speed 2";
CM_ SG_ 2566752766 VehicleRoll "This parameter indicates the roll in degrees from level.";
CM_ BO_ 2633938942 "Engine Speed/Load Factor Information";
CM_ SG_ 2633938942 TotalEngCruiseTime "Total time that the engine has operated in the cruise hold state, excluding time in accelerator override, over the life of the engine.";
CM_ SG_ 2633938942 TotalDriveAverageLoadFactor "Average engine load factor while engine speed is greater than zero, vehicle speed is greater than or equal to 2 km/h, and";
CM_ SG_ 2633938942 TripDriveAverageLoadFactor "Average engine load factor while engine speed is greater than zero, vehicle speed is greater than or equal to 2 km/h, and";
CM_ SG_ 2633938942 TripAverageEngSpeed "Average speed of the engine since the last trip reset.";
CM_ SG_ 2633938942 TripMaxEngSpeed "Maximum engine speed achieved since the last trip reset.";
CM_ BO_ 2566799614 "Lighting Data";
CM_ SG_ 2566799614 ImplementRearWorkLight "This parameter provides measured data from the implement rear work lamps.";
CM_ SG_ 2566799614 ImplementLeftForwardWorkLight "This parameter provides measured data from the forward facing work lights toward the left end of the implement.";
CM_ SG_ 2566799614 ImplementRightForwardWorkLight "This parameter provides measured data from the forward facing work lights toward the right end of the implement.";
CM_ SG_ 2566799614 ImplementLeftFacingWorkLight "This parameter provides measured data from the work lights mounted on an implement to illuminate beyond left end of";
CM_ SG_ 2566799614 ImplementRightFacingWorkLight "This parameter provides measured data from the work lights mounted on an implement to illuminate beyond right end of";
CM_ SG_ 2566799614 ImplementOEMOption1Light "This parameter provides measured data from the implement OEM option 1 light.";
CM_ SG_ 2566799614 ImplementOEMOption2Light "This parameter provides measured data from the implement OEM option 2 light.";
CM_ SG_ 2566799614 TrctrFrontHighMountedWorkLights "This parameter provides measured data from the tractor front high mounted work lights.";
CM_ SG_ 2566799614 TrctorFrontLowMountedWorkLights "This parameter provides measured data from the tractor front low mounted work lights.";
CM_ SG_ 2566799614 TrctorSideHighMountedWorkLights "This parameter provides measured data from the tractor side high mounted work lights.";
CM_ SG_ 2566799614 TractorSideLowMountedWorkLights "This parameter provides measured data from the tractor side low mounted work lights.";
CM_ SG_ 2566799614 TrctorRearHighMountedWorkLights "This parameter provides measured data from the tractor rear high mounted work lights.";
CM_ SG_ 2566799614 TractorRearLowMountedWorkLights "This parameter provides measured data from the tractor rear low mounted work lights.";
CM_ SG_ 2566799614 TrctrUndersideMountedWorkLights "This parameter provides measured data from the tractor underside mounted work lights.";
CM_ SG_ 2566799614 RearFogLights "This parameter provides measured data from the tractor and/or implement rear fog lights.";
CM_ SG_ 2566799614 TractorMarkerLight "This parameter provides measured data from the tractor and attached implement marker lights, including front position";
CM_ SG_ 2566799614 ImplementMarkerLight "This parameter provides measured data from an attached implement marker lights, including front position lights, rear tail";
CM_ SG_ 2566799614 TractorClearanceLight "This parameter provides measured data from the tractor high mounted clearance and center ID lights.";
CM_ SG_ 2566799614 ImplementClearanceLight "This parameter provides measured data from an attached implement high mounted clearance lights.";
CM_ SG_ 2566799614 LeftStopLight "This parameter provides measured data from the tractor and attached implement left stop lights.";
CM_ SG_ 2566799614 RightStopLight "This parameter provides measured data from the tractor and attached implement right stop lights.";
CM_ SG_ 2566799614 CenterStopLight "This parameter provides measured data from the tractor and attached implement center stop lights.";
CM_ SG_ 2566799614 BackUpLightAndAlarmHorn "This parameter provides measured data from the back up lights and/ or associated alarm.";
CM_ SG_ 2566799614 LeftTurnSignalLights "This parameter provides measured data from the tractor and attached implement left turn signal lights.";
CM_ SG_ 2566799614 RightTurnSignalLights "This parameter provides measured data from the tractor and attached implement right turn signal lights.";
CM_ SG_ 2566799614 RotatingBeaconLight "This parameter provides measured data from the beacon light on tractor or attached implements.";
CM_ SG_ 2566799614 TractorFrontFogLights "This parameter provides measured data from the tractor front fog lights.";
CM_ SG_ 2566799614 HighBeamHeadLightData "This parameter provides measured data from the tractor high beam head light lamps.";
CM_ SG_ 2566799614 LowBeamHeadLightData "This parameter provides measured data from the tractor low beam head light lamps.";
CM_ SG_ 2566799614 AltBeamHeadLightData "This parameter provides measured data from the tractor alternate beam head light lamps.";
CM_ SG_ 2566799614 RunningLight "This parameter provides measured data from the vehicle's running lights.";
CM_ BO_ 2365473278 "Lighting Command";
CM_ SG_ 2365473278 ImplementRearWorkLightCmd "Command to activate or de-activate implement rear work lights.";
CM_ SG_ 2365473278 ImplmentLeftForwardWorkLightCmd "Command to activate or de-activate the forward facing work lights toward the left end of the implement.";
CM_ SG_ 2365473278 ImplmntRightForwardWorkLightCmd "Command to activate or de-activate the forward facing work lights toward the right end of the implement.";
CM_ SG_ 2365473278 LightingDataRqCmd "Command to provide a response of the light state";
CM_ SG_ 2365473278 ImplementLeftFacingWorkLightCmd "Command to activate or de-activate work lights mounted on an implement to illuminate beyond left end of the implement.";
CM_ SG_ 2365473278 ImplmentRightFacingWorkLightCmd "Command to activate or de-activate work lights mounted on an implement to illuminate beyond right end of the implement.";
CM_ SG_ 2365473278 ImplementOEMOption1LightCmd "Command to activate or de-activate an implement OEM option 1 light.";
CM_ SG_ 2365473278 ImplementOEMOption2LightCmd "Command to activate or de-activate an implement OEM option 2 light.";
CM_ SG_ 2365473278 TrctrFrntHghMuntedWorkLightsCmd "Command to activate or de-activate the tractor front high mounted work lights.";
CM_ SG_ 2365473278 TrctrFrntLwMountedWorkLightsCmd "Command to activate or de-activate the tractor front low mounted work lights.";
CM_ SG_ 2365473278 TrctrSdHighMountedWorkLightsCmd "Command to activate or de-activate the tractor side high mounted work lights.";
CM_ SG_ 2365473278 TrctrSdeLowMountedWorkLightsCmd "Command to activate or de-activate the tractor side low mounted work lights.";
CM_ SG_ 2365473278 TrctrRrHighMountedWorkLightsCmd "Command to activate or de-activate the tractor rear high mounted work lights.";
CM_ SG_ 2365473278 TrctrRarLowMountedWorkLightsCmd "Command to activate or de-activate the tractor rear low mounted work lights.";
CM_ SG_ 2365473278 TrctrUndrsdMountedWorkLightsCmd "Command to activate or de-activate the tractor underside mounted work lights.";
CM_ SG_ 2365473278 RearFogLightCmd "Command to activate or de-activate tractor or implement rear fog lights.";
CM_ SG_ 2365473278 TractorMarkerLightCmd "Command to activate or de-activate tractor and implement front position lights, rear red tail lights, side amber running";
CM_ SG_ 2365473278 ImplementMarkerLightCmd "Command to activate or de-activate implement front position lights, rear red tail lights, side amber running lights, license";
CM_ SG_ 2365473278 TractorClearanceLightCmd "Command to activate or de-activate the tractor high mounted clearance and center ID lights";
CM_ SG_ 2365473278 ImplementClearanceLightCmd "Command to activate or de-activate the implement high mounted clearance and lights.";
CM_ SG_ 2365473278 LeftStopLightCmd "Command to activate or de-activate the tractor and implement left stop lights";
CM_ SG_ 2365473278 RightStopLightCmd "Command to activate or de-activate the tractor and implement right stop light";
CM_ SG_ 2365473278 CenterStopLightCmd "Command to activate or de-activate the tractor and implement center stop light";
CM_ SG_ 2365473278 BackUpLightAndAlarmHornCmd "Command to activate or de-activate the back up lights and/ or associated alarm if required";
CM_ SG_ 2365473278 LeftTurnSignalLightsCmd "Command to activate or de-activate left turn signal lights on the tractor and all connected implements";
CM_ SG_ 2365473278 RightTurnSignalLightsCmd "Command to activate or de-activate right turn signal lights on the tractor and all connected implements";
CM_ SG_ 2365473278 RotatingBeaconLightCmd "Command to activate or de-activate slow moving vehicle indicator lights on tractor and/or implements.";
CM_ SG_ 2365473278 TractorFrontFogLightsCmd "Command to activate or de-activate tractor front fog lights.";
CM_ SG_ 2365473278 HighBeamHeadLightCmd "Command to activate or de-activate the tractor high beam head light lamps.";
CM_ SG_ 2365473278 LowBeamHeadLightCmd "Command to activate or de-activate the tractor low beam head light lamps.";
CM_ SG_ 2365473278 AltBeamHeadLightCmd "Command to activate or de-activate the tractor alternate head lights (only low beam is available on alternate head lights).";
CM_ SG_ 2365473278 RunningLightCmd "Command to activate or de-activate the tractor or powered vehicle running lights.";
CM_ BO_ 2365485822 "Laser Leveling System Blade Control";
CM_ SG_ 2365485822 BladeCtrlMode "Allows the user to select the type of blade control for the land leveling system.";
CM_ SG_ 2365485822 BladeDurationAndDirection "Used to indicate the duration and direction that the land leveling system blade moves.";
CM_ SG_ 2365485822 LandLevelingSystemEnableStatus "Communicate the enable/disable status of the Land Leveling System.";
CM_ SG_ 2365485822 BladeCtrlModeRight "Indicate if the land leveling system's automatic control is active or inactive for the elevation sensor on the right side of the";
CM_ SG_ 2365485822 BladeCtrlModeLeft "Indicate if the land leveling system's automatic control is active or inactive for the elevation sensor on the left side of the";
CM_ BO_ 2633926654 "Ignition Timing 6";
CM_ SG_ 2633926654 EngActualIgntTiming "The actual ignition timing at the current engine conditions.";
CM_ SG_ 2633926654 EngDesiredIgntTiming3 "A programmable timing value specific to the engine's application.";
CM_ SG_ 2633926654 EngDesiredIgntTiming2 "A programmable timing value specific to the engine's application.";
CM_ SG_ 2633926654 EngDesiredIgntTiming1 "A programmable timing value specific to the engine's application.";
CM_ BO_ 2633926398 "Ignition Timing 5";
CM_ SG_ 2633926398 EngCyl20IgntTiming "The ignition timing of the cylinder.";
CM_ SG_ 2633926398 EngCyl19IgntTiming "The ignition timing of the cylinder.";
CM_ SG_ 2633926398 EngCyl18IgntTiming "The ignition timing of the cylinder.";
CM_ SG_ 2633926398 EngCyl17IgntTiming "The ignition timing of the cylinder.";
CM_ BO_ 2633926142 "Ignition Timing 4";
CM_ SG_ 2633926142 EngCyl16IgntTiming "The ignition timing of the cylinder.";
CM_ SG_ 2633926142 EngCyl15IgntTiming "The ignition timing of the cylinder.";
CM_ SG_ 2633926142 EngCyl14IgntTiming "The ignition timing of the cylinder.";
CM_ SG_ 2633926142 EngCyl13IgntTiming "The ignition timing of the cylinder.";
CM_ BO_ 2633925886 "Ignition Timing 3";
CM_ SG_ 2633925886 EngCyl12IgntTiming "The ignition timing of the cylinder.";
CM_ SG_ 2633925886 EngCyl11IgntTiming "The ignition timing of the cylinder.";
CM_ SG_ 2633925886 EngCyl10IgntTiming "The ignition timing of the cylinder.";
CM_ SG_ 2633925886 EngCyl9IgntTiming "The ignition timing of the cylinder.";
CM_ BO_ 2633925630 "Ignition Timing 2";
CM_ SG_ 2633925630 EngCyl8IgntTiming "The ignition timing of the cylinder.";
CM_ SG_ 2633925630 EngCyl7IgntTiming "The ignition timing of the cylinder.";
CM_ SG_ 2633925630 EngCyl6IgntTiming "The ignition timing of the cylinder.";
CM_ SG_ 2633925630 EngCyl5IgntTiming "The ignition timing of the cylinder.";
CM_ BO_ 2633925374 "Ignition Timing 1";
CM_ SG_ 2633925374 EngCyl4IgntTiming "The ignition timing of the cylinder.";
CM_ SG_ 2633925374 EngCyl3IgntTiming "The ignition timing of the cylinder.";
CM_ SG_ 2633925374 EngCyl2IgntTiming "The ignition timing of the cylinder.";
CM_ SG_ 2633925374 EngCyl1IgntTiming "The ignition timing of the cylinder.";
CM_ BO_ 2633927422 "Ignition Transformer Secondary Output 3";
CM_ SG_ 2633927422 EngCyl20IgntTransSecondOutput "This parameter indicates the relative intensity of the secondary output voltage of the ignition transformer.";
CM_ SG_ 2633927422 EngCyl19IgntTransSecondOutput "This parameter indicates the relative intensity of the secondary output voltage of the ignition transformer.";
CM_ SG_ 2633927422 EngCyl18IgntTransSecondOutput "This parameter indicates the relative intensity of the secondary output voltage of the ignition transformer.";
CM_ SG_ 2633927422 EngCyl17IgntTransSecondOutput "This parameter indicates the relative intensity of the secondary output voltage of the ignition transformer.";
CM_ BO_ 2633927166 "Ignition Transformer Secondary Output 2";
CM_ SG_ 2633927166 EngCyl16IgntTransSecondOutput "This parameter indicates the relative intensity of the secondary output voltage of the ignition transformer.";
CM_ SG_ 2633927166 EngCyl15IgntTransSecondOutput "This parameter indicates the relative intensity of the secondary output voltage of the ignition transformer.";
CM_ SG_ 2633927166 EngCyl14IgntTransSecondOutput "This parameter indicates the relative intensity of the secondary output voltage of the ignition transformer.";
CM_ SG_ 2633927166 EngCyl13IgntTransSecondOutput "This parameter indicates the relative intensity of the secondary output voltage of the ignition transformer.";
CM_ SG_ 2633927166 EngCyl12IgntTransSecondOutput "This parameter indicates the relative intensity of the secondary output voltage of the ignition transformer.";
CM_ SG_ 2633927166 EngCyl11IgntTransSecondOutput "This parameter indicates the relative intensity of the secondary output voltage of the ignition transformer.";
CM_ SG_ 2633927166 EngCyl10IgntTransSecondOutput "This parameter indicates the relative intensity of the secondary output voltage of the ignition transformer.";
CM_ SG_ 2633927166 EngCyl9IgntTransSecondOutput "This parameter indicates the relative intensity of the secondary output voltage of the ignition transformer.";
BA_DEF_ SG_ "SigType" ENUM "Default","Range","RangeSigned","ASCII","Discrete","Control","ReferencePGN","DTC","StringDelimiter","StringLength","StringLengthControl";
BA_DEF_ SG_ "GenSigStartValue" INT 0 10000;
BA_DEF_ SG_ "GenSigSendType" ENUM "Default","Range","RangeSigned","ASCII","Discrete","Control","ReferencePGN","DTC","StringDelimiter","StringLength","StringLengthControl","Cyclic","OnWrite","reserved","OnChange","reserved","reserved","reserved","NoSigSendType";
BA_DEF_ SG_ "GenSigILSupport" ENUM "Default","Range","RangeSigned","ASCII","Discrete","Control","ReferencePGN","DTC","StringDelimiter","StringLength","StringLengthControl","Cyclic","OnWrite","reserved","OnChange","reserved","reserved","reserved","NoSigSendType","Yes","No";
BA_DEF_ SG_ "GenSigEVName" STRING ;
BA_DEF_ SG_ "SPN" INT 0 524287;
BA_DEF_ BO_ "GenMsgStartDelayTime" INT 0 100000;
BA_DEF_ BO_ "GenMsgILSupport" ENUM "Default","Range","RangeSigned","ASCII","Discrete","Control","ReferencePGN","DTC","StringDelimiter","StringLength","StringLengthControl","Cyclic","OnWrite","reserved","OnChange","reserved","reserved","reserved","NoSigSendType","Yes","No","Yes","No";
BA_DEF_ BO_ "GenMsgRequestable" INT 0 1;
BA_DEF_ BO_ "GenMsgSendType" ENUM "Default","Range","RangeSigned","ASCII","Discrete","Control","ReferencePGN","DTC","StringDelimiter","StringLength","StringLengthControl","Cyclic","OnWrite","reserved","OnChange","reserved","reserved","reserved","NoSigSendType","Yes","No","Yes","No","cyclic","reserved","cyclicIfActive","reserved","reserved","reserved","reserved","reserved","noMsgSendType";
BA_DEF_ BO_ "VFrameFormat" ENUM "Default","Range","RangeSigned","ASCII","Discrete","Control","ReferencePGN","DTC","StringDelimiter","StringLength","StringLengthControl","Cyclic","OnWrite","reserved","OnChange","reserved","reserved","reserved","NoSigSendType","Yes","No","Yes","No","cyclic","reserved","cyclicIfActive","reserved","reserved","reserved","reserved","reserved","noMsgSendType","StandardCAN","ExtendedCAN","reserved","J1939PG";
BA_DEF_ BO_ "GenMsgCycleTime" INT 0 3.6e+06;
BA_DEF_ BU_ "NmStationAddress" INT 0 255;
BA_DEF_ BU_ "NmJ1939IndustryGroup" INT 0 7;
BA_DEF_ BU_ "NmJ1939System" INT 0 127;
BA_DEF_ BU_ "NmJ1939Function" INT 0 255;
BA_DEF_ BU_ "NmJ1939FunctionInstance" INT 0 7;
BA_DEF_ BU_ "NmJ1939ECUInstance" INT 0 3;
BA_DEF_ SG_ "SystemSignalLongSymbol" STRING ;
BA_DEF_ BO_ "GenMsgBackgroundColor" STRING ;
BA_DEF_ BO_ "GenMsgForegroundColor" STRING ;
BA_DEF_ BO_ "matchingcriteria" INT 0 0;
BA_DEF_ BO_ "filterlabeling" INT 0 0;
BA_DEF_DEF_ "SigType" "Default";
BA_DEF_DEF_ "GenSigStartValue" 0;
BA_DEF_DEF_ "GenSigSendType" "NoSigSendType";
BA_DEF_DEF_ "GenSigILSupport" "Yes";
BA_DEF_DEF_ "GenSigEVName" "Env";
BA_DEF_DEF_ "SPN" 0;
BA_DEF_DEF_ "GenMsgStartDelayTime" 0;
BA_DEF_DEF_ "GenMsgILSupport" "Yes";
BA_DEF_DEF_ "GenMsgRequestable" 1;
BA_DEF_DEF_ "GenMsgSendType" "noMsgSendType";
BA_DEF_DEF_ "VFrameFormat" "J1939PG";
BA_DEF_DEF_ "GenMsgCycleTime" 0;
BA_DEF_DEF_ "NmStationAddress" 254;
BA_DEF_DEF_ "NmJ1939IndustryGroup" 0;
BA_DEF_DEF_ "NmJ1939System" 0;
BA_DEF_DEF_ "NmJ1939Function" 0;
BA_DEF_DEF_ "NmJ1939FunctionInstance" 0;
BA_DEF_DEF_ "NmJ1939ECUInstance" 0;
BA_DEF_DEF_ "SystemSignalLongSymbol" "";
BA_DEF_DEF_ "GenMsgBackgroundColor" "#ffffff";
BA_DEF_DEF_ "GenMsgForegroundColor" "#000000";
BA_DEF_DEF_ "matchingcriteria" 1;
BA_DEF_DEF_ "filterlabeling" 1;
BA_ "NmStationAddress" BU_ Node_2 0;
BA_ "NmStationAddress" BU_ Node_251 0;
BA_ "NmStationAddress" BU_ Node_250 0;
BA_ "NmStationAddress" BU_ Node_249 0;
BA_ "NmStationAddress" BU_ Node_248 0;
BA_ "NmStationAddress" BU_ Node_80 0;
BA_ "NmStationAddress" BU_ Node_79 0;
BA_ "NmStationAddress" BU_ Node_78 0;
BA_ "NmStationAddress" BU_ Node_77 0;
BA_ "NmStationAddress" BU_ Node_76 0;
BA_ "NmStationAddress" BU_ Node_75 0;
BA_ "NmStationAddress" BU_ Node_74 0;
BA_ "NmStationAddress" BU_ Node_73 0;
BA_ "NmStationAddress" BU_ Node_72 0;
BA_ "NmStationAddress" BU_ Node_71 0;
BA_ "NmStationAddress" BU_ Node_70 0;
BA_ "NmStationAddress" BU_ Node_69 0;
BA_ "NmStationAddress" BU_ Node_68 0;
BA_ "NmStationAddress" BU_ Node_67 0;
BA_ "NmStationAddress" BU_ Node_66 0;
BA_ "NmStationAddress" BU_ Node_65 0;
BA_ "NmStationAddress" BU_ Node_64 0;
BA_ "NmStationAddress" BU_ Node_63 0;
BA_ "NmStationAddress" BU_ Node_62 0;
BA_ "NmStationAddress" BU_ Node_61 0;
BA_ "NmStationAddress" BU_ Node_60 0;
BA_ "NmStationAddress" BU_ Node_59 0;
BA_ "NmStationAddress" BU_ Node_58 0;
BA_ "NmStationAddress" BU_ Node_57 0;
BA_ "NmStationAddress" BU_ Node_56 0;
BA_ "NmStationAddress" BU_ Node_55 0;
BA_ "NmStationAddress" BU_ Node_54 0;
BA_ "NmStationAddress" BU_ Node_53 0;
BA_ "NmStationAddress" BU_ Node_52 0;
BA_ "NmStationAddress" BU_ Node_51 0;
BA_ "NmStationAddress" BU_ Node_50 0;
BA_ "NmStationAddress" BU_ Node_49 0;
BA_ "NmStationAddress" BU_ Node_48 0;
BA_ "NmStationAddress" BU_ Node_47 0;
BA_ "NmStationAddress" BU_ Node_46 0;
BA_ "NmStationAddress" BU_ Node_45 0;
BA_ "NmStationAddress" BU_ Node_44 0;
BA_ "NmStationAddress" BU_ Node_43 0;
BA_ "NmStationAddress" BU_ Node_42 0;
BA_ "NmStationAddress" BU_ Node_41 0;
BA_ "NmStationAddress" BU_ Node_40 0;
BA_ "NmStationAddress" BU_ Node_39 0;
BA_ "NmStationAddress" BU_ Node_38 0;
BA_ "NmStationAddress" BU_ Node_37 0;
BA_ "NmStationAddress" BU_ Node_36 0;
BA_ "NmStationAddress" BU_ Node_35 0;
BA_ "NmStationAddress" BU_ Node_34 0;
BA_ "NmStationAddress" BU_ Node_33 0;
BA_ "NmStationAddress" BU_ Node_32 0;
BA_ "NmStationAddress" BU_ Node_31 0;
BA_ "NmStationAddress" BU_ Node_30 0;
BA_ "NmStationAddress" BU_ Node_29 0;
BA_ "NmStationAddress" BU_ Node_28 0;
BA_ "NmStationAddress" BU_ Node_27 0;
BA_ "NmStationAddress" BU_ Node_26 0;
BA_ "NmStationAddress" BU_ Node_25 0;
BA_ "NmStationAddress" BU_ Node_24 0;
BA_ "NmStationAddress" BU_ Node_23 0;
BA_ "NmStationAddress" BU_ Node_22 0;
BA_ "NmStationAddress" BU_ Node_21 0;
BA_ "NmStationAddress" BU_ Node_20 0;
BA_ "NmStationAddress" BU_ Node_19 0;
BA_ "NmStationAddress" BU_ Node_18 0;
BA_ "NmStationAddress" BU_ Node_17 0;
BA_ "NmStationAddress" BU_ Node_16 0;
BA_ "NmStationAddress" BU_ Node_15 0;
BA_ "NmStationAddress" BU_ Node_14 0;
BA_ "NmStationAddress" BU_ Node_13 0;
BA_ "NmStationAddress" BU_ Node_11 0;
BA_ "NmStationAddress" BU_ Node_12 0;
BA_ "NmStationAddress" BU_ Node_10 0;
BA_ "NmStationAddress" BU_ Node_9 0;
BA_ "NmStationAddress" BU_ Node_8 0;
BA_ "NmStationAddress" BU_ Node_7 0;
BA_ "NmStationAddress" BU_ Node_6 0;
BA_ "NmStationAddress" BU_ Node_5 0;
BA_ "NmStationAddress" BU_ Node_4 0;
BA_ "NmStationAddress" BU_ Node_3 0;
BA_ "NmStationAddress" BU_ Node_1 0;
BA_ "NmStationAddress" BU_ Node_0 0;
BA_ "GenMsgCycleTime" BO_ 2297441790 10;
BA_ "GenMsgSendType" BO_ 2297441790 0;
BA_ "VFrameFormat" BO_ 2297441790 3;
BA_ "SystemSignalLongSymbol" SG_ 2297441790 SpprtVrblTrnsRpttnRtFrAcclrtnSns "SpprtVrblTrnsRpttnRtFrAcclrtnSns";
BA_ "VFrameFormat" BO_ 2566712062 3;
BA_ "GenMsgCycleTime" BO_ 2364549630 10;
BA_ "GenMsgSendType" BO_ 2364549630 0;
BA_ "VFrameFormat" BO_ 2364549630 3;
BA_ "VFrameFormat" BO_ 2499614462 3;
BA_ "VFrameFormat" BO_ 2560098046 3;
BA_ "VFrameFormat" BO_ 2560163582 3;
BA_ "GenMsgCycleTime" BO_ 2297441534 50;
BA_ "GenMsgSendType" BO_ 2297441534 0;
BA_ "VFrameFormat" BO_ 2297441534 3;
BA_ "GenMsgCycleTime" BO_ 2566722302 500;
BA_ "GenMsgSendType" BO_ 2566722302 0;
BA_ "VFrameFormat" BO_ 2566722302 3;
BA_ "VFrameFormat" BO_ 2566722558 3;
BA_ "VFrameFormat" BO_ 2560032510 3;
BA_ "GenMsgCycleTime" BO_ 2566717950 500;
BA_ "GenMsgSendType" BO_ 2566717950 0;
BA_ "VFrameFormat" BO_ 2566717950 3;
BA_ "GenMsgCycleTime" BO_ 2499604222 200;
BA_ "GenMsgSendType" BO_ 2499604222 0;
BA_ "VFrameFormat" BO_ 2499604222 3;
BA_ "GenMsgCycleTime" BO_ 2358902526 100;
BA_ "GenMsgSendType" BO_ 2358902526 0;
BA_ "VFrameFormat" BO_ 2358902526 3;
BA_ "GenMsgCycleTime" BO_ 2566711550 500;
BA_ "GenMsgSendType" BO_ 2566711550 0;
BA_ "VFrameFormat" BO_ 2566711550 3;
BA_ "VFrameFormat" BO_ 2633832958 3;
BA_ "GenMsgCycleTime" BO_ 2566719998 1000;
BA_ "GenMsgSendType" BO_ 2566719998 0;
BA_ "VFrameFormat" BO_ 2566719998 3;
BA_ "VFrameFormat" BO_ 2565877502 3;
BA_ "GenMsgCycleTime" BO_ 2566713854 100;
BA_ "GenMsgSendType" BO_ 2566713854 0;
BA_ "VFrameFormat" BO_ 2566713854 3;
BA_ "GenMsgCycleTime" BO_ 2566714366 100;
BA_ "GenMsgSendType" BO_ 2566714366 0;
BA_ "VFrameFormat" BO_ 2566714366 3;
BA_ "SystemSignalLongSymbol" SG_ 2566714366 EngTrbCmprssrBypssActtr2OprtnStt "EngTrbCmprssrBypssActtr2OprtnStt";
BA_ "SystemSignalLongSymbol" SG_ 2566714366 EngTrbCmprssrBypssActtr1OprtnStt "EngTrbCmprssrBypssActtr1OprtnStt";
BA_ "SystemSignalLongSymbol" SG_ 2566714366 EngTrbCmprssrBypssActtr2PrlmnryF "EngTrbCmprssrBypssActtr2PrlmnryF";
BA_ "GenMsgCycleTime" BO_ 2566714110 100;
BA_ "GenMsgSendType" BO_ 2566714110 0;
BA_ "VFrameFormat" BO_ 2566714110 3;
BA_ "GenMsgCycleTime" BO_ 2566717438 1000;
BA_ "GenMsgSendType" BO_ 2566717438 0;
BA_ "VFrameFormat" BO_ 2566717438 3;
BA_ "GenMsgCycleTime" BO_ 2633828606 30000;
BA_ "GenMsgSendType" BO_ 2633828606 0;
BA_ "VFrameFormat" BO_ 2633828606 3;
BA_ "VFrameFormat" BO_ 2499607550 3;
BA_ "SystemSignalLongSymbol" SG_ 2499607550 EngExhstMnfldBnk2FlwBlncVlvActtr "EngExhstMnfldBnk2FlwBlncVlvActtr";
BA_ "SystemSignalLongSymbol" SG_ 2499607550 EngExhstMnfldBnk1FlwBlncVlvActtr "EngExhstMnfldBnk1FlwBlncVlvActtr";
BA_ "VFrameFormat" BO_ 2633825534 3;
BA_ "SystemSignalLongSymbol" SG_ 2633825534 EngExhstMnfldBnk2FlwBlncVlv_0000 "EngExhstMnfldBnk2FlwBlncVlv_0000";
BA_ "SystemSignalLongSymbol" SG_ 2633825534 EngExhstMnfldBnk1FlwBlncVlv_0000 "EngExhstMnfldBnk1FlwBlncVlv_0000";
BA_ "VFrameFormat" BO_ 2365400574 3;
BA_ "SystemSignalLongSymbol" SG_ 2365400574 Jystck9ThtAxsCntrClckwsNgtvPsStt "Jystck9ThtAxsCntrClckwsNgtvPsStt";
BA_ "VFrameFormat" BO_ 2365401086 3;
BA_ "SystemSignalLongSymbol" SG_ 2365401086 Jystck8ThtAxsCntrClckwsNgtvPsStt "Jystck8ThtAxsCntrClckwsNgtvPsStt";
BA_ "VFrameFormat" BO_ 2365401598 3;
BA_ "SystemSignalLongSymbol" SG_ 2365401598 Jystck7ThtAxsCntrClckwsNgtvPsStt "Jystck7ThtAxsCntrClckwsNgtvPsStt";
BA_ "VFrameFormat" BO_ 2365402110 3;
BA_ "SystemSignalLongSymbol" SG_ 2365402110 Jystck6ThtAxsCntrClckwsNgtvPsStt "Jystck6ThtAxsCntrClckwsNgtvPsStt";
BA_ "VFrameFormat" BO_ 2365402622 3;
BA_ "SystemSignalLongSymbol" SG_ 2365402622 Jystck5ThtAxsCntrClckwsNgtvPsStt "Jystck5ThtAxsCntrClckwsNgtvPsStt";
BA_ "VFrameFormat" BO_ 2365403134 3;
BA_ "SystemSignalLongSymbol" SG_ 2365403134 Jystck4ThtAxsCntrClckwsNgtvPsStt "Jystck4ThtAxsCntrClckwsNgtvPsStt";
BA_ "VFrameFormat" BO_ 2365400062 3;
BA_ "SystemSignalLongSymbol" SG_ 2365400062 Jystck10ThtAxsCntrClckwsNgtvPsSt "Jystck10ThtAxsCntrClckwsNgtvPsSt";
BA_ "SystemSignalLongSymbol" SG_ 2365400062 Jystck10GrpYAxsLvrFrwrdPstvPsStt "Jystck10GrpYAxsLvrFrwrdPstvPsStt";
BA_ "GenMsgCycleTime" BO_ 2566713598 500;
BA_ "GenMsgSendType" BO_ 2566713598 0;
BA_ "VFrameFormat" BO_ 2566713598 3;
BA_ "GenMsgCycleTime" BO_ 2499604478 500;
BA_ "GenMsgSendType" BO_ 2499604478 0;
BA_ "VFrameFormat" BO_ 2499604478 3;
BA_ "GenMsgCycleTime" BO_ 2499608830 500;
BA_ "GenMsgSendType" BO_ 2499608830 0;
BA_ "VFrameFormat" BO_ 2499608830 3;
BA_ "GenMsgCycleTime" BO_ 2432499198 100;
BA_ "GenMsgSendType" BO_ 2432499198 0;
BA_ "VFrameFormat" BO_ 2432499198 3;
BA_ "VFrameFormat" BO_ 2633825022 3;
BA_ "VFrameFormat" BO_ 2633826046 3;
BA_ "SystemSignalLongSymbol" SG_ 2633826046 EngExhstGsRcrcltn2ClrIntkGsAbsPr "EngExhstGsRcrcltn2ClrIntkGsAbsPr";
BA_ "VFrameFormat" BO_ 2566711294 3;
BA_ "VFrameFormat" BO_ 2566749438 3;
BA_ "SystemSignalLongSymbol" SG_ 2566749438 DslPrtcltFltrAtmtcActvRgnrtnIntt "DslPrtcltFltrAtmtcActvRgnrtnIntt";
BA_ "SystemSignalLongSymbol" SG_ 2566749438 DslPrtcltFltrActvRgnrtnInhbtdDTV "DslPrtcltFltrActvRgnrtnInhbtdDTV";
BA_ "SystemSignalLongSymbol" SG_ 2566749438 DslPrtcltFltrActvRgnrtnInhbtdDTE "DslPrtcltFltrActvRgnrtnInhbtdDTE";
BA_ "SystemSignalLongSymbol" SG_ 2566749438 DslPrtcltFltrActvRgnrtnInhbtdDTP "DslPrtcltFltrActvRgnrtnInhbtdDTP";
BA_ "SystemSignalLongSymbol" SG_ 2566749438 DslPrtcltFltrActvRgnrtnInhbtdDTT "DslPrtcltFltrActvRgnrtnInhbtdDTT";
BA_ "SystemSignalLongSymbol" SG_ 2566749438 DslPrtcltFltrActvRgnrtnInhbtdDTS "DslPrtcltFltrActvRgnrtnInhbtdDTS";
BA_ "SystemSignalLongSymbol" SG_ 2566749438 DslPrtcltFltrActvRgnrtnInhb_0000 "DslPrtcltFltrActvRgnrtnInhb_0000";
BA_ "SystemSignalLongSymbol" SG_ 2566749438 DslPrtcltFltrActvRgnrtnInhbtdDTL "DslPrtcltFltrActvRgnrtnInhbtdDTL";
BA_ "SystemSignalLongSymbol" SG_ 2566749438 DslPrtcltFltrActvRgnrtnInhb_0001 "DslPrtcltFltrActvRgnrtnInhb_0001";
BA_ "SystemSignalLongSymbol" SG_ 2566749438 DslPrtcltFltrActvRgnrtnInhb_0002 "DslPrtcltFltrActvRgnrtnInhb_0002";
BA_ "SystemSignalLongSymbol" SG_ 2566749438 DslPrtcltFltrActvRgnrtnInhbtdDTO "DslPrtcltFltrActvRgnrtnInhbtdDTO";
BA_ "SystemSignalLongSymbol" SG_ 2566749438 DslPrtcltFltrActvRgnrtnInhbtdDTA "DslPrtcltFltrActvRgnrtnInhbtdDTA";
BA_ "SystemSignalLongSymbol" SG_ 2566749438 DslPrtcltFltrActvRgnrtnInhb_0003 "DslPrtcltFltrActvRgnrtnInhb_0003";
BA_ "SystemSignalLongSymbol" SG_ 2566749438 DslPrtcltFltrActvRgnrtnInhb_0004 "DslPrtcltFltrActvRgnrtnInhb_0004";
BA_ "SystemSignalLongSymbol" SG_ 2566749438 DslPrtcltFltrActvRgnrtnInhbtdDTC "DslPrtcltFltrActvRgnrtnInhbtdDTC";
BA_ "SystemSignalLongSymbol" SG_ 2566749438 DslPrtcltFltrActvRgnrtnInhbtdDTI "DslPrtcltFltrActvRgnrtnInhbtdDTI";
BA_ "SystemSignalLongSymbol" SG_ 2566749438 DslPrtcltFltrActvRgnrtnInhbtdStt "DslPrtcltFltrActvRgnrtnInhbtdStt";
BA_ "GenMsgCycleTime" BO_ 2566715646 1000;
BA_ "GenMsgSendType" BO_ 2566715646 0;
BA_ "VFrameFormat" BO_ 2566715646 3;
BA_ "GenMsgCycleTime" BO_ 2566724606 1000;
BA_ "GenMsgSendType" BO_ 2566724606 0;
BA_ "VFrameFormat" BO_ 2566724606 3;
BA_ "GenMsgCycleTime" BO_ 2566715902 1000;
BA_ "GenMsgSendType" BO_ 2566715902 0;
BA_ "VFrameFormat" BO_ 2566715902 3;
BA_ "GenMsgCycleTime" BO_ 2566724862 1000;
BA_ "GenMsgSendType" BO_ 2566724862 0;
BA_ "VFrameFormat" BO_ 2566724862 3;
BA_ "GenMsgCycleTime" BO_ 2566718718 1000;
BA_ "GenMsgSendType" BO_ 2566718718 0;
BA_ "VFrameFormat" BO_ 2566718718 3;
BA_ "GenMsgCycleTime" BO_ 2566718974 1000;
BA_ "GenMsgSendType" BO_ 2566718974 0;
BA_ "VFrameFormat" BO_ 2566718974 3;
BA_ "VFrameFormat" BO_ 2566719230 3;
BA_ "VFrameFormat" BO_ 2560818942 3;
BA_ "VFrameFormat" BO_ 2561212158 3;
BA_ "GenMsgCycleTime" BO_ 2566746366 1000;
BA_ "VFrameFormat" BO_ 2566746366 3;
BA_ "VFrameFormat" BO_ 2566750206 3;
BA_ "GenMsgCycleTime" BO_ 2566755582 100;
BA_ "GenMsgSendType" BO_ 2566755582 0;
BA_ "VFrameFormat" BO_ 2566755582 3;
BA_ "VFrameFormat" BO_ 2566746110 3;
BA_ "SystemSignalLongSymbol" SG_ 2566746110 EngExhstGsRcrcltn1ClrIntkGsAbsPr "EngExhstGsRcrcltn1ClrIntkGsAbsPr";
BA_ "GenMsgCycleTime" BO_ 2566752510 500;
BA_ "GenMsgSendType" BO_ 2566752510 0;
BA_ "VFrameFormat" BO_ 2566752510 3;
BA_ "GenMsgCycleTime" BO_ 2566752254 500;
BA_ "GenMsgSendType" BO_ 2566752254 0;
BA_ "VFrameFormat" BO_ 2566752254 3;
BA_ "GenMsgCycleTime" BO_ 2566751998 500;
BA_ "GenMsgSendType" BO_ 2566751998 0;
BA_ "VFrameFormat" BO_ 2566751998 3;
BA_ "GenMsgCycleTime" BO_ 2566751742 500;
BA_ "GenMsgSendType" BO_ 2566751742 0;
BA_ "VFrameFormat" BO_ 2566751742 3;
BA_ "GenMsgCycleTime" BO_ 2566751486 500;
BA_ "GenMsgSendType" BO_ 2566751486 0;
BA_ "VFrameFormat" BO_ 2566751486 3;
BA_ "GenMsgCycleTime" BO_ 2499641854 500;
BA_ "GenMsgSendType" BO_ 2499641854 0;
BA_ "VFrameFormat" BO_ 2499641854 3;
BA_ "VFrameFormat" BO_ 2566748158 3;
BA_ "VFrameFormat" BO_ 2566747902 3;
BA_ "VFrameFormat" BO_ 2566747646 3;
BA_ "VFrameFormat" BO_ 2566747390 3;
BA_ "VFrameFormat" BO_ 2566747134 3;
BA_ "VFrameFormat" BO_ 2566746878 3;
BA_ "VFrameFormat" BO_ 2561277694 3;
BA_ "VFrameFormat" BO_ 2633861886 3;
BA_ "GenMsgCycleTime" BO_ 2565873150 10;
BA_ "GenMsgSendType" BO_ 2565873150 0;
BA_ "VFrameFormat" BO_ 2565873150 3;
BA_ "VFrameFormat" BO_ 2566745854 3;
BA_ "SystemSignalLongSymbol" SG_ 2566745854 Aftrtrtmnt1SCRCtlystCnvrsnEffcnc "Aftrtrtmnt1SCRCtlystCnvrsnEffcnc";
BA_ "SystemSignalLongSymbol" SG_ 2566745854 Aftrtrtmnt1SCRCmddCtlystRgntCnsm "Aftrtrtmnt1SCRCmddCtlystRgntCnsm";
BA_ "SystemSignalLongSymbol" SG_ 2566745854 Aftrtrtmnt1SCRAvrgCtlystRgntCnsm "Aftrtrtmnt1SCRAvrgCtlystRgntCnsm";
BA_ "SystemSignalLongSymbol" SG_ 2566745854 Aftrtrtmnt1DslExhstFldTnkLwLvlIn "Aftrtrtmnt1DslExhstFldTnkLwLvlIn";
BA_ "GenMsgCycleTime" BO_ 2566751230 1000;
BA_ "GenMsgSendType" BO_ 2566751230 0;
BA_ "VFrameFormat" BO_ 2566751230 3;
BA_ "GenMsgCycleTime" BO_ 2566755838 1000;
BA_ "GenMsgSendType" BO_ 2566755838 0;
BA_ "VFrameFormat" BO_ 2566755838 3;
BA_ "VFrameFormat" BO_ 2566752766 3;
BA_ "GenMsgSendType" BO_ 2633938942 8;
BA_ "VFrameFormat" BO_ 2633938942 3;
BA_ "GenMsgSendType" BO_ 2566799614 8;
BA_ "VFrameFormat" BO_ 2566799614 3;
BA_ "GenMsgSendType" BO_ 2365473278 8;
BA_ "VFrameFormat" BO_ 2365473278 3;
BA_ "GenMsgCycleTime" BO_ 2365485822 50;
BA_ "GenMsgSendType" BO_ 2365485822 0;
BA_ "VFrameFormat" BO_ 2365485822 3;
BA_ "GenMsgSendType" BO_ 2633926654 8;
BA_ "VFrameFormat" BO_ 2633926654 3;
BA_ "GenMsgSendType" BO_ 2633926398 8;
BA_ "VFrameFormat" BO_ 2633926398 3;
BA_ "GenMsgSendType" BO_ 2633926142 8;
BA_ "VFrameFormat" BO_ 2633926142 3;
BA_ "GenMsgSendType" BO_ 2633925886 8;
BA_ "VFrameFormat" BO_ 2633925886 3;
BA_ "GenMsgSendType" BO_ 2633925630 8;
BA_ "VFrameFormat" BO_ 2633925630 3;
BA_ "GenMsgSendType" BO_ 2633925374 8;
BA_ "VFrameFormat" BO_ 2633925374 3;
BA_ "GenMsgSendType" BO_ 2633927422 8;
BA_ "VFrameFormat" BO_ 2633927422 3;
BA_ "GenMsgSendType" BO_ 2633927166 8;
BA_ "VFrameFormat" BO_ 2633927166 3;
VAL_ 2147483648 TirePressThresholdDetection 7 "NotAvailable" 6 "ErrorIndicator" 5 "NotDefined" 4 "ExtrmUndrPrssTrPrssrIsAtALvlWhr" 3 "UndrPrssTrPrssrIsLwrThnThPrssrD" 2 "NWrnngPrssTrPrssrIsWthnThThrshl" 1 "OvrPrssTrPrssrIsHghrThnThPrssrD" 0 "ExtrmOvrPrssTrPrssrIsAtALvlWhrT";
VAL_ 2147483648 CTIWheelEndElectricalFault 3 "NotSupported" 2 "Error" 1 "NotDefined" 0 "Ok";
VAL_ 2147483648 CTITireStatus 3 "NotSupported" 2 "Error" 1 "TireLeakDetected" 0 "Ok";
VAL_ 2147483648 CTIWheelSensorStatus 3 "NotSupported" 2 "NotDefined" 1 "On" 0 "Off_IsolatedFromCTIPressCtrl";
VAL_ 2297441790 SpprtVrblTrnsRpttnRtFrAcclrtnSns 1 "MsTransRate";
VAL_ 2297441790 VrtclAcclrtnExRngeFigureOfMerit 3 "NotAvailable" 2 "Error" 1 "VrtclcclrtnIsDgrddDtIsSspctDTEn" 0 "VrtclAcclrtnIsFllyFnctnlDtIsWth";
VAL_ 2297441790 LngtdnlAcclrtnExRngFgureOfMerit 3 "NotAvailable" 2 "Error" 1 "LngtdnlAcclrtnIsDgrddDtIsSspctD" 0 "LngtdnlAcclrtnIsFllyFnctnlDtIsW";
VAL_ 2297441790 LtrlAcclrtnExRangeFigureOfMerit 3 "NotAvailable" 2 "Error" 1 "LtrlAcclrtnIsDgrddDtIsSspctDTEn" 0 "LtrlAcclrtnIsFllyFnctnlDtIsWthn";
VAL_ 2364549630 RollAngleExRangeFigureOfMerit 3 "NotAvailable" 2 "Error" 1 "RllRtDgrddDtIsSspctDTEnvrnmntlC" 0 "RllRtFllyFnctnlDtIsWthnSnsrSpcf";
VAL_ 2364549630 RollAngleExRangeCompensation 3 "NotAvailable" 2 "Error" 1 "Off" 0 "On";
VAL_ 2364549630 PitchAngleExRangeFigureOfMerit 3 "NotAvailable" 2 "Error" 1 "PtchRtDgrddDtIsSspctDTEnvrnmntl" 0 "PtchRtFllyFnctnlDtIsWthnSnsrSpc";
VAL_ 2364549630 PitchAngleExRangeCompensation 3 "NotAvailable" 2 "Error" 1 "Off" 0 "On";
VAL_ 2499614462 OccpntClssfcationSystem10Status 3 "NotAvailable" 2 "ErrrClssfctonCannotBeDetermined" 1 "Occupied" 0 "Empty";
VAL_ 2499614462 OccpntClssficationSystem9Status 3 "NotAvailable" 2 "ErrrClssfctonCannotBeDetermined" 1 "Occupied" 0 "Empty";
VAL_ 2499614462 OccpntClssficationSystem8Status 3 "NotAvailable" 2 "ErrrClssfctonCannotBeDetermined" 1 "Occupied" 0 "Empty";
VAL_ 2499614462 OccpntClssficationSystem7Status 3 "NotAvailable" 2 "ErrrClssfctonCannotBeDetermined" 1 "Occupied" 0 "Empty";
VAL_ 2499614462 OccpntClssficationSystem6Status 3 "NotAvailable" 2 "ErrrClssfctonCannotBeDetermined" 1 "Occupied" 0 "Empty";
VAL_ 2499614462 OccpntClssficationSystem5Status 3 "NotAvailable" 2 "ErrrClssfctonCannotBeDetermined" 1 "Occupied" 0 "Empty";
VAL_ 2499614462 OccpntClssficationSystem4Status 3 "NotAvailable" 2 "ErrrClssfctonCannotBeDetermined" 1 "Occupied" 0 "Empty";
VAL_ 2499614462 OccpntClssficationSystem3Status 3 "NotAvailable" 2 "ErrrClssfctonCannotBeDetermined" 1 "Occupied" 0 "Empty";
VAL_ 2499614462 PssngrOccpntClssfctnSystmStatus 7 "NotAvailable" 5 "ErrrClssfctnOfOccpntCnntBDtrmnd" 3 "Adult" 4 "LargeAdult" 2 "SmallAdult" 1 "Child" 0 "Empty";
VAL_ 2499614462 DrvrOccpntClssfctonSystemStatus 7 "NotAvailable" 6 "ErrrClssfctnOfOccpntCnntBDtrmnd" 5 "Reserved" 4 "LargeAdult" 3 "Adult" 2 "SmallAdult" 1 "Child" 0 "Empty";
VAL_ 2560098046 CabNoiseCtrlTuningStatus 15 "NotAvailable_NotTuning_NotRqed" 14 "TuningModeError" 10 "AutomaticTuningModeSavingData" 9 "AutomaticTuningModeCmdComplete" 8 "AutomaticTuningMode" 7 "MnlTnngDndRqrsScrtyVerification" 13 "Reserved" 2 "ManualTuningModeSavingData" 1 "ManualTuningModeCmdComplete" 0 "ManualTuningMode";
VAL_ 2560098046 CabNoiseCtrlStatus 3 "NotAvailable_NotRqed" 2 "ErrorIndicator" 1 "CabNoiseCtrlSystemOFFLine" 0 "CabNoiseCtrlSystemONLine";
VAL_ 2560163582 CabNoiseCtrlTuningState 7 "DontCareNOTCmded" 6 "Reserved" 5 "ExitTuningSavingParameters" 4 "ExitTuningNotSavingParameters" 3 "RmnInTningSaveCurrentParameters" 2 "ActvtAtmtcTnngSttSvngPrmtrsExtO" 1 "ActvtAtmtcTnngWtFrSvAndExitCmds" 0 "ActvtMnlTnngWtFrSaveAndExitCmds";
VAL_ 2560163582 CabNoiseCtrlState 3 "DontCare_NotCmded" 2 "Reserved" 1 "BringCabNoiseCtrlSystemOnLine" 0 "TakeCabNoiseCtrlSystemOffLine";
VAL_ 2297441534 DropRelayCtrl 3 "TakeNoAction" 2 "Reserved" 1 "OnEnableDropRelayRq" 0 "OffDisableDropRelayRq";
VAL_ 2297441534 LiftRelayCtrl 3 "TakeNoAction" 2 "Reserved" 1 "OnEnableLiftRelayRq" 0 "OffDisableLiftRelayRq";
VAL_ 2297441534 MaterialDropActiveStatus 3 "NotAvailable" 2 "Error" 1 "On" 0 "Off";
VAL_ 2297441534 MaterialLiftActiveStatus 3 "NotAvailable" 2 "Error" 1 "On" 0 "Off";
VAL_ 2297441534 GnratorCurrentBoostActiveStatus 3 "NotAvailable" 2 "Error" 1 "On" 0 "Off";
VAL_ 2297441534 MaterialDropSwitch 3 "NotAvailable" 2 "Error" 1 "Drop" 0 "DontDrop";
VAL_ 2297441534 MaterialLiftSwitch 3 "NotAvailable" 2 "Error" 1 "Lift" 0 "DontLift";
VAL_ 2566722302 GneratorDutyCycleExceededStatus 3 "NotAvaiable" 2 "Error" 1 "DutyCycleExceed" 0 "DutyCycleNotExceed";
VAL_ 2566722302 VoltageMonitorActiveStatus 3 "NotAvailable" 2 "Error" 1 "MonitorIsOn" 0 "MonitorIsOff";
VAL_ 2566722302 GensetEnableActiveStatus 3 "NotAvaialble" 2 "Error" 1 "Enabled" 0 "NotEnabled";
VAL_ 2566722302 ReverseCurrentRangeSetting 31 "NotAvailable" 30 "Error" 16 "11101NotUsed" 15 "16" 14 "15" 13 "14" 12 "13" 11 "12" 10 "11" 9 "10" 8 "9" 7 "8" 6 "7" 5 "6" 4 "5" 3 "4" 2 "3" 1 "2" 0 "1";
VAL_ 2566722302 GensetSoftstartActiveStatus 3 "NotAvailable" 2 "Error" 1 "On" 0 "Off";
VAL_ 2566722302 Grapple_MagnetSelectionSwitch 3 "NotAvailable" 2 "Error" 1 "MagnetSelected" 0 "GrappleSelected";
VAL_ 2566722302 GnstSystmOtptVoltageRangeStatus 3 "NotAvailable" 2 "Error" 1 "InRange" 0 "OutOfRange";
VAL_ 2566722302 GeneratorOverheatStatus 3 "NotAvailable" 2 "Error" 1 "Overheat" 0 "NotOverheat";
VAL_ 2560032510 LwVltgDscnnctDsredOperatingMode 15 "NoChange" 6 "1110Reserved" 5 "ManualConnect" 4 "ManualDisconnect" 1 "0011Reserved" 0 "Automatic";
VAL_ 2566717950 LwVltgDisconnectVoutOutputState 15 "NotAvailableNotInstalled" 14 "OutputFault" 5 "1101Reserved" 4 "ConnectPendingAlarmActive" 3 "DisconnectPendingAlarmActive" 2 "DscnnctAlrmExprdOtptOffDscnnctd" 1 "OutputOnConnected" 0 "OutputOffDisconnected";
VAL_ 2566717950 LwVoltageDisconnectOutput1State 15 "NotAvailableNotInstalled" 14 "OutputFault" 5 "1101Reserved" 4 "ConnectPendingAlarmActive" 3 "DisconnectPendingAlarmActive" 2 "DscnnctAlrmExprdOtptOffDscnnctd" 1 "OutputOnConnected" 0 "OutputOffDisconnected";
VAL_ 2566717950 LwVoltageDisconnectOutput2State 15 "NotAvailableNotInstalled" 14 "OutputFault" 5 "1101Reserved" 4 "ConnectPendingAlarmActive" 3 "DisconnectPendingAlarmActive" 2 "DscnnctAlrmExprdOtptOffDscnnctd" 1 "OutputOnConnected" 0 "OutputOffDisconnected";
VAL_ 2566717950 LwVoltageDisconnectOutput3State 15 "NotAvailableNotInstalled" 14 "OutputFault" 5 "1101Reserved" 4 "ConnectPendingAlarmActive" 3 "DisconnectPendingAlarmActive" 2 "DscnnctAlrmExprdOtptOffDscnnctd" 1 "OutputOnConnected" 0 "OutputOffDisconnected";
VAL_ 2566717950 LwVltgDscnnctCrrntOperatingMode 15 "NotAvailable" 10 "1110Reserved" 9 "ManualConnectViaHardwiredInput" 8 "MnalDisconnectViaHardwiredInput" 6 "0111Reserved" 5 "ManualConnectViaJ1939Rq" 4 "ManualDisconnectViaJ1939Rq" 1 "0011Reserved" 0 "Automatic";
VAL_ 2566717950 LwVltgDscnnctManualConnectState 3 "NotInstalled" 2 "Error" 1 "InputOn" 0 "InputOff";
VAL_ 2566717950 LwVltgDscnnctMnlDisconnectState 3 "NotInstalled" 2 "Error" 1 "InputOn" 0 "InputOff";
VAL_ 2358902526 Joystick3Lamp10Cmd 3 "NotAvailableNotInstalled" 2 "Blinking" 1 "On" 0 "Off";
VAL_ 2358902526 Joystick3Lamp9Cmd 3 "NotAvailableNotInstalled" 2 "Blinking" 1 "On" 0 "Off";
VAL_ 2358902526 Joystick3Lamp8Cmd 3 "NotAvailableNotInstalled" 2 "Blinking" 1 "On" 0 "Off";
VAL_ 2358902526 Joystick3Lamp7Cmd 3 "NotAvailableNotInstalled" 2 "Blinking" 1 "On" 0 "Off";
VAL_ 2358902526 Joystick3Lamp6Cmd 3 "NotAvailableNotInstalled" 2 "Blinking" 1 "On" 0 "Off";
VAL_ 2358902526 Joystick3Lamp5Cmd 3 "NotAvailableNotInstalled" 2 "Blinking" 1 "On" 0 "Off";
VAL_ 2358902526 Joystick3Lamp4Cmd 3 "NotAvailableNotInstalled" 2 "Blinking" 1 "On" 0 "Off";
VAL_ 2358902526 Joystick3Lamp3Cmd 3 "NotAvailableNotInstalled" 2 "Blinking" 1 "On" 0 "Off";
VAL_ 2358902526 Joystick3Lamp2Cmd 3 "NotAvailableNotInstalled" 2 "Blinking" 1 "On" 0 "Off";
VAL_ 2358902526 Joystick3Lamp1Cmd 3 "NotAvailableNotInstalled" 2 "Blinking" 1 "On" 0 "Off";
VAL_ 2358902526 Joystick2Lamp10Cmd 3 "NotAvailableNotInstalled" 2 "Blinking" 1 "On" 0 "Off";
VAL_ 2358902526 Joystick2Lamp9Cmd 3 "NotAvailableNotInstalled" 2 "Blinking" 1 "On" 0 "Off";
VAL_ 2358902526 Joystick2Lamp8Cmd 3 "NotAvailableNotInstalled" 2 "Blinking" 1 "On" 0 "Off";
VAL_ 2358902526 Joystick2Lamp7Cmd 3 "NotAvailableNotInstalled" 2 "Blinking" 1 "On" 0 "Off";
VAL_ 2358902526 Joystick2Lamp6Cmd 3 "NotAvailableNotInstalled" 2 "Blinking" 1 "On" 0 "Off";
VAL_ 2358902526 Joystick2Lamp5Cmd 3 "NotAvailableNotInstalled" 2 "Blinking" 1 "On" 0 "Off";
VAL_ 2358902526 Joystick2Lamp4Cmd 3 "NotAvailableNotInstalled" 2 "Blinking" 1 "On" 0 "Off";
VAL_ 2358902526 Joystick2Lamp3Cmd 3 "NotAvailableNotInstalled" 2 "Blinking" 1 "On" 0 "Off";
VAL_ 2358902526 Joystick2Lamp2Cmd 3 "NotAvailableNotInstalled" 2 "Blinking" 1 "On" 0 "Off";
VAL_ 2358902526 Joystick2Lamp1Cmd 3 "NotAvailableNotInstalled" 2 "Blinking" 1 "On" 0 "Off";
VAL_ 2358902526 Joystick1Lamp10Cmd 3 "NotAvailableNotInstalled" 2 "Blinking" 1 "On" 0 "Off";
VAL_ 2358902526 Joystick1Lamp9Cmd 3 "NotAvailableNotInstalled" 2 "Blinking" 1 "On" 0 "Off";
VAL_ 2358902526 Joystick1Lamp8Cmd 3 "NotAvailableNotInstalled" 2 "Blinking" 1 "On" 0 "Off";
VAL_ 2358902526 Joystick1Lamp7Cmd 3 "NotAvailableNotInstalled" 2 "Blinking" 1 "On" 0 "Off";
VAL_ 2358902526 Joystick1Lamp6Cmd 3 "NotAvailableNotInstalled" 2 "Blinking" 1 "On" 0 "Off";
VAL_ 2358902526 Joystick1Lamp5Cmd 3 "NotAvailableNotInstalled" 2 "Blinking" 1 "On" 0 "Off";
VAL_ 2358902526 Joystick1Lamp4Cmd 3 "NotAvailableNotInstalled" 2 "Blinking" 1 "On" 0 "Off";
VAL_ 2358902526 Joystick1Lamp3Cmd 3 "NotAvailableNotInstalled" 2 "Blinking" 1 "On" 0 "Off";
VAL_ 2358902526 Joystick1Lamp2Cmd 3 "NotAvailableNotInstalled" 2 "Blinking" 1 "On" 0 "Off";
VAL_ 2358902526 Joystick1Lamp1Cmd 3 "NotAvailableNotInstalled" 2 "Blinking" 1 "On" 0 "Off";
VAL_ 2566711550 IntkVlvActtnSystmOlPrss2SlndCtrl 3 "notAvailable" 2 "reservedForSAEAssignment" 1 "on" 0 "off";
VAL_ 2566711550 IntkVlvActtnSystmOlPrss1SlndCtrl 3 "notAvailable" 2 "reservedForSAEAssignment" 1 "on" 0 "off";
VAL_ 2566713854 EngTrbWstgtActtr2OprationStatus 14 "Error" 6 "1101ReservedForFutureAssignment" 5 "UnCtrlledShutdownActive" 4 "CtrlledShutdownActive" 3 "DerateActive" 2 "AlarmHighSeverity" 1 "Alarm" 0 "Normal";
VAL_ 2566713854 EngTrbWstgtActtr1OprationStatus 14 "Error" 6 "1101ReservedForFutureAssignment" 5 "UnCtrlledShutdownActive" 4 "CtrlledShutdownActive" 3 "DerateActive" 2 "AlarmHighSeverity" 1 "Alarm" 0 "Normal";
VAL_ 2566713854 EngTrbWstgteActuator2TempStatus 7 "NotAvailable" 6 "Error" 5 "NotDefined" 4 "LowMostSevere" 3 "LowLeastSevere" 2 "InRange" 1 "HighLeastSevere" 0 "HighMostSevere";
VAL_ 2566714366 EngTrbCmprssrBypssActtr2OprtnStt 14 "Error" 6 "1101ReservedForFutureAssignment" 5 "UnCtrlledShutdownActive" 4 "CtrlledShutdownActive" 3 "DerateActive" 2 "AlarmHighSeverity" 1 "Alarm" 0 "Normal";
VAL_ 2566714366 EngTrbCmprssrBypssActtr1OprtnStt 14 "Error" 6 "1101ReservedForFutureAssignment" 5 "UnCtrlledShutdownActive" 4 "CtrlledShutdownActive" 3 "DerateActive" 2 "AlarmHighSeverity" 1 "Alarm" 0 "Normal";
VAL_ 2566714366 EngTrbCmprssrBypssActtr2TmpStts 7 "NotAvailable" 6 "Error" 5 "NotDefined" 4 "LowMostSevere" 3 "LowLeastSevere" 2 "InRange" 1 "HighLeastSevere" 0 "HighMostSevere";
VAL_ 2566714366 EngTrbCmprssrBypassActuator2Pos 4 "RprsntsBypssFllyOpnTypcllyCmprs";
VAL_ 2566714110 EngFuelValve2OperationStatus 14 "Error" 6 "1101ReservedForFutureAssignment" 5 "UnCtrlledShutdownActive" 4 "CtrlledShutdownActive" 3 "DerateActive" 2 "AlarmHighSeverity" 1 "Alarm" 0 "Normal";
VAL_ 2566714110 EngFuelValve1OperationStatus 14 "Error" 6 "1101ReservedForFutureAssignment" 5 "UnCtrlledShutdownActive" 4 "CtrlledShutdownActive" 3 "DerateActive" 2 "AlarmHighSeverity" 1 "Alarm" 0 "Normal";
VAL_ 2566714110 EngThrttleValve2OperationStatus 14 "Error" 6 "1101ReservedForFutureAssignment" 5 "UnCtrlledShutdownActive" 4 "CtrlledShutdownActive" 3 "DerateActive" 2 "AlarmHighSeverity" 1 "Alarm" 0 "Normal";
VAL_ 2566714110 EngThrttleValve1OperationStatus 15 "NotAvailable" 14 "Error" 6 "1101ReservedForFutureAssignment" 5 "UnCtrlledShutdownActive" 4 "CtrlledShutdownActive" 3 "DerateActive" 2 "AlarmHighSeverity" 1 "Alarm" 0 "Normal";
VAL_ 2566714110 EngFuelValve2TempStatus 7 "NotAvailable" 6 "Error" 5 "NotDefined" 4 "LowMostSevere" 3 "LowLeastSevere" 2 "InRange" 1 "HighLeastSevere" 0 "HighMostSevere";
VAL_ 2566714110 EngFuelValve1TempStatus 7 "NotAvailable" 6 "Error" 5 "NotDefined" 4 "LowMostSevere" 3 "LowLeastSevere" 2 "InRange" 1 "HighLeastSevere" 0 "HighMostSevere";
VAL_ 2566714110 EngThrottleValve2TempStatus 7 "NotAvailable" 6 "Error" 5 "NotDefined" 4 "LowMostSevere" 3 "LowLeastSevere" 2 "InRange" 1 "HighLeastSevere" 0 "HighMostSevere";
VAL_ 2566714110 EngThrottleValve1TempStatus 7 "NotAvailable" 6 "Error" 5 "NotDefined" 4 "LowMostSevere" 3 "LowLeastSevere" 2 "InRange" 1 "HighLeastSevere" 0 "HighMostSevere";
VAL_ 2499607550 EngExhstMnfldBnk1FlwBlncVlvActtr 4 "MeansMaxValveOpening";
VAL_ 2633825534 EngExhstMnfldBnk2FlwBlncVlv_0000 4 "MeansMaxValveOpening";
VAL_ 2365400574 Jystck9GripXAxisDetentPosStatus 3 "NotAvailable" 2 "ErrorIndicator" 1 "InDetentPos" 0 "NotInDetentPos";
VAL_ 2365400574 Jystck9GripYAxisDetentPosStatus 3 "NotAvailable" 2 "ErrorIndicator" 1 "InDetentPos" 0 "NotInDetentPos";
VAL_ 2365400574 Jystck9ThetaAxisDetentPosStatus 3 "NotAvailable" 2 "ErrorIndicator" 1 "InDetentPos" 0 "NotInDetentPos";
VAL_ 2365400574 Jystck9ThtAxsClckwsPstvPsStatus 3 "NotAvailable" 2 "ErrorIndicator" 1 "OnPositiveSideOfNeutral" 0 "NotOnPositiveSideOfNeutral";
VAL_ 2365400574 Jystck9ThtAxsCntrClckwsNgtvPsStt 3 "NotAvailable" 2 "ErrorIndicator" 1 "OnNegativeSideOfNeutral" 0 "NotOnNegativeSideOfNeutral";
VAL_ 2365400574 Jystck9ThtaAxisNeutralPosStatus 3 "NotAvailable" 2 "ErrorIndicator" 1 "InNeutralPos" 0 "NotInNeutralPos";
VAL_ 2365400574 Jystck9GrpYAxsLvrFrwrdPstvPsStts 3 "NotAvailable" 2 "ErrorIndicator" 1 "OnPositiveSideOfNeutral" 0 "NotOnPositiveSideOfNeutral";
VAL_ 2365400574 Jystck9GrpYAxsLvrBckNgtvPsSttus 3 "NotAvailable" 2 "ErrorIndicator" 1 "OnNegativeSideOfNeutral" 0 "NotOnNegativeSideOfNeutral";
VAL_ 2365400574 Jystck9GrpYAxisNeutralPosStatus 3 "NotAvailable" 2 "ErrorIndicator" 1 "InNeutralPos" 0 "NotInNeutralPos";
VAL_ 2365400574 Jystck9GrpXAxsLvrRghtPstvPsStts 3 "NotAvailable" 2 "ErrorIndicator" 1 "OnPositiveSideOfNeutral" 0 "NotOnPositiveSideOfNeutral";
VAL_ 2365400574 Jystck9GrpXAxsLvrLftNgtvPsSttus 3 "NotAvailable" 2 "ErrorIndicator" 1 "OnNegativeSideOfNeutral" 0 "NotOnNegativeSideOfNeutral";
VAL_ 2365400574 Jystck9GrpXAxisNeutralPosStatus 3 "NotAvailable" 2 "ErrorIndicator" 1 "InNeutralPos" 0 "NotInNeutralPos";
VAL_ 2365401086 Jystck8GripXAxisDetentPosStatus 3 "NotAvailable" 2 "ErrorIndicator" 1 "InDetentPos" 0 "NotInDetentPos";
VAL_ 2365401086 Jystck8GripYAxisDetentPosStatus 3 "NotAvailable" 2 "ErrorIndicator" 1 "InDetentPos" 0 "NotInDetentPos";
VAL_ 2365401086 Jystck8ThetaAxisDetentPosStatus 3 "NotAvailable" 2 "ErrorIndicator" 1 "InDetentPos" 0 "NotInDetentPos";
VAL_ 2365401086 Jystck8ThtAxsClckwsPstvPsStatus 3 "NotAvailable" 2 "ErrorIndicator" 1 "OnPositiveSideOfNeutral" 0 "NotOnPositiveSideOfNeutral";
VAL_ 2365401086 Jystck8ThtAxsCntrClckwsNgtvPsStt 3 "NotAvailable" 2 "ErrorIndicator" 1 "OnNegativeSideOfNeutral" 0 "NotOnNegativeSideOfNeutral";
VAL_ 2365401086 Jystck8ThtaAxisNeutralPosStatus 3 "NotAvailable" 2 "ErrorIndicator" 1 "InNeutralPos" 0 "NotInNeutralPos";
VAL_ 2365401086 Jystck8GrpYAxsLvrFrwrdPstvPsStts 3 "NotAvailable" 2 "ErrorIndicator" 1 "OnPositiveSideOfNeutral" 0 "NotOnPositiveSideOfNeutral";
VAL_ 2365401086 Jystck8GrpYAxsLvrBckNgtvPsSttus 3 "NotAvailable" 2 "ErrorIndicator" 1 "OnNegativeSideOfNeutral" 0 "NotOnNegativeSideOfNeutral";
VAL_ 2365401086 Jystck8GrpYAxisNeutralPosStatus 3 "NotAvailable" 2 "ErrorIndicator" 1 "InNeutralPos" 0 "NotInNeutralPos";
VAL_ 2365401086 Jystck8GrpXAxsLvrRghtPstvPsStts 3 "NotAvailable" 2 "ErrorIndicator" 1 "OnPositiveSideOfNeutral" 0 "NotOnPositiveSideOfNeutral";
VAL_ 2365401086 Jystck8GrpXAxsLvrLftNgtvPsSttus 3 "NotAvailable" 2 "ErrorIndicator" 1 "OnNegativeSideOfNeutral" 0 "NotOnNegativeSideOfNeutral";
VAL_ 2365401086 Jystck8GrpXAxisNeutralPosStatus 3 "NotAvailable" 2 "ErrorIndicator" 1 "InNeutralPos" 0 "NotInNeutralPos";
VAL_ 2365401598 Jystck7GripXAxisDetentPosStatus 3 "NotAvailable" 2 "ErrorIndicator" 1 "InDetentPos" 0 "NotInDetentPos";
VAL_ 2365401598 Jystck7GripYAxisDetentPosStatus 3 "NotAvailable" 2 "ErrorIndicator" 1 "InDetentPos" 0 "NotInDetentPos";
VAL_ 2365401598 Jystck7ThetaAxisDetentPosStatus 3 "NotAvailable" 2 "ErrorIndicator" 1 "InDetentPos" 0 "NotInDetentPos";
VAL_ 2365401598 Jystck7ThtAxsClckwsPstvPsStatus 3 "NotAvailable" 2 "ErrorIndicator" 1 "OnPositiveSideOfNeutral" 0 "NotOnPositiveSideOfNeutral";
VAL_ 2365401598 Jystck7ThtAxsCntrClckwsNgtvPsStt 3 "NotAvailable" 2 "ErrorIndicator" 1 "OnNegativeSideOfNeutral" 0 "NotOnNegativeSideOfNeutral";
VAL_ 2365401598 Jystck7ThtaAxisNeutralPosStatus 3 "NotAvailable" 2 "ErrorIndicator" 1 "InNeutralPos" 0 "NotInNeutralPos";
VAL_ 2365401598 Jystck7GrpYAxsLvrFrwrdPstvPsStts 3 "NotAvailable" 2 "ErrorIndicator" 1 "OnPositiveSideOfNeutral" 0 "NotOnPositiveSideOfNeutral";
VAL_ 2365401598 Jystck7GrpYAxsLvrBckNgtvPsSttus 3 "NotAvailable" 2 "ErrorIndicator" 1 "OnNegativeSideOfNeutral" 0 "NotOnNegativeSideOfNeutral";
VAL_ 2365401598 Jystck7GrpYAxisNeutralPosStatus 3 "NotAvailable" 2 "ErrorIndicator" 1 "InNeutralPos" 0 "NotInNeutralPos";
VAL_ 2365401598 Jystck7GrpXAxsLvrRghtPstvPsStts 3 "NotAvailable" 2 "ErrorIndicator" 1 "OnPositiveSideOfNeutral" 0 "NotOnPositiveSideOfNeutral";
VAL_ 2365401598 Jystck7GrpXAxsLvrLftNgtvPsSttus 3 "NotAvailable" 2 "ErrorIndicator" 1 "OnNegativeSideOfNeutral" 0 "NotOnNegativeSideOfNeutral";
VAL_ 2365401598 Jystck7GrpXAxisNeutralPosStatus 3 "NotAvailable" 2 "ErrorIndicator" 1 "InNeutralPos" 0 "NotInNeutralPos";
VAL_ 2365402110 Jystck6GripXAxisDetentPosStatus 3 "NotAvailable" 2 "ErrorIndicator" 1 "InDetentPos" 0 "NotInDetentPos";
VAL_ 2365402110 Jystck6GripYAxisDetentPosStatus 3 "NotAvailable" 2 "ErrorIndicator" 1 "InDetentPos" 0 "NotInDetentPos";
VAL_ 2365402110 Jystck6ThetaAxisDetentPosStatus 3 "NotAvailable" 2 "ErrorIndicator" 1 "InDetentPos" 0 "NotInDetentPos";
VAL_ 2365402110 Jystck6ThtAxsClckwsPstvPsStatus 3 "NotAvailable" 2 "ErrorIndicator" 1 "OnPositiveSideOfNeutral" 0 "NotOnPositiveSideOfNeutral";
VAL_ 2365402110 Jystck6ThtAxsCntrClckwsNgtvPsStt 3 "NotAvailable" 2 "ErrorIndicator" 1 "OnNegativeSideOfNeutral" 0 "NotOnNegativeSideOfNeutral";
VAL_ 2365402110 Jystck6ThtaAxisNeutralPosStatus 3 "NotAvailable" 2 "ErrorIndicator" 1 "InNeutralPos" 0 "NotInNeutralPos";
VAL_ 2365402110 Jystck6GrpYAxsLvrFrwrdPstvPsStts 3 "NotAvailable" 2 "ErrorIndicator" 1 "OnPositiveSideOfNeutral" 0 "NotOnPositiveSideOfNeutral";
VAL_ 2365402110 Jystck6GrpYAxsLvrBckNgtvPsSttus 3 "NotAvailable" 2 "ErrorIndicator" 1 "OnNegativeSideOfNeutral" 0 "NotOnNegativeSideOfNeutral";
VAL_ 2365402110 Jystck6GrpYAxisNeutralPosStatus 3 "NotAvailable" 2 "ErrorIndicator" 1 "InNeutralPos" 0 "NotInNeutralPos";
VAL_ 2365402110 Jystck6GrpXAxsLvrRghtPstvPsStts 3 "NotAvailable" 2 "ErrorIndicator" 1 "OnPositiveSideOfNeutral" 0 "NotOnPositiveSideOfNeutral";
VAL_ 2365402110 Jystck6GrpXAxsLvrLftNgtvPsSttus 3 "NotAvailable" 2 "ErrorIndicator" 1 "OnNegativeSideOfNeutral" 0 "NotOnNegativeSideOfNeutral";
VAL_ 2365402110 Jystck6GrpXAxisNeutralPosStatus 3 "NotAvailable" 2 "ErrorIndicator" 1 "InNeutralPos" 0 "NotInNeutralPos";
VAL_ 2365402622 Jystck5GripXAxisDetentPosStatus 3 "NotAvailable" 2 "ErrorIndicator" 1 "InDetentPos" 0 "NotInDetentPos";
VAL_ 2365402622 Jystck5GripYAxisDetentPosStatus 3 "NotAvailable" 2 "ErrorIndicator" 1 "InDetentPos" 0 "NotInDetentPos";
VAL_ 2365402622 Jystck5ThetaAxisDetentPosStatus 3 "NotAvailable" 2 "ErrorIndicator" 1 "InDetentPos" 0 "NotInDetentPos";
VAL_ 2365402622 Jystck5ThtAxsClckwsPstvPsStatus 3 "NotAvailable" 2 "ErrorIndicator" 1 "OnPositiveSideOfNeutral" 0 "NotOnPositiveSideOfNeutral";
VAL_ 2365402622 Jystck5ThtAxsCntrClckwsNgtvPsStt 3 "NotAvailable" 2 "ErrorIndicator" 1 "OnNegativeSideOfNeutral" 0 "NotOnNegativeSideOfNeutral";
VAL_ 2365402622 Jystck5ThtaAxisNeutralPosStatus 3 "NotAvailable" 2 "ErrorIndicator" 1 "InNeutralPos" 0 "NotInNeutralPos";
VAL_ 2365402622 Jystck5GrpYAxsLvrFrwrdPstvPsStts 3 "NotAvailable" 2 "ErrorIndicator" 1 "OnPositiveSideOfNeutral" 0 "NotOnPositiveSideOfNeutral";
VAL_ 2365402622 Jystck5GrpYAxsLvrBckNgtvPsSttus 3 "NotAvailable" 2 "ErrorIndicator" 1 "OnNegativeSideOfNeutral" 0 "NotOnNegativeSideOfNeutral";
VAL_ 2365402622 Jystck5GrpYAxisNeutralPosStatus 3 "NotAvailable" 2 "ErrorIndicator" 1 "InNeutralPos" 0 "NotInNeutralPos";
VAL_ 2365402622 Jystck5GrpXAxsLvrRghtPstvPsStts 3 "NotAvailable" 2 "ErrorIndicator" 1 "OnPositiveSideOfNeutral" 0 "NotOnPositiveSideOfNeutral";
VAL_ 2365402622 Jystck5GrpXAxsLvrLftNgtvPsSttus 3 "NotAvailable" 2 "ErrorIndicator" 1 "OnNegativeSideOfNeutral" 0 "NotOnNegativeSideOfNeutral";
VAL_ 2365402622 Jystck5GrpXAxisNeutralPosStatus 3 "NotAvailable" 2 "ErrorIndicator" 1 "InNeutralPos" 0 "NotInNeutralPos";
VAL_ 2365403134 Jystck4GripXAxisDetentPosStatus 3 "NotAvailable" 2 "ErrorIndicator" 1 "InDetentPos" 0 "NotInDetentPos";
VAL_ 2365403134 Jystck4GripYAxisDetentPosStatus 3 "NotAvailable" 2 "ErrorIndicator" 1 "InDetentPos" 0 "NotInDetentPos";
VAL_ 2365403134 Jystck4ThetaAxisDetentPosStatus 3 "NotAvailable" 2 "ErrorIndicator" 1 "InDetentPos" 0 "NotInDetentPos";
VAL_ 2365403134 Jystck4ThtAxsClckwsPstvPsStatus 3 "NotAvailable" 2 "ErrorIndicator" 1 "OnPositiveSideOfNeutral" 0 "NotOnPositiveSideOfNeutral";
VAL_ 2365403134 Jystck4ThtAxsCntrClckwsNgtvPsStt 3 "NotAvailable" 2 "ErrorIndicator" 1 "OnNegativeSideOfNeutral" 0 "NotOnNegativeSideOfNeutral";
VAL_ 2365403134 Jystck4ThtaAxisNeutralPosStatus 3 "NotAvailable" 2 "ErrorIndicator" 1 "InNeutralPos" 0 "NotInNeutralPos";
VAL_ 2365403134 Jystck4GrpYAxsLvrFrwrdPstvPsStts 3 "NotAvailable" 2 "ErrorIndicator" 1 "OnPositiveSideOfNeutral" 0 "NotOnPositiveSideOfNeutral";
VAL_ 2365403134 Jystck4GrpYAxsLvrBckNgtvPsSttus 3 "NotAvailable" 2 "ErrorIndicator" 1 "OnNegativeSideOfNeutral" 0 "NotOnNegativeSideOfNeutral";
VAL_ 2365403134 Jystck4GrpYAxisNeutralPosStatus 3 "NotAvailable" 2 "ErrorIndicator" 1 "InNeutralPos" 0 "NotInNeutralPos";
VAL_ 2365403134 Jystck4GrpXAxsLvrRghtPstvPsStts 3 "NotAvailable" 2 "ErrorIndicator" 1 "OnPositiveSideOfNeutral" 0 "NotOnPositiveSideOfNeutral";
VAL_ 2365403134 Jystck4GrpXAxsLvrLftNgtvPsSttus 3 "NotAvailable" 2 "ErrorIndicator" 1 "OnNegativeSideOfNeutral" 0 "NotOnNegativeSideOfNeutral";
VAL_ 2365403134 Jystck4GrpXAxisNeutralPosStatus 3 "NotAvailable" 2 "ErrorIndicator" 1 "InNeutralPos" 0 "NotInNeutralPos";
VAL_ 2365400062 Jystck10GrpXAxisDetentPosStatus 3 "NotAvailable" 2 "ErrorIndicator" 1 "InDetentPos" 0 "NotInDetentPos";
VAL_ 2365400062 Jystck10GrpYAxisDetentPosStatus 3 "NotAvailable" 2 "ErrorIndicator" 1 "InDetentPos" 0 "NotInDetentPos";
VAL_ 2365400062 Jystck10ThtaAxisDetentPosStatus 3 "NotAvailable" 2 "ErrorIndicator" 1 "InDetentPos" 0 "NotInDetentPos";
VAL_ 2365400062 Jystck10ThtAxsClckwsPstvPsSttus 3 "NotAvailable" 2 "ErrorIndicator" 1 "OnPositiveSideOfNeutral" 0 "NotOnPositiveSideOfNeutral";
VAL_ 2365400062 Jystck10ThtAxsCntrClckwsNgtvPsSt 3 "NotAvailable" 2 "ErrorIndicator" 1 "OnNegativeSideOfNeutral" 0 "NotOnNegativeSideOfNeutral";
VAL_ 2365400062 Jystck10ThtAxisNeutralPosStatus 3 "NotAvailable" 2 "ErrorIndicator" 1 "InNeutralPos" 0 "NotInNeutralPos";
VAL_ 2365400062 Jystck10GrpYAxsLvrFrwrdPstvPsStt 3 "NotAvailable" 2 "ErrorIndicator" 1 "OnPositiveSideOfNeutral" 0 "NotOnPositiveSideOfNeutral";
VAL_ 2365400062 Jystck10GrpYAxsLvrBckNgtvPsStts 3 "NotAvailable" 2 "ErrorIndicator" 1 "OnNegativeSideOfNeutral" 0 "NotOnNegativeSideOfNeutral";
VAL_ 2365400062 Jystck10GrpYAxsNeutralPosStatus 3 "NotAvailable" 2 "ErrorIndicator" 1 "InNeutralPos" 0 "NotInNeutralPos";
VAL_ 2365400062 Jystck10GrpXAxsLvrRghtPstvPsStts 3 "NotAvailable" 2 "ErrorIndicator" 1 "OnPositiveSideOfNeutral" 0 "NotOnPositiveSideOfNeutral";
VAL_ 2365400062 Jystck10GrpXAxsLvrLftNgtvPsStts 3 "NotAvailable" 2 "ErrorIndicator" 1 "OnNegativeSideOfNeutral" 0 "NotOnNegativeSideOfNeutral";
VAL_ 2365400062 Jystck10GrpXAxsNeutralPosStatus 3 "NotAvailable" 2 "ErrorIndicator" 1 "InNeutralPos" 0 "NotInNeutralPos";
VAL_ 2633825022 EngExhstGsRcrclation2Valve2Ctrl 4 "MeansMaxOpening";
VAL_ 2633825022 EngExhstGsRcrculation2ValveCtrl 4 "MeansMaxOpening";
VAL_ 2566749438 DslPrtcltFltrActvRgnrtnFrcdStts 7 "notAvailable" 6 "ReservedForSAEAssignment" 2 "ActiveForcedByServiceTool" 1 "ActiveForcedBySwitch" 0 "NotActive";
VAL_ 2566749438 ExhaustSystemHighTempLampCmd 7 "notAvailable" 6 "reservedForSAEAssignment" 1 "OnSolid" 0 "Off";
VAL_ 2566749438 DslPrtcltFltrAtmtcActvRgnrtnIntt 3 "notAvailable" 2 "reservedForSAEAssignment" 1 "enabled" 0 "notEnabled";
VAL_ 2566749438 DslPrtcltFltrActvRgnrtnInhbtdDTV 3 "notAvailable" 2 "reservedForSAEAssignment" 1 "inhibited" 0 "notInhibited";
VAL_ 2566749438 DslPrtcltFltrActvRgnrtnInhbtdDTE 3 "notAvailable" 2 "reservedForSAEAssignment" 1 "inhibited" 0 "notInhibited";
VAL_ 2566749438 DslPrtcltFltrActvRgnrtnInhbtdDTP 3 "notAvailable" 2 "reservedForSAEAssignment" 1 "inhibited" 0 "notInhibited";
VAL_ 2566749438 DslPrtcltFltrActvRgnrtnInhbtdDTT 3 "notAvailable" 2 "reservedForSAEAssignment" 1 "inhibited" 0 "notInhibited";
VAL_ 2566749438 DslPrtcltFltrActvRgnrtnInhbtdDTS 3 "notAvailable" 2 "reservedForSAEAssignment" 1 "inhibited" 0 "notInhibited";
VAL_ 2566749438 DslPrtcltFltrActvRgnrtnInhb_0000 3 "notAvailable" 2 "reservedForSAEAssignment" 1 "inhibited" 0 "notInhibited";
VAL_ 2566749438 DslPrtcltFltrActvRgnrtnInhbtdDTL 3 "notAvailable" 2 "reservedForSAEAssignment" 1 "inhibited" 0 "notInhibited";
VAL_ 2566749438 DslPrtcltFltrActvRgnrtnInhb_0001 3 "notAvailable" 2 "reservedForSAEAssignment" 1 "inhibited" 0 "notInhibited";
VAL_ 2566749438 DslPrtcltFltrActvRgnrtnInhb_0002 3 "notAvailable" 2 "reservedForSAEAssignment" 1 "inhibited" 0 "notInhibited";
VAL_ 2566749438 DslPrtcltFltrActvRgnrtnInhbtdDTO 3 "notAvailable" 2 "reservedForSAEAssignment" 1 "inhibited" 0 "notInhibited";
VAL_ 2566749438 DslPrtcltFltrActvRgnrtnInhbtdDTA 3 "notAvailable" 2 "reservedForSAEAssignment" 1 "inhibited" 0 "notInhibited";
VAL_ 2566749438 DslPrtcltFltrActvRgnrtnInhb_0003 3 "notAvailable" 2 "reservedForSAEAssignment" 1 "inhibited" 0 "notInhibited";
VAL_ 2566749438 DslPrtcltFltrActvRgnrtnInhb_0004 3 "notAvailable" 2 "reservedForSAEAssignment" 1 "inhibited" 0 "notInhibited";
VAL_ 2566749438 DslPrtcltFltrActvRgnrtnInhbtdDTC 3 "notAvailable" 2 "reservedForSAEAssignment" 1 "inhibited" 0 "notInhibited";
VAL_ 2566749438 DslPrtcltFltrActvRgnrtnInhbtdDTI 3 "notAvailable" 2 "reservedForSAEAssignment" 1 "inhibited" 0 "notInhibited";
VAL_ 2566749438 DslPrtcltFltrActvRgnrtnInhbtdStt 3 "notAvailable" 2 "reservedForSAEAssignment" 1 "inhibited" 0 "notInhibited";
VAL_ 2566749438 DieselParticulateFilterStatus 7 "notAvailable" 6 "reservedForSAEAssignment" 3 "RegenerationNeededHighestLevel" 2 "RegenerationNeededModerateLevel" 1 "RegenerationNeededLowestLevel" 0 "RegenerationNotNeeded";
VAL_ 2566749438 DslPrtcltFltrActvRgnrtionStatus 3 "notAvailable" 2 "rgnrtnNddAtmtcllyInttdActvRgnrt" 1 "active" 0 "notActive";
VAL_ 2566749438 DslPrtcltFltrPssvRgnrtionStatus 3 "notAvailable" 2 "reservedForSAEAssignment" 1 "active" 0 "notActive";
VAL_ 2566749438 DieselParticulateFilterLampCmd 7 "notAvailable" 4 "OnFastBlink" 6 "reservedForSAEAssignment" 1 "OnSolid" 0 "Off";
VAL_ 2566718718 VehicleBatteryChargingLampData 3 "NotAvailable" 2 "Error" 1 "LampActivated" 0 "LampDeactivated";
VAL_ 2566718718 VhicleHVACRecirculationLampData 3 "NotAvailable" 2 "Error" 1 "LampActivated" 0 "LampDeactivated";
VAL_ 2566718718 VehicleAirPressLowLampData 3 "NotAvailable" 2 "Error" 1 "LampActivated" 0 "LampDeactivated";
VAL_ 2566718718 VehicleFuelLevelLowLampData 3 "NotAvailable" 2 "Error" 1 "LampActivated" 0 "LampDeactivated";
VAL_ 2566718718 VhicleBatteryVoltageLowLampData 3 "NotAvailable" 2 "Error" 1 "LampActivated" 0 "LampDeactivated";
VAL_ 2566718974 EngWaitToStartLampData 3 "NotAvailable" 2 "Error" 1 "LampActive" 0 "LampDeactive";
VAL_ 2566718974 EngFuelFilterRestrictedLampData 3 "NotAvailable" 2 "Error" 1 "LampActivated" 0 "LampDeactivated";
VAL_ 2566718974 EngAirFilterRestrictionLampData 3 "NotAvailable" 2 "Error" 1 "LampActivated" 0 "LampDeactivated";
VAL_ 2566718974 EngIdleManagementActiveLampData 3 "NotAvailable" 2 "Error" 1 "LampActivated" 0 "LampDeactivated";
VAL_ 2566718974 EngCoolantLevelLowLampData 3 "NotAvailable" 2 "Error" 1 "LampActivated" 0 "LampDeactivated";
VAL_ 2566718974 EngCoolantTempHighLampData 3 "NotAvailable" 2 "Error" 1 "LampActivated" 0 "LampDeactivated";
VAL_ 2566718974 EngOilPressLowLampData 3 "NotAvailable" 2 "Error" 1 "LampActivated" 0 "LampDeactivated";
VAL_ 2566718974 CmprssnBrkEnblSwtchIndctrLmpDta 3 "NotAvailable" 2 "Error" 1 "LampActivated" 0 "LampDeactivated";
VAL_ 2566718974 EngBrakeActiveLampData 3 "NotAvailable" 2 "Error" 1 "LampActivated" 0 "LampDeactivated";
VAL_ 2566718974 OBDMalfunctionIndicatorLampData 3 "NotAvailable" 2 "Error" 1 "LampActivated" 0 "LampDeactivated";
VAL_ 2566718974 EngRedStopLampData 3 "NotAvailable" 2 "Error" 1 "LampActivated" 0 "LampDeactivated";
VAL_ 2566718974 EngAmberWarningLampData 3 "NotAvailable" 2 "Error" 1 "LampActivated" 0 "LampDeactivated";
VAL_ 2566718974 EngProtectLampData 3 "NotAvailable" 2 "Error" 1 "LampActivated" 0 "LampDeactivated";
VAL_ 2566719230 VehicleBatteryChargingLampCmd 3 "NotAvailable" 2 "Reserved" 1 "LampOn" 0 "LampOff";
VAL_ 2566719230 VehicleHVACRecirculationLampCmd 3 "NotAvailable" 2 "Reserved" 1 "LampOn" 0 "LampOff";
VAL_ 2566719230 VehicleAirPressLowLampCmd 3 "NotAvailable" 2 "Reserved" 1 "LampOn" 0 "LampOff";
VAL_ 2566719230 VehicleFuelLevelLowLampCmd 3 "NotAvailable" 2 "Reserved" 1 "LampOn" 0 "LampOff";
VAL_ 2566719230 VehicleBatteryVoltageLowLampCmd 3 "NotAvailable" 2 "Reserved" 1 "LampOn" 0 "LampOff";
VAL_ 2560818942 FailureModeIdentifier1 31 "Not available" 19 "Received network data in error" 18 "Below normal (moderately severe)" 17 "Below normal (least severe)" 16 "Above normal (moderately severe)" 15 "Above normal (least severe)" 14 "Special intstructions" 13 "Out of calibration" 12 "Bad intelligent device" 11 "Root cause not known" 10 "Abnormal rate of change" 9 "Abnormal update rate" 8 "Abnormal frequency" 7 "Mechanical system not responding" 6 "Current above normal" 5 "Current below normal" 4 "Voltage below normal" 3 "Voltage above normal" 2 "Data erratic" 1 "Below normal (most severe)" 0 "Above normal (most severe)";
VAL_ 2561212158 TextDisplayInstructions 7 "1110Reserved" 6 "BlinkSubstring" 15 "NotApplicable" 1 "HldDsplyPrsntlyDsplydInfrmtnShl" 0 "ClrDsplyDsplydInfrmtnShldBDltdN" 5 "HighlightSubstring" 4 "OvrwrtSbstrngAPrtnOfPrsntlyDspl" 3 "OvrwrtDsplyPrsntlyDsplydInfrmtn" 2 "AppndAtEndOfDsplyTrnsmttdInfrmt";
VAL_ 2566746366 RetractStatusOfRamp5 2 "error" 1 "rampEx" 0 "rampRetracted" 3 "notAvailable";
VAL_ 2566746366 RetractStatusOfRamp4 3 "notAvailable" 2 "error" 1 "rampEx" 0 "rampRetracted";
VAL_ 2566746366 MovementStatusOfRamp5 3 "notAvailable" 2 "error" 1 "rampBeingMoved" 0 "rampNotBeingMoved";
VAL_ 2566746366 MovementStatusOfRamp4 3 "notAvailable" 2 "error" 1 "rampBeingMoved" 0 "rampNotBeingMoved";
VAL_ 2566746366 EnableStatusOfRamp5 3 "notAvailable" 2 "error" 1 "rampEnabled" 0 "rampDisabled";
VAL_ 2566746366 EnableStatusOfRamp4 3 "notAvailable" 2 "error" 1 "rampEnabled" 0 "rampDisabled";
VAL_ 2566746366 MovementStatusOfRamp3 3 "notAvailable" 2 "error" 1 "rampBeingMoved" 0 "rampNotBeingMoved";
VAL_ 2566746366 EnableStatusOfRamp3 3 "notAvailable" 2 "error" 1 "rampEnabled" 0 "rampDisabled";
VAL_ 2566746366 RetractStatusOfRamp3 3 "notAvailable" 2 "error" 1 "rampEx" 0 "rampRetracted";
VAL_ 2566746366 MovementStatusOfRamp2 3 "notAvailable" 2 "error" 1 "rampBeingMoved" 0 "rampNotBeingMoved";
VAL_ 2566746366 EnableStatusOfRamp2 3 "notAvailable" 2 "error" 1 "rampEnabled" 0 "rampDisabled";
VAL_ 2566746366 RetractStatusOfRamp2 3 "notAvailable" 2 "error" 1 "rampEx" 0 "rampRetracted";
VAL_ 2566746366 MovementStatusOfRamp1 3 "notAvailable" 2 "error" 1 "rampBeingMoved" 0 "rampNotBeingMoved";
VAL_ 2566746366 EnableStatusOfRamp1 3 "notAvailable" 2 "error" 1 "rampEnabled" 0 "rampDisabled";
VAL_ 2566746366 RetractStatusOfRamp1 3 "notAvailable" 2 "error" 1 "rampEx" 0 "rampRetracted";
VAL_ 2566746110 EngExhstGsRcrclation1Valve2Ctrl 4 "MeansMaxValveOpening";
VAL_ 2561277694 LaneDepartureWarningEnableCmd 3 "DonTCare" 2 "Reserved" 1 "EnableLaneDepartureWarning" 0 "DisableLaneDepartureWarning";
VAL_ 2633861886 J2012DTCStatus 1 "DTCIsActive" 0 "DTCIsPreviouslyActive";
VAL_ 2565873150 SteerAngleSensorCalibrated 3 "NotAvailable" 2 "Reserved" 1 "SASCalibrated" 0 "SASNotCalibrated";
VAL_ 2565873150 SteerAngleSensorActiveMode 3 "NotAvailable" 2 "Reserved" 1 "NormalModeActive" 0 "ProgrammingModeActive";
VAL_ 2565873150 SteerWheelAngleRangeCounterType 3 "SignalNotAvailable" 2 "NotDefined" 1 "AbsNumberOfCounts" 0 "RelativeNumberOfCounts";
VAL_ 2566751230 TransferCaseStatus 7 "notAvailable" 6 "error" 5 "TrnsfrCsShftInPrgrssGrNtCnfrmed" 4 "WheelLow" 2 "neutral" 1 "WheelHigh";
VAL_ 2566755838 TransOverheatIndicator 3 "NotAvailable" 2 "TrnsOverheatIndicatorIsFlashing" 1 "TrnsOvrhtIndctrIsOnContinuously" 0 "TransOverheatIndicatorIsOff";
VAL_ 2566755838 TransOilLevelSwitch 3 "NotAvailable" 2 "Error" 1 "FullNotEmpty" 0 "Empty";
VAL_ 2566755838 TransOilFilterRestrictionSwitch 3 "NotAvailable" 2 "Error" 1 "RestrictionExistsOnOilFilter" 0 "NoRestriction";
VAL_ 2566799614 ImplementRearWorkLight 3 "NotAvailable" 2 "FaultDetected" 1 "Activated" 0 "Deactivated";
VAL_ 2566799614 ImplementLeftForwardWorkLight 3 "NotAvailable" 2 "FaultDetected" 1 "Activated" 0 "Deactivated";
VAL_ 2566799614 ImplementRightForwardWorkLight 3 "NotAvailable" 2 "FaultDetected" 1 "Activated" 0 "Deactivated";
VAL_ 2566799614 ImplementLeftFacingWorkLight 3 "NotAvailable" 2 "FaultDetected" 1 "Activate" 0 "Deactivate";
VAL_ 2566799614 ImplementRightFacingWorkLight 3 "NotAvailable" 2 "FaultDetected" 1 "Activated" 0 "Deactivated";
VAL_ 2566799614 ImplementOEMOption1Light 3 "NotAvailable" 2 "FaultDetected" 1 "Activated" 0 "Deactivated";
VAL_ 2566799614 ImplementOEMOption2Light 3 "NotAvailable" 2 "FaultDetected" 1 "Activated" 0 "Deactivated";
VAL_ 2566799614 TrctrFrontHighMountedWorkLights 3 "NotAvailable" 2 "FaultDetected" 1 "Activated" 0 "Deactivated";
VAL_ 2566799614 TrctorFrontLowMountedWorkLights 3 "NotAvailable" 2 "FaultDetected" 1 "Activated" 0 "Deactivated";
VAL_ 2566799614 TrctorSideHighMountedWorkLights 3 "NotAvailable" 2 "FaultDetected" 1 "Activated" 0 "Deactivated";
VAL_ 2566799614 TractorSideLowMountedWorkLights 3 "NotAvailable" 2 "FaultDetected" 1 "Activated" 0 "Deactivated";
VAL_ 2566799614 TrctorRearHighMountedWorkLights 3 "NotAvailable" 2 "FaultDetected" 1 "Activated" 0 "Deactivated";
VAL_ 2566799614 TractorRearLowMountedWorkLights 3 "NotAvailable" 2 "FaultDetected" 1 "Activated" 0 "Deactivated";
VAL_ 2566799614 TrctrUndersideMountedWorkLights 3 "NotAvailable" 2 "FaultDetected" 1 "Activated" 0 "Deactivated";
VAL_ 2566799614 RearFogLights 3 "NotAvailable" 2 "FaultDetected" 1 "Activated" 0 "Deactivated";
VAL_ 2566799614 TractorMarkerLight 3 "NotAvailable" 2 "FaultDetected" 1 "Activated" 0 "Deactivated";
VAL_ 2566799614 ImplementMarkerLight 3 "NotAvailable" 2 "FaultDetected" 1 "Activated" 0 "Deactivated";
VAL_ 2566799614 TractorClearanceLight 3 "NotAvailable" 2 "FaultDetected" 1 "Activated" 0 "Deactivated";
VAL_ 2566799614 ImplementClearanceLight 3 "NotAvailable" 2 "FaultDetected" 1 "Activated" 0 "Deactivated";
VAL_ 2566799614 LeftStopLight 3 "NotAvailable" 2 "FaultDetected" 1 "Activated" 0 "Deactivated";
VAL_ 2566799614 RightStopLight 3 "NotAvailable" 2 "FaultDetected" 1 "Activated" 0 "Deactivated";
VAL_ 2566799614 CenterStopLight 3 "NotAvailable" 2 "FaultDetected" 1 "Activated" 0 "Deactivated";
VAL_ 2566799614 BackUpLightAndAlarmHorn 3 "NotAvailable" 2 "FaultDetected" 1 "Activated" 0 "Deactivated";
VAL_ 2566799614 LeftTurnSignalLights 3 "NotAvailable" 2 "FaultDetected" 1 "Activated" 0 "Deactivated";
VAL_ 2566799614 RightTurnSignalLights 3 "NotAvailable" 2 "FaultDetected" 1 "Activated" 0 "Deactivated";
VAL_ 2566799614 RotatingBeaconLight 3 "NotAvailable" 2 "FaultDetected" 1 "Activated" 0 "Deactivated";
VAL_ 2566799614 TractorFrontFogLights 3 "NotAvailable" 2 "FaultDetected" 1 "Activated" 0 "Deactivated";
VAL_ 2566799614 HighBeamHeadLightData 3 "NotAvailable" 2 "FaultDetected" 1 "Activated" 0 "Deactivated";
VAL_ 2566799614 LowBeamHeadLightData 3 "NotAvailable" 2 "FaultDetected" 1 "Activated" 0 "Deactivated";
VAL_ 2566799614 AltBeamHeadLightData 3 "NotAvailable" 2 "FaultDetected" 1 "Activated" 0 "Deactivated";
VAL_ 2566799614 RunningLight 3 "NotAvailable" 2 "FaultDetected" 1 "Activated" 0 "Deactivated";
VAL_ 2365473278 ImplementRearWorkLightCmd 3 "DonTCare" 2 "Reserved" 1 "Activate" 0 "Deactivate";
VAL_ 2365473278 ImplmentLeftForwardWorkLightCmd 3 "DonTCare" 2 "Reserved" 1 "Activate" 0 "Deactivate";
VAL_ 2365473278 ImplmntRightForwardWorkLightCmd 3 "DonTCare" 2 "Reserved" 1 "Activate" 0 "Deactivate";
VAL_ 2365473278 LightingDataRqCmd 3 "DonTCare" 2 "Reserved" 1 "Activate" 0 "Deactivate";
VAL_ 2365473278 ImplementLeftFacingWorkLightCmd 3 "DonTCare" 2 "Reserved" 1 "Activate" 0 "Deactivate";
VAL_ 2365473278 ImplmentRightFacingWorkLightCmd 3 "DonTCare" 2 "Reserved" 1 "Activate" 0 "Deactivate";
VAL_ 2365473278 ImplementOEMOption1LightCmd 3 "DonTCare" 2 "Reserved" 1 "Activate" 0 "Deactivate";
VAL_ 2365473278 ImplementOEMOption2LightCmd 3 "DonTCare" 2 "Reserved" 1 "Activate" 0 "Deactivate";
VAL_ 2365473278 TrctrFrntHghMuntedWorkLightsCmd 3 "DonTCare" 2 "Reserved" 1 "Activate" 0 "Deactivate";
VAL_ 2365473278 TrctrFrntLwMountedWorkLightsCmd 3 "DonTCare" 2 "Reserved" 1 "Activate" 0 "Deactivate";
VAL_ 2365473278 TrctrSdHighMountedWorkLightsCmd 3 "DonTCare" 2 "Reserved" 1 "Activate" 0 "Deactivate";
VAL_ 2365473278 TrctrSdeLowMountedWorkLightsCmd 3 "DonTCare" 2 "Reserved" 1 "Activate" 0 "Deactivate";
VAL_ 2365473278 TrctrRrHighMountedWorkLightsCmd 3 "DonTCare" 2 "Reserved" 1 "Activate" 0 "Deactivate";
VAL_ 2365473278 TrctrRarLowMountedWorkLightsCmd 3 "DonTCare" 2 "Reserved" 1 "Activate" 0 "Deactivate";
VAL_ 2365473278 TrctrUndrsdMountedWorkLightsCmd 3 "DonTCare" 2 "Reserved" 1 "Activate" 0 "Deactivate";
VAL_ 2365473278 RearFogLightCmd 3 "DonTCare" 2 "Reserved" 1 "Activate" 0 "Deactivate";
VAL_ 2365473278 TractorMarkerLightCmd 3 "DonTCare" 2 "Reserved" 1 "Activate" 0 "Deactivate";
VAL_ 2365473278 ImplementMarkerLightCmd 3 "DonTCare" 2 "Reserved" 1 "Activate" 0 "Deactivate";
VAL_ 2365473278 TractorClearanceLightCmd 3 "DonTCare" 2 "Reserved" 1 "Activate" 0 "Deactivate";
VAL_ 2365473278 ImplementClearanceLightCmd 3 "DonTCare" 2 "Reserved" 1 "Activate" 0 "Deactivate";
VAL_ 2365473278 LeftStopLightCmd 3 "DonTCare" 2 "Reserved" 1 "Activate" 0 "Deactivate";
VAL_ 2365473278 RightStopLightCmd 3 "DonTCare" 2 "Reserved" 1 "Activate" 0 "Deactivate";
VAL_ 2365473278 CenterStopLightCmd 3 "DonTCare" 2 "Reserved" 1 "Activate" 0 "Deactivate";
VAL_ 2365473278 BackUpLightAndAlarmHornCmd 3 "DonTCare" 2 "Reserved" 1 "Activate" 0 "Deactivate";
VAL_ 2365473278 LeftTurnSignalLightsCmd 3 "DonTCare" 2 "Reserved" 1 "Activate" 0 "Deactivate";
VAL_ 2365473278 RightTurnSignalLightsCmd 3 "DonTCare" 2 "Reserved" 1 "Activate" 0 "Deactivate";
VAL_ 2365473278 RotatingBeaconLightCmd 3 "DonTCare" 2 "Reserved" 1 "Activate" 0 "Deactivate";
VAL_ 2365473278 TractorFrontFogLightsCmd 3 "DonTCare" 2 "Reserved" 1 "Activate" 0 "Deactivate";
VAL_ 2365473278 HighBeamHeadLightCmd 3 "DonTCare" 2 "Reserved" 1 "Activate" 0 "Deactivate";
VAL_ 2365473278 LowBeamHeadLightCmd 3 "DonTCare" 2 "Reserved" 1 "Activate" 0 "Deactivate";
VAL_ 2365473278 AltBeamHeadLightCmd 3 "DonTCare" 2 "Reserved" 1 "Activate" 0 "Deactivate";
VAL_ 2365473278 RunningLightCmd 3 "DonTCare" 2 "Reserved" 1 "Activate" 0 "Deactivate";
VAL_ 2365485822 BladeCtrlMode 2 "InactiveAutomaticMode" 1 "AutomaticMode" 0 "ManualMode";
VAL_ 2365485822 LandLevelingSystemEnableStatus 3 "NotAvailable_NotInstalled" 2 "Error" 1 "Enabled" 0 "Disabled";
VAL_ 2365485822 BladeCtrlModeRight 15 "NotAvailable" 14 "Error" 3 "1101Reserved" 2 "InactiveAuto" 1 "Auto" 0 "Manual";
VAL_ 2365485822 BladeCtrlModeLeft 15 "NotAvailable" 14 "Error" 3 "1101Reserved" 2 "InactiveAuto" 1 "Auto" 0 "Manual";
